VERSION "eCMP INFO-DIV vehicle review 2026-11-03; 125000 bit/s; PSA-RE 67f7581e7622410efdbb29c7eda3b86982b9b450; Apache-2.0"

NS_ :

BS_:

BU_: AAS AMPLI AVP BCM BGP BSG BSI BTA BTEL BTT CDC CMB CRT DIAG_TOOL EDP_C EMF FMUX IC ICSV IDVR IVC_D MATT MDS OVIP PDS_C RAD RBG SDCM VTH WLC

BO_ 808 ICSV_EngineEcuData: 8 ICSV
 SG_ FlowPadding5 m3 : 63|8@0+ (1,0) [0|255] "raw"  BSI,MATT,CMB
 SG_ FirstData6 m1 : 63|8@0+ (1,0) [0|255] "raw"  BSI,MATT,CMB
 SG_ UnknownData7 m4 : 63|8@0+ (1,0) [0|255] "raw"  BSI,MATT,CMB
 SG_ ConsecutiveData7 m2 : 63|8@0+ (1,0) [0|255] "raw"  BSI,MATT,CMB
 SG_ SingleData7 m0 : 63|8@0+ (1,0) [0|255] "raw"  BSI,MATT,CMB
 SG_ FlowPadding4 m3 : 55|8@0+ (1,0) [0|255] "raw"  BSI,MATT,CMB
 SG_ FirstData5 m1 : 55|8@0+ (1,0) [0|255] "raw"  BSI,MATT,CMB
 SG_ UnknownData6 m4 : 55|8@0+ (1,0) [0|255] "raw"  BSI,MATT,CMB
 SG_ ConsecutiveData6 m2 : 55|8@0+ (1,0) [0|255] "raw"  BSI,MATT,CMB
 SG_ SingleData6 m0 : 55|8@0+ (1,0) [0|255] "raw"  BSI,MATT,CMB
 SG_ FlowPadding3 m3 : 47|8@0+ (1,0) [0|255] "raw"  BSI,MATT,CMB
 SG_ FirstData4 m1 : 47|8@0+ (1,0) [0|255] "raw"  BSI,MATT,CMB
 SG_ UnknownData5 m4 : 47|8@0+ (1,0) [0|255] "raw"  BSI,MATT,CMB
 SG_ ConsecutiveData5 m2 : 47|8@0+ (1,0) [0|255] "raw"  BSI,MATT,CMB
 SG_ SingleData5 m0 : 47|8@0+ (1,0) [0|255] "raw"  BSI,MATT,CMB
 SG_ FlowPadding2 m3 : 39|8@0+ (1,0) [0|255] "raw"  BSI,MATT,CMB
 SG_ FirstData3 m1 : 39|8@0+ (1,0) [0|255] "raw"  BSI,MATT,CMB
 SG_ UnknownData4 m4 : 39|8@0+ (1,0) [0|255] "raw"  BSI,MATT,CMB
 SG_ ConsecutiveData4 m2 : 39|8@0+ (1,0) [0|255] "raw"  BSI,MATT,CMB
 SG_ SingleData4 m0 : 39|8@0+ (1,0) [0|255] "raw"  BSI,MATT,CMB
 SG_ FlowPadding1 m3 : 31|8@0+ (1,0) [0|255] "raw"  BSI,MATT,CMB
 SG_ FirstData2 m1 : 31|8@0+ (1,0) [0|255] "raw"  BSI,MATT,CMB
 SG_ UnknownData3 m4 : 31|8@0+ (1,0) [0|255] "raw"  BSI,MATT,CMB
 SG_ ConsecutiveData3 m2 : 31|8@0+ (1,0) [0|255] "raw"  BSI,MATT,CMB
 SG_ SingleData3 m0 : 31|8@0+ (1,0) [0|255] "raw"  BSI,MATT,CMB
 SG_ FirstData1 m1 : 23|8@0+ (1,0) [0|255] "raw"  BSI,MATT,CMB
 SG_ UnknownData2 m4 : 23|8@0+ (1,0) [0|255] "raw"  BSI,MATT,CMB
 SG_ ConsecutiveData2 m2 : 23|8@0+ (1,0) [0|255] "raw"  BSI,MATT,CMB
 SG_ SingleData2 m0 : 23|8@0+ (1,0) [0|255] "raw"  BSI,MATT,CMB
 SG_ SeparationTimeRaw m3 : 23|8@0+ (1,0) [0|255] "raw"  BSI,MATT,CMB
 SG_ UnknownData1 m4 : 15|8@0+ (1,0) [0|255] "raw"  BSI,MATT,CMB
 SG_ ConsecutiveData1 m2 : 15|8@0+ (1,0) [0|255] "raw"  BSI,MATT,CMB
 SG_ SingleData1 m0 : 15|8@0+ (1,0) [0|255] "raw"  BSI,MATT,CMB
 SG_ BlockSize m3 : 15|8@0+ (1,0) [0|255] "raw"  BSI,MATT,CMB
 SG_ UnknownPciLow m4 : 3|4@0+ (1,0) [0|15] "raw"  BSI,MATT,CMB
 SG_ FlowStatus m3 : 3|4@0+ (1,0) [0|15] "raw"  BSI,MATT,CMB
 SG_ ConsecutiveSequence m2 : 3|4@0+ (1,0) [0|15] "raw"  BSI,MATT,CMB
 SG_ FirstFrameLength m1 : 3|12@0+ (1,0) [0|4095] "raw"  BSI,MATT,CMB
 SG_ SingleFrameLength m0 : 3|4@0+ (1,0) [0|15] "raw"  BSI,MATT,CMB
 SG_ IsoTpFrameType M : 7|4@0+ (1,0) [0|15] ""  BSI,MATT,CMB

BO_ 809 BTEL_StopStartGearboxData: 8 BTEL
 SG_ RawByte8 : 63|8@0+ (1,0) [0|255] "raw" Vector__XXX
 SG_ RawByte7 : 55|8@0+ (1,0) [0|255] "raw" Vector__XXX
 SG_ Unused1 : 41|2@0+ (1,0) [0|3] ""  BSI,IDVR,AAS,RAD
 SG_ EnergyRecoveryButtonPressed : 42|1@0+ (1,0) [0|1] ""  BSI,IDVR,AAS,RAD
 SG_ AvasButtonPressed : 43|1@0+ (1,0) [0|1] ""  BSI,IDVR,AAS,RAD
 SG_ OutsideAirQualityBadLevel : 46|3@0+ (1,0) [0|7] ""  BSI,IDVR,AAS,RAD
 SG_ NightVisionToggleRequest : 47|1@0+ (1,0) [0|1] ""  BSI,IDVR,AAS,RAD
 SG_ AutomaticParkingSideRequest : 32|1@0+ (1,0) [0|1] ""  BSI,IDVR,AAS,RAD
 SG_ AutomaticParkingActivatio_012211 : 33|1@0+ (1,0) [0|1] ""  BSI,IDVR,AAS,RAD
 SG_ CabinAirFilterResetRequest : 34|1@0+ (1,0) [0|1] ""  BSI,IDVR,AAS,RAD
 SG_ CabinAirPurifierModeRequest : 37|3@0+ (1,0) [0|7] ""  BSI,IDVR,AAS,RAD
 SG_ OutsideAirQualityLevel : 39|2@0+ (1,0) [0|3] ""  BSI,IDVR,AAS,RAD
 SG_ AsrInhibitRequest : 24|1@0+ (1,0) [0|1] ""  BSI,IDVR,AAS,RAD
 SG_ ConsumptionHistoryZoomLevel : 26|2@0+ (1,0) [0|3] ""  BSI,IDVR,AAS,RAD
 SG_ ConsumptionHistoryResetRequest : 27|1@0+ (1,0) [0|1] ""  BSI,IDVR,AAS,RAD
 SG_ DynamicModeTouchSelection : 31|4@0+ (1,0) [0|15] ""  BSI,IDVR,AAS,RAD
 SG_ EcoachTripResetRequest : 16|1@0+ (1,0) [0|1] ""  BSI,IDVR,AAS,RAD
 SG_ MassageActivationCommand : 17|1@0+ (1,0) [0|1] ""  BSI,IDVR,AAS,RAD
 SG_ MassageIntensityCommand : 19|2@0+ (1,0) [0|3] ""  BSI,IDVR,AAS,RAD
 SG_ MassageTypeCommand : 23|4@0+ (1,0) [0|15] ""  BSI,IDVR,AAS,RAD
 SG_ FrontMassageSeatSelectionCommand : 9|2@0+ (1,0) [0|3] ""  BSI,IDVR,AAS,RAD
 SG_ FragranceSelectionRequest : 11|2@0+ (1,0) [0|3] ""  BSI,IDVR,AAS,RAD
 SG_ FragranceIntensityRequest : 13|2@0+ (1,0) [0|3] ""  BSI,IDVR,AAS,RAD
 SG_ FragranceDiffuserActivati_99a752 : 15|2@0+ (1,0) [0|3] ""  BSI,IDVR,AAS,RAD
 SG_ FragranceCartridgeMonoStatus : 1|2@0+ (1,0) [0|3] ""  BSI,IDVR,AAS,RAD
 SG_ IonizerActivationRequest : 3|2@0+ (1,0) [0|3] ""  BSI,IDVR,AAS,RAD
 SG_ LkaButtonPressed : 4|1@0+ (1,0) [0|1] ""  BSI,IDVR,AAS,RAD
 SG_ AsrPlusModeSelection : 6|2@0+ (1,0) [0|3] ""  BSI,IDVR,AAS,RAD
 SG_ FunctionSelectionRequest : 7|1@0+ (1,0) [0|1] ""  BSI,IDVR,AAS,RAD

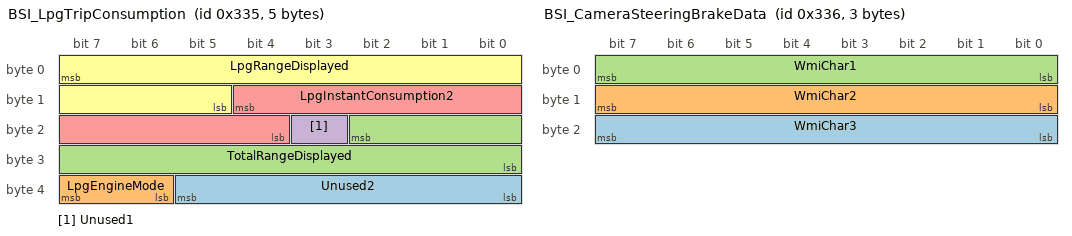
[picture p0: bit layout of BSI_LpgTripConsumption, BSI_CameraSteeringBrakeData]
BO_ 821 BSI_LpgTripConsumption: 5 BSI
 SG_ Unused2 : 37|6@0+ (1,0) [0|63] ""  BTEL,CMB,MATT
 SG_ LpgEngineMode : 39|2@0+ (1,0) [0|3] ""  BTEL,CMB,MATT
 SG_ TotalRangeDisplayed : 18|11@0+ (1,0) [0|2000] "km"  BTEL,CMB,MATT
 SG_ Unused1 : 19|1@0+ (1,0) [0|1] ""  BTEL,CMB,MATT
 SG_ LpgInstantConsumption2 : 12|9@0+ (0.1,0) [0|30] "L/100km"  BTEL,CMB,MATT
 SG_ LpgRangeDisplayed : 7|11@0+ (1,0) [0|2000] "km"  BTEL,CMB,MATT

BO_ 822 BSI_CameraSteeringBrakeData: 3 BSI
 SG_ WmiChar3 : 23|8@0+ (1,0) [0|255] "raw"  BTEL,CMB,EMF,CDC,RAD,MDS,MATT,BGP,OVIP
 SG_ WmiChar2 : 15|8@0+ (1,0) [0|255] "raw"  BTEL,CMB,EMF,CDC,RAD,MDS,MATT,BGP,OVIP
 SG_ WmiChar1 : 7|8@0+ (1,0) [0|255] "raw"  BTEL,CMB,EMF,CDC,RAD,MDS,MATT,BGP,OVIP

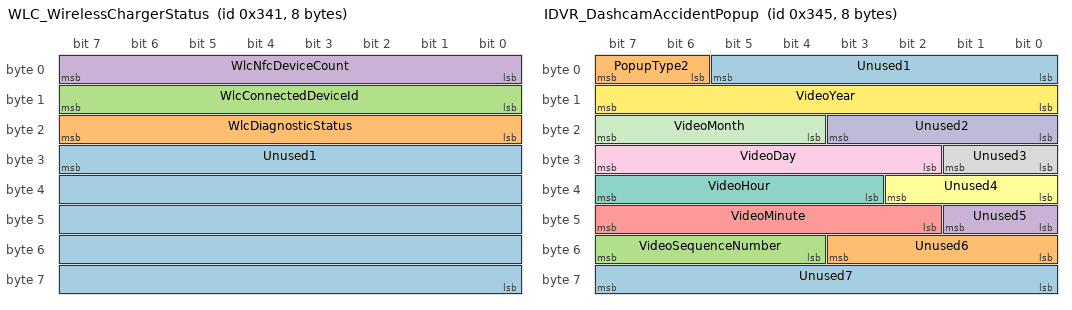
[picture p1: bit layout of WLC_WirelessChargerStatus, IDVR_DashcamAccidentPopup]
BO_ 833 WLC_WirelessChargerStatus: 8 WLC
 SG_ Unused1 : 31|40@0+ (1,0) [0|1099511627775] ""  SDCM
 SG_ WlcDiagnosticStatus : 23|8@0+ (1,0) [0|255] ""  SDCM
 SG_ WlcConnectedDeviceId : 15|8@0+ (1,0) [0|255] ""  SDCM
 SG_ WlcNfcDeviceCount : 7|8@0+ (1,0) [0|255] ""  SDCM

BO_ 835 BTEL_OdiDynamicDataListRe_1b7878: 8 BTEL
 SG_ OdiDynDataListRequestCent_4a34c1 : 7|64@0+ (1,0) [0|18446744073709551615] ""  MDS

BO_ 837 IDVR_DashcamAccidentPopup: 8 IDVR
 SG_ Unused7 : 63|8@0+ (1,0) [0|255] ""  BTEL,OVIP
 SG_ Unused6 : 51|4@0+ (1,0) [0|15] ""  BTEL,OVIP
 SG_ VideoSequenceNumber : 55|4@0+ (1,0) [0|9] ""  BTEL,OVIP
 SG_ Unused5 : 41|2@0+ (1,0) [0|3] ""  BTEL,OVIP
 SG_ VideoMinute : 47|6@0+ (1,0) [0|59] ""  BTEL,OVIP
 SG_ Unused4 : 34|3@0+ (1,0) [0|7] ""  BTEL,OVIP
 SG_ VideoHour : 39|5@0+ (1,0) [0|24] ""  BTEL,OVIP
 SG_ Unused3 : 25|2@0+ (1,0) [0|3] ""  BTEL,OVIP
 SG_ VideoDay : 31|6@0+ (1,0) [1|31] "day"  BTEL,OVIP
 SG_ Unused2 : 19|4@0+ (1,0) [0|15] ""  BTEL,OVIP
 SG_ VideoMonth : 23|4@0+ (1,0) [1|12] "month"  BTEL,OVIP
 SG_ VideoYear : 15|8@0+ (1,2000) [2000|2254] "year"  BTEL,OVIP
 SG_ Unused1 : 5|6@0+ (1,0) [0|63] ""  BTEL,OVIP
 SG_ PopupType2 : 7|2@0+ (1,0) [0|3] ""  BTEL,OVIP

BO_ 848 ICSV_FrontClimateStatus: 8 ICSV
 SG_ Unused1 : 56|1@0+ (1,0) [0|1] ""  CMB,BSI,BTEL,OVIP,CRT,RAD
 SG_ FrontRightSeatVentilationRequest : 58|2@0+ (1,0) [0|3] ""  CMB,BSI,BTEL,OVIP,CRT,RAD
 SG_ FrontLeftSeatHeatingRequest : 60|2@0+ (1,0) [0|3] ""  CMB,BSI,BTEL,OVIP,CRT,RAD
 SG_ FrontRightSeatHeatingRequest : 62|2@0+ (1,0) [0|3] ""  CMB,BSI,BTEL,OVIP,CRT,RAD
 SG_ EnergySaverModeStatus : 63|1@0+ (1,0) [0|1] ""  CMB,BSI,BTEL,OVIP,CRT,RAD
 SG_ FrontRightAirflowDistribution : 51|4@0+ (1,0) [0|15] ""  CMB,BSI,BTEL,OVIP,CRT,RAD
 SG_ FrontLeftAirflowDistribution : 55|4@0+ (1,0) [0|15] ""  CMB,BSI,BTEL,OVIP,CRT,RAD
 SG_ FrontBlowerManualSpeedDisplay : 43|4@0+ (1,0) [0|15] ""  CMB,BSI,BTEL,OVIP,CRT,RAD
 SG_ Mode : 46|3@0+ (1,0) [0|7] ""  CMB,BSI,BTEL,OVIP,CRT,RAD
 SG_ AqsStatus : 47|1@0+ (1,0) [0|1] ""  CMB,BSI,BTEL,OVIP,CRT,RAD
 SG_ FrontRightTempSetpointValue : 36|5@0+ (1,0) [0|31] ""  CMB,BSI,BTEL,OVIP,CRT,RAD
 SG_ FrontLeftSeatVentilationRequest : 38|2@0+ (1,0) [0|3] ""  CMB,BSI,BTEL,OVIP,CRT,RAD
 SG_ HeatedWindscreenActivatio_b0408e : 39|1@0+ (1,0) [0|1] ""  CMB,BSI,BTEL,OVIP,CRT,RAD
 SG_ FrontLeftTempSetpointValue : 28|5@0+ (1,0) [0|31] ""  CMB,BSI,BTEL,OVIP,CRT,RAD
 SG_ RestoreFlagStatus : 29|1@0+ (1,0) [0|1] ""  CMB,BSI,BTEL,OVIP,CRT,RAD
 SG_ MonoModeStatus : 30|1@0+ (1,0) [0|1] ""  CMB,BSI,BTEL,OVIP,CRT,RAD
 SG_ AcMaxStatus : 31|1@0+ (1,0) [0|1] ""  CMB,BSI,BTEL,OVIP,CRT,RAD
 SG_ EvaporatorSensorTemperature : 15|16@0+ (0.1,-40) [-40|85] ""  CMB,BSI,BTEL,OVIP,CRT,RAD
 SG_ AcType : 1|2@0+ (1,0) [0|3] ""  CMB,BSI,BTEL,OVIP,CRT,RAD
 SG_ AcModeRequest : 3|2@0+ (1,0) [0|3] ""  CMB,BSI,BTEL,OVIP,CRT,RAD
 SG_ VisibilityRequest : 4|1@0+ (1,0) [0|1] ""  CMB,BSI,BTEL,OVIP,CRT,RAD
 SG_ RearWindshieldHeat : 5|1@0+ (1,0) [0|1] ""  CMB,BSI,BTEL,OVIP,CRT,RAD
 SG_ RestModeStatus : 6|1@0+ (1,0) [0|1] ""  CMB,BSI,BTEL,OVIP,CRT,RAD
 SG_ FrontBlowerMotorFault : 7|1@0+ (1,0) [0|1] ""  CMB,BSI,BTEL,OVIP,CRT,RAD

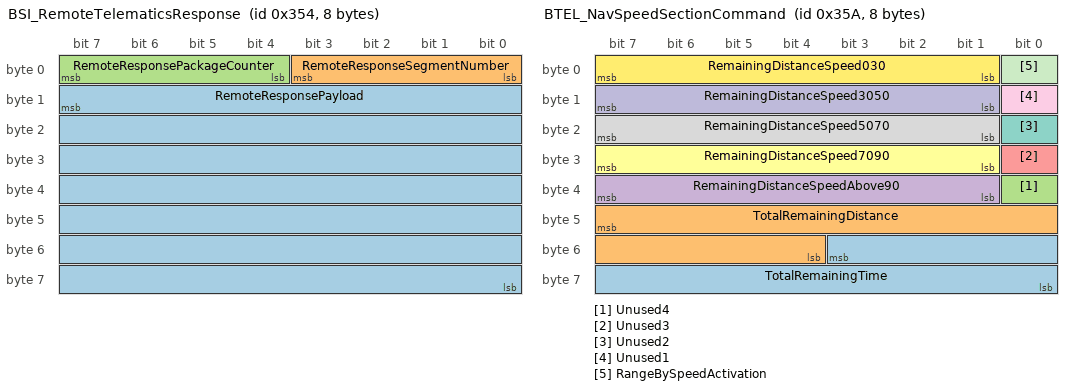
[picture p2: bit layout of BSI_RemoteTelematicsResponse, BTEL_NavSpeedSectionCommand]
BO_ 852 BSI_RemoteTelematicsResponse: 8 BSI
 SG_ RemoteResponsePayload : 15|56@0+ (1,0) [0|72057594037927935] ""  MDS
 SG_ RemoteResponseSegmentNumber : 3|4@0+ (1,0) [0|15] ""  MDS
 SG_ RemoteResponsePackageCounter : 7|4@0+ (1,0) [0|15] ""  MDS

BO_ 858 BTEL_NavSpeedSectionCommand: 8 BTEL
 SG_ TotalRemainingTime : 51|12@0+ (1,0) [0|4095] "min"  BSI
 SG_ TotalRemainingDistance : 47|12@0+ (1,0) [0|4095] "km"  BSI
 SG_ Unused4 : 32|1@0+ (1,0) [0|1] ""  BSI
 SG_ RemainingDistanceSpeedAbove90 : 39|7@0+ (1,0) [0|100] "%"  BSI
 SG_ Unused3 : 24|1@0+ (1,0) [0|1] ""  BSI
 SG_ RemainingDistanceSpeed7090 : 31|7@0+ (1,0) [0|100] "%"  BSI
 SG_ Unused2 : 16|1@0+ (1,0) [0|1] ""  BSI
 SG_ RemainingDistanceSpeed5070 : 23|7@0+ (1,0) [0|100] "%"  BSI
 SG_ Unused1 : 8|1@0+ (1,0) [0|1] ""  BSI
 SG_ RemainingDistanceSpeed3050 : 15|7@0+ (1,0) [0|100] "%"  BSI
 SG_ RangeBySpeedActivation : 0|1@0+ (1,0) [0|1] ""  BSI
 SG_ RemainingDistanceSpeed030 : 7|7@0+ (1,0) [0|100] "%"  BSI

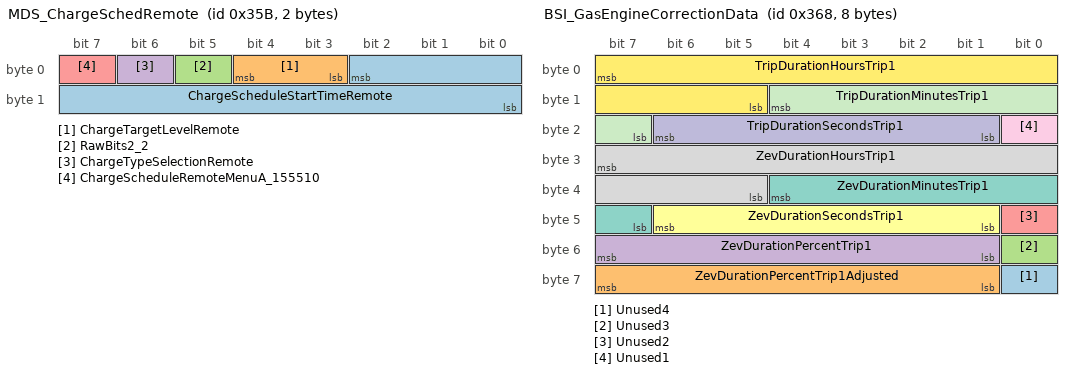
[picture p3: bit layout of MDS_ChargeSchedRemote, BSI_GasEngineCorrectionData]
BO_ 859 MDS_ChargeSchedRemote: 2 MDS
 SG_ ChargeScheduleStartTimeRemote : 2|11@0+ (1,0) [0|1440] "min"  BSI
 SG_ ChargeTargetLevelRemote : 4|2@0+ (1,0) [0|3] ""  BSI
 SG_ RawBits2_2 : 5|1@0+ (1,0) [0|1] "raw" Vector__XXX
 SG_ ChargeTypeSelectionRemote : 6|1@0+ (1,0) [0|1] ""  BSI
 SG_ ChargeScheduleRemoteMenuA_155510 : 7|1@0+ (1,0) [0|1] ""  BSI

BO_ 863 EMF_NavDatabaseStatusAckRep: 1 EMF
 SG_ SegmentationAckStream : 7|8@0+ (1,0) [0|255] ""  RAD

BO_ 864 ICSV_VehicleParameterData: 8 ICSV
 SG_ FlowPadding5 m3 : 63|8@0+ (1,0) [0|255] "raw"  BTEL,OVIP
 SG_ FirstData6 m1 : 63|8@0+ (1,0) [0|255] "raw"  BTEL,OVIP
 SG_ UnknownData7 m4 : 63|8@0+ (1,0) [0|255] "raw"  BTEL,OVIP
 SG_ ConsecutiveData7 m2 : 63|8@0+ (1,0) [0|255] "raw"  BTEL,OVIP
 SG_ SingleData7 m0 : 63|8@0+ (1,0) [0|255] "raw"  BTEL,OVIP
 SG_ FlowPadding4 m3 : 55|8@0+ (1,0) [0|255] "raw"  BTEL,OVIP
 SG_ FirstData5 m1 : 55|8@0+ (1,0) [0|255] "raw"  BTEL,OVIP
 SG_ UnknownData6 m4 : 55|8@0+ (1,0) [0|255] "raw"  BTEL,OVIP
 SG_ ConsecutiveData6 m2 : 55|8@0+ (1,0) [0|255] "raw"  BTEL,OVIP
 SG_ SingleData6 m0 : 55|8@0+ (1,0) [0|255] "raw"  BTEL,OVIP
 SG_ FlowPadding3 m3 : 47|8@0+ (1,0) [0|255] "raw"  BTEL,OVIP
 SG_ FirstData4 m1 : 47|8@0+ (1,0) [0|255] "raw"  BTEL,OVIP
 SG_ UnknownData5 m4 : 47|8@0+ (1,0) [0|255] "raw"  BTEL,OVIP
 SG_ ConsecutiveData5 m2 : 47|8@0+ (1,0) [0|255] "raw"  BTEL,OVIP
 SG_ SingleData5 m0 : 47|8@0+ (1,0) [0|255] "raw"  BTEL,OVIP
 SG_ FlowPadding2 m3 : 39|8@0+ (1,0) [0|255] "raw"  BTEL,OVIP
 SG_ FirstData3 m1 : 39|8@0+ (1,0) [0|255] "raw"  BTEL,OVIP
 SG_ UnknownData4 m4 : 39|8@0+ (1,0) [0|255] "raw"  BTEL,OVIP
 SG_ ConsecutiveData4 m2 : 39|8@0+ (1,0) [0|255] "raw"  BTEL,OVIP
 SG_ SingleData4 m0 : 39|8@0+ (1,0) [0|255] "raw"  BTEL,OVIP
 SG_ FlowPadding1 m3 : 31|8@0+ (1,0) [0|255] "raw"  BTEL,OVIP
 SG_ FirstData2 m1 : 31|8@0+ (1,0) [0|255] "raw"  BTEL,OVIP
 SG_ UnknownData3 m4 : 31|8@0+ (1,0) [0|255] "raw"  BTEL,OVIP
 SG_ ConsecutiveData3 m2 : 31|8@0+ (1,0) [0|255] "raw"  BTEL,OVIP
 SG_ SingleData3 m0 : 31|8@0+ (1,0) [0|255] "raw"  BTEL,OVIP
 SG_ FirstData1 m1 : 23|8@0+ (1,0) [0|255] "raw"  BTEL,OVIP
 SG_ UnknownData2 m4 : 23|8@0+ (1,0) [0|255] "raw"  BTEL,OVIP
 SG_ ConsecutiveData2 m2 : 23|8@0+ (1,0) [0|255] "raw"  BTEL,OVIP
 SG_ SingleData2 m0 : 23|8@0+ (1,0) [0|255] "raw"  BTEL,OVIP
 SG_ SeparationTimeRaw m3 : 23|8@0+ (1,0) [0|255] "raw"  BTEL,OVIP
 SG_ UnknownData1 m4 : 15|8@0+ (1,0) [0|255] "raw"  BTEL,OVIP
 SG_ ConsecutiveData1 m2 : 15|8@0+ (1,0) [0|255] "raw"  BTEL,OVIP
 SG_ SingleData1 m0 : 15|8@0+ (1,0) [0|255] "raw"  BTEL,OVIP
 SG_ BlockSize m3 : 15|8@0+ (1,0) [0|255] "raw"  BTEL,OVIP
 SG_ UnknownPciLow m4 : 3|4@0+ (1,0) [0|15] "raw"  BTEL,OVIP
 SG_ FlowStatus m3 : 3|4@0+ (1,0) [0|15] "raw"  BTEL,OVIP
 SG_ ConsecutiveSequence m2 : 3|4@0+ (1,0) [0|15] "raw"  BTEL,OVIP
 SG_ FirstFrameLength m1 : 3|12@0+ (1,0) [0|4095] "raw"  BTEL,OVIP
 SG_ SingleFrameLength m0 : 3|4@0+ (1,0) [0|15] "raw"  BTEL,OVIP
 SG_ IsoTpFrameType M : 7|4@0+ (1,0) [0|15] ""  BTEL,OVIP

BO_ 865 BSI_VehicleFeatureAvailability: 8 BSI
 SG_ RawByte8 : 63|8@0+ (1,0) [0|255] "raw" Vector__XXX
 SG_ Unused2 : 48|1@0+ (1,0) [0|1] ""  CMB,EMF,BTEL,MATT,OVIP,MDS,RAD
 SG_ RtabRechargeMenuDisplayAu_d73943 : 49|1@0+ (1,0) [0|1] ""  CMB,EMF,BTEL,MATT,OVIP,MDS,RAD
 SG_ ClimatePrecondMenuDisplay_2fd6ce : 50|1@0+ (1,0) [0|1] ""  CMB,EMF,BTEL,MATT,OVIP,MDS,RAD
 SG_ AmlaMenuPresence : 51|1@0+ (1,0) [0|1] ""  CMB,EMF,BTEL,MATT,OVIP,MDS,RAD
 SG_ AdsdMenuPresence : 52|1@0+ (1,0) [0|1] ""  CMB,EMF,BTEL,MATT,OVIP,MDS,RAD
 SG_ PrivacyModeMenuPresence : 53|1@0+ (1,0) [0|1] ""  CMB,EMF,BTEL,MATT,OVIP,MDS,RAD
 SG_ ArsMenuPresence : 54|1@0+ (1,0) [0|1] ""  CMB,EMF,BTEL,MATT,OVIP,MDS,RAD
 SG_ AfsMenuPresence : 55|1@0+ (1,0) [0|1] ""  CMB,EMF,BTEL,MATT,OVIP,MDS,RAD
 SG_ IrvMenuPresence : 40|1@0+ (1,0) [0|1] ""  CMB,EMF,BTEL,MATT,OVIP,MDS,RAD
 SG_ PolychromePackBlockMenuPresence : 41|1@0+ (1,0) [0|1] ""  CMB,EMF,BTEL,MATT,OVIP,MDS,RAD
 SG_ PpcAnimationPresence : 42|1@0+ (1,0) [0|1] ""  CMB,EMF,BTEL,MATT,OVIP,MDS,RAD
 SG_ Dae4wdPresence : 43|1@0+ (1,0) [0|1] ""  CMB,EMF,BTEL,MATT,OVIP,MDS,RAD
 SG_ DaePresence : 44|1@0+ (1,0) [0|1] ""  CMB,EMF,BTEL,MATT,OVIP,MDS,RAD
 SG_ CafrMenuPresence : 45|1@0+ (1,0) [0|1] ""  CMB,EMF,BTEL,MATT,OVIP,MDS,RAD
 SG_ EcsModeMenuPresence : 46|1@0+ (1,0) [0|1] ""  CMB,EMF,BTEL,MATT,OVIP,MDS,RAD
 SG_ DriverAlertAssistMenuPresence : 47|1@0+ (1,0) [0|1] ""  CMB,EMF,BTEL,MATT,OVIP,MDS,RAD
 SG_ LoadedArmsLockMenuPresence : 32|1@0+ (1,0) [0|1] ""  CMB,EMF,BTEL,MATT,OVIP,MDS,RAD
 SG_ UserProfilePresence : 33|1@0+ (1,0) [0|1] ""  CMB,EMF,BTEL,MATT,OVIP,MDS,RAD
 SG_ LoadedArmsAccessMenuPresence : 34|1@0+ (1,0) [0|1] ""  CMB,EMF,BTEL,MATT,OVIP,MDS,RAD
 SG_ IlvPresence : 35|1@0+ (1,0) [0|1] ""  CMB,EMF,BTEL,MATT,OVIP,MDS,RAD
 SG_ GrilleLightingPresence : 36|1@0+ (1,0) [0|1] ""  CMB,EMF,BTEL,MATT,OVIP,MDS,RAD
 SG_ LowCurrentChargePresence : 37|1@0+ (1,0) [0|1] ""  CMB,EMF,BTEL,MATT,OVIP,MDS,RAD
 SG_ Unused1 : 39|2@0+ (1,0) [0|3] ""  CMB,EMF,BTEL,MATT,OVIP,MDS,RAD
 SG_ TpmsPresence : 26|3@0+ (1,0) [0|7] ""  CMB,EMF,BTEL,MATT,OVIP,MDS,RAD
 SG_ IrcPresence : 27|1@0+ (1,0) [0|1] ""  CMB,EMF,BTEL,MATT,OVIP,MDS,RAD
 SG_ XvvSpeedMenuPresence : 28|1@0+ (1,0) [0|1] ""  CMB,EMF,BTEL,MATT,OVIP,MDS,RAD
 SG_ ArcSensitivityMenuPresence : 29|1@0+ (1,0) [0|1] ""  CMB,EMF,BTEL,MATT,OVIP,MDS,RAD
 SG_ CollisionRiskBrakingOptio_4c4434 : 30|1@0+ (1,0) [0|1] ""  CMB,EMF,BTEL,MATT,OVIP,MDS,RAD
 SG_ TpmsReinitializationOptio_aa6f62 : 31|1@0+ (1,0) [0|1] ""  CMB,EMF,BTEL,MATT,OVIP,MDS,RAD
 SG_ PpcPresence : 16|1@0+ (1,0) [0|1] ""  CMB,EMF,BTEL,MATT,OVIP,MDS,RAD
 SG_ EtsrMenuPresence : 17|1@0+ (1,0) [0|1] ""  CMB,EMF,BTEL,MATT,OVIP,MDS,RAD
 SG_ ReverseIndexingPresence : 18|1@0+ (1,0) [0|1] ""  CMB,EMF,BTEL,MATT,OVIP,MDS,RAD
 SG_ SoundHarmonyOptionPresence : 19|1@0+ (1,0) [0|1] ""  CMB,EMF,BTEL,MATT,OVIP,MDS,RAD
 SG_ ElectricParkingBrakeOptio_c6beca : 20|1@0+ (1,0) [0|1] ""  CMB,EMF,BTEL,MATT,OVIP,MDS,RAD
 SG_ CongigurableKeyOption : 21|1@0+ (1,0) [0|1] ""  CMB,EMF,BTEL,MATT,OVIP,MDS,RAD
 SG_ XvvLimitsMenuPresence : 22|1@0+ (1,0) [0|1] ""  CMB,EMF,BTEL,MATT,OVIP,MDS,RAD
 SG_ NblPresence : 23|1@0+ (1,0) [0|1] ""  CMB,EMF,BTEL,MATT,OVIP,MDS,RAD
 SG_ CabOpeningsSelectivityCus_fd4768 : 8|1@0+ (1,0) [0|1] ""  CMB,EMF,BTEL,MATT,OVIP,MDS,RAD
 SG_ DoorSelectivityOptionPresence : 9|1@0+ (1,0) [0|1] ""  CMB,EMF,BTEL,MATT,OVIP,MDS,RAD
 SG_ RearOpeningsSelectivityOp_53876f : 10|1@0+ (1,0) [0|1] ""  CMB,EMF,BTEL,MATT,OVIP,MDS,RAD
 SG_ RearFlapMotorizationCusto_5e7171 : 11|1@0+ (1,0) [0|1] ""  CMB,EMF,BTEL,MATT,OVIP,MDS,RAD
 SG_ DriverGreetingPresence : 12|1@0+ (1,0) [0|1] ""  CMB,EMF,BTEL,MATT,OVIP,MDS,RAD
 SG_ FollowMeHomeOptionPresence : 13|1@0+ (1,0) [0|1] ""  CMB,EMF,BTEL,MATT,OVIP,MDS,RAD
 SG_ RearWiperInReverseOptionPresence : 14|1@0+ (1,0) [0|1] ""  CMB,EMF,BTEL,MATT,OVIP,MDS,RAD
 SG_ ParkingAidInhibitionOptio_937dc5 : 15|1@0+ (1,0) [0|1] ""  CMB,EMF,BTEL,MATT,OVIP,MDS,RAD
 SG_ DaylightsOptionPresence : 0|1@0+ (1,0) [0|1] ""  CMB,EMF,BTEL,MATT,OVIP,MDS,RAD
 SG_ AutomaticHeadlightsSwitch_2a5f4f : 1|1@0+ (1,0) [0|1] ""  CMB,EMF,BTEL,MATT,OVIP,MDS,RAD
 SG_ AmbientLightingPresence : 2|1@0+ (1,0) [0|1] ""  CMB,EMF,BTEL,MATT,OVIP,MDS,RAD
 SG_ BlindSpotMonitoringPresence : 3|1@0+ (1,0) [0|1] ""  CMB,EMF,BTEL,MATT,OVIP,MDS,RAD
 SG_ AdaptiveLightingOptionPresence : 4|1@0+ (1,0) [0|1] ""  CMB,EMF,BTEL,MATT,OVIP,MDS,RAD
 SG_ UnlockingLightingCustomiz_78a725 : 5|1@0+ (1,0) [0|1] ""  CMB,EMF,BTEL,MATT,OVIP,MDS,RAD
 SG_ MotorwayLightingFunctionPresence : 6|1@0+ (1,0) [0|1] ""  CMB,EMF,BTEL,MATT,OVIP,MDS,RAD
 SG_ SettingsMenuInfoAvailability : 7|1@0+ (1,0) [0|1] ""  CMB,EMF,BTEL,MATT,OVIP,MDS,RAD

BO_ 868 BTEL_TouchClimatePanelStatus: 7 BTEL
 SG_ RawByte7 : 55|8@0+ (1,0) [0|255] "raw" Vector__XXX
 SG_ Unused1 : 43|4@0+ (1,0) [0|15] ""  ICSV,CMB,FMUX,BSI
 SG_ FrontLeftSeatVentilationButton : 44|1@0+ (1,0) [0|1] ""  ICSV,CMB,FMUX,BSI
 SG_ FrontRightSeatVentilationButton : 45|1@0+ (1,0) [0|1] ""  ICSV,CMB,FMUX,BSI
 SG_ FrontLeftSeatHeaterButton : 46|1@0+ (1,0) [0|1] ""  ICSV,CMB,FMUX,BSI
 SG_ FrontRightSeatHeaterButton : 47|1@0+ (1,0) [0|1] ""  ICSV,CMB,FMUX,BSI
 SG_ AcOffButton : 32|1@0+ (1,0) [0|1] ""  ICSV,CMB,FMUX,BSI
 SG_ ClimateSliderLevelChange : 33|1@0+ (1,0) [0|1] ""  ICSV,CMB,FMUX,BSI
 SG_ RearClimateLockButton : 34|1@0+ (1,0) [0|1] ""  ICSV,CMB,FMUX,BSI
 SG_ FrontRightDefrostButton : 35|1@0+ (1,0) [0|1] ""  ICSV,CMB,FMUX,BSI
 SG_ FrontFanLevelSlider : 39|4@0+ (1,0) [0|15] ""  ICSV,CMB,FMUX,BSI
 SG_ FrontRightVentAirflowButton : 24|1@0+ (1,0) [0|1] ""  ICSV,CMB,FMUX,BSI
 SG_ FrontRightFootAirflowButton : 25|1@0+ (1,0) [0|1] ""  ICSV,CMB,FMUX,BSI
 SG_ FrontRightTempLevelSlider : 30|5@0+ (1,0) [0|31] ""  ICSV,CMB,FMUX,BSI
 SG_ EnergySaverModeButton : 31|1@0+ (1,0) [0|1] ""  ICSV,CMB,FMUX,BSI
 SG_ FrontLeftTempSetpoint : 20|5@0+ (1,0) [0|31] ""  ICSV,CMB,FMUX,BSI
 SG_ RearClimateOnoffButton : 21|1@0+ (1,0) [0|1] ""  ICSV,CMB,FMUX,BSI
 SG_ AcMaxButton : 22|1@0+ (1,0) [0|1] ""  ICSV,CMB,FMUX,BSI
 SG_ AcAutoStrongButton : 23|1@0+ (1,0) [0|1] ""  ICSV,CMB,FMUX,BSI
 SG_ AcAutoNormalButton : 8|1@0+ (1,0) [0|1] ""  ICSV,CMB,FMUX,BSI
 SG_ AcAutoLightButton : 9|1@0+ (1,0) [0|1] ""  ICSV,CMB,FMUX,BSI
 SG_ AcAutoButton : 10|1@0+ (1,0) [0|1] ""  ICSV,CMB,FMUX,BSI
 SG_ AcButton : 11|1@0+ (1,0) [0|1] ""  ICSV,CMB,FMUX,BSI
 SG_ MonoZoneButton : 12|1@0+ (1,0) [0|1] ""  ICSV,CMB,FMUX,BSI
 SG_ AirQualitySensorButton : 13|1@0+ (1,0) [0|1] ""  ICSV,CMB,FMUX,BSI
 SG_ AirIntakeButton : 14|1@0+ (1,0) [0|1] ""  ICSV,CMB,FMUX,BSI
 SG_ FrontLeftDefrostButton : 15|1@0+ (1,0) [0|1] ""  ICSV,CMB,FMUX,BSI
 SG_ FrontLeftVentAirflowButton : 0|1@0+ (1,0) [0|1] ""  ICSV,CMB,FMUX,BSI
 SG_ FrontLeftFootAirflowButton : 1|1@0+ (1,0) [0|1] ""  ICSV,CMB,FMUX,BSI
 SG_ FrontFanMinusButton : 2|1@0+ (1,0) [0|1] ""  ICSV,CMB,FMUX,BSI
 SG_ FrontFanPlusButton : 3|1@0+ (1,0) [0|1] ""  ICSV,CMB,FMUX,BSI
 SG_ FrontRightTempMinusButton : 4|1@0+ (1,0) [0|1] ""  ICSV,CMB,FMUX,BSI
 SG_ FrontRightTempPlusButton : 5|1@0+ (1,0) [0|1] ""  ICSV,CMB,FMUX,BSI
 SG_ FrontLeftTempMinusButton : 6|1@0+ (1,0) [0|1] ""  ICSV,CMB,FMUX,BSI
 SG_ FrontLeftTempPlusButton : 7|1@0+ (1,0) [0|1] ""  ICSV,CMB,FMUX,BSI

BO_ 871 EMF_RadioStatusAckRep: 1 EMF
 SG_ SegmentationAckStream : 7|8@0+ (1,0) [0|255] ""  RAD

BO_ 872 BSI_GasEngineCorrectionData: 8 BSI
 SG_ Unused4 : 56|1@0+ (1,0) [0|1] ""  OVIP,RAD
 SG_ ZevDurationPercentTrip1Adjusted : 63|7@0+ (1,0) [0|100] "%"  OVIP,RAD
 SG_ Unused3 : 48|1@0+ (1,0) [0|1] ""  OVIP,RAD
 SG_ ZevDurationPercentTrip1 : 55|7@0+ (1,0) [0|100] "%"  OVIP,RAD
 SG_ Unused2 : 40|1@0+ (1,0) [0|1] ""  OVIP,RAD
 SG_ ZevDurationSecondsTrip1 : 46|6@0+ (1,0) [0|59] "s"  OVIP,RAD
 SG_ ZevDurationMinutesTrip1 : 36|6@0+ (1,0) [0|59] "min"  OVIP,RAD
 SG_ ZevDurationHoursTrip1 : 31|11@0+ (1,0) [0|2000] "h"  OVIP,RAD
 SG_ Unused1 : 16|1@0+ (1,0) [0|1] ""  OVIP,RAD
 SG_ TripDurationSecondsTrip1 : 22|6@0+ (1,0) [0|59] "s"  OVIP,RAD
 SG_ TripDurationMinutesTrip1 : 12|6@0+ (1,0) [0|59] "min"  OVIP,RAD
 SG_ TripDurationHoursTrip1 : 7|11@0+ (1,0) [0|2000] "h"  OVIP,RAD

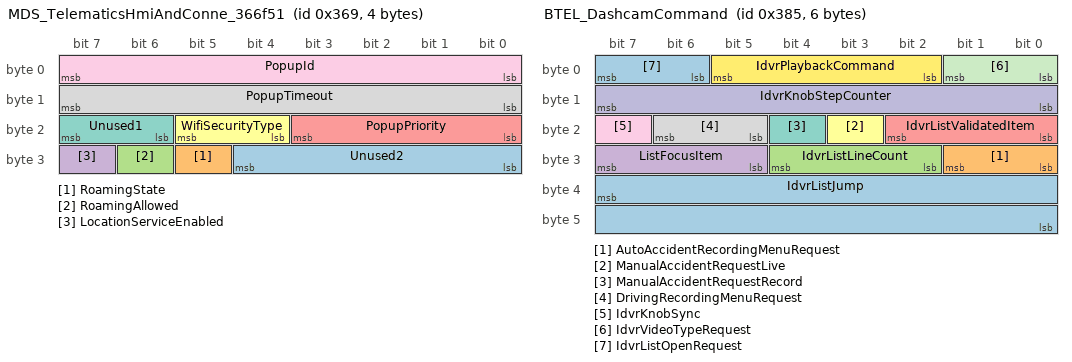
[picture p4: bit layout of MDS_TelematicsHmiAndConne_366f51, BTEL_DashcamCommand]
BO_ 873 MDS_TelematicsHmiAndConne_366f51: 4 MDS
 SG_ Unused2 : 28|5@0+ (1,0) [0|31] ""  BTEL,EMF,OVIP,BSI,RAD
 SG_ RoamingState : 29|1@0+ (1,0) [0|1] ""  BTEL,EMF,OVIP,BSI,RAD
 SG_ RoamingAllowed : 30|1@0+ (1,0) [0|1] ""  BTEL,EMF,OVIP,BSI,RAD
 SG_ LocationServiceEnabled : 31|1@0+ (1,0) [0|1] ""  BTEL,EMF,OVIP,BSI,RAD
 SG_ PopupPriority : 19|4@0+ (1,0) [0|15] ""  BTEL,EMF,OVIP,BSI,RAD
 SG_ WifiSecurityType : 21|2@0+ (1,0) [0|3] ""  BTEL,EMF,OVIP,BSI,RAD
 SG_ Unused1 : 23|2@0+ (1,0) [0|3] ""  BTEL,EMF,OVIP,BSI,RAD
 SG_ PopupTimeout : 15|8@0+ (1,0) [0|255] ""  BTEL,EMF,OVIP,BSI,RAD
 SG_ PopupId : 7|8@0+ (1,0) [0|255] ""  BTEL,EMF,OVIP,BSI,RAD

BO_ 886 BTEL_WifiInfoReplyFlowControl: 8 BTEL
 SG_ FlowPadding5 m3 : 63|8@0+ (1,0) [0|255] "raw"  MDS
 SG_ FirstData6 m1 : 63|8@0+ (1,0) [0|255] "raw"  MDS
 SG_ UnknownData7 m4 : 63|8@0+ (1,0) [0|255] "raw"  MDS
 SG_ ConsecutiveData7 m2 : 63|8@0+ (1,0) [0|255] "raw"  MDS
 SG_ SingleData7 m0 : 63|8@0+ (1,0) [0|255] "raw"  MDS
 SG_ FlowPadding4 m3 : 55|8@0+ (1,0) [0|255] "raw"  MDS
 SG_ FirstData5 m1 : 55|8@0+ (1,0) [0|255] "raw"  MDS
 SG_ UnknownData6 m4 : 55|8@0+ (1,0) [0|255] "raw"  MDS
 SG_ ConsecutiveData6 m2 : 55|8@0+ (1,0) [0|255] "raw"  MDS
 SG_ SingleData6 m0 : 55|8@0+ (1,0) [0|255] "raw"  MDS
 SG_ FlowPadding3 m3 : 47|8@0+ (1,0) [0|255] "raw"  MDS
 SG_ FirstData4 m1 : 47|8@0+ (1,0) [0|255] "raw"  MDS
 SG_ UnknownData5 m4 : 47|8@0+ (1,0) [0|255] "raw"  MDS
 SG_ ConsecutiveData5 m2 : 47|8@0+ (1,0) [0|255] "raw"  MDS
 SG_ SingleData5 m0 : 47|8@0+ (1,0) [0|255] "raw"  MDS
 SG_ FlowPadding2 m3 : 39|8@0+ (1,0) [0|255] "raw"  MDS
 SG_ FirstData3 m1 : 39|8@0+ (1,0) [0|255] "raw"  MDS
 SG_ UnknownData4 m4 : 39|8@0+ (1,0) [0|255] "raw"  MDS
 SG_ ConsecutiveData4 m2 : 39|8@0+ (1,0) [0|255] "raw"  MDS
 SG_ SingleData4 m0 : 39|8@0+ (1,0) [0|255] "raw"  MDS
 SG_ FlowPadding1 m3 : 31|8@0+ (1,0) [0|255] "raw"  MDS
 SG_ FirstData2 m1 : 31|8@0+ (1,0) [0|255] "raw"  MDS
 SG_ UnknownData3 m4 : 31|8@0+ (1,0) [0|255] "raw"  MDS
 SG_ ConsecutiveData3 m2 : 31|8@0+ (1,0) [0|255] "raw"  MDS
 SG_ SingleData3 m0 : 31|8@0+ (1,0) [0|255] "raw"  MDS
 SG_ FirstData1 m1 : 23|8@0+ (1,0) [0|255] "raw"  MDS
 SG_ UnknownData2 m4 : 23|8@0+ (1,0) [0|255] "raw"  MDS
 SG_ ConsecutiveData2 m2 : 23|8@0+ (1,0) [0|255] "raw"  MDS
 SG_ SingleData2 m0 : 23|8@0+ (1,0) [0|255] "raw"  MDS
 SG_ SeparationTimeRaw m3 : 23|8@0+ (1,0) [0|255] "raw"  MDS
 SG_ UnknownData1 m4 : 15|8@0+ (1,0) [0|255] "raw"  MDS
 SG_ ConsecutiveData1 m2 : 15|8@0+ (1,0) [0|255] "raw"  MDS
 SG_ SingleData1 m0 : 15|8@0+ (1,0) [0|255] "raw"  MDS
 SG_ BlockSize m3 : 15|8@0+ (1,0) [0|255] "raw"  MDS
 SG_ UnknownPciLow m4 : 3|4@0+ (1,0) [0|15] "raw"  MDS
 SG_ FlowStatus m3 : 3|4@0+ (1,0) [0|15] "raw"  MDS
 SG_ ConsecutiveSequence m2 : 3|4@0+ (1,0) [0|15] "raw"  MDS
 SG_ FirstFrameLength m1 : 3|12@0+ (1,0) [0|4095] "raw"  MDS
 SG_ SingleFrameLength m0 : 3|4@0+ (1,0) [0|15] "raw"  MDS
 SG_ IsoTpFrameType M : 7|4@0+ (1,0) [0|15] ""  MDS

BO_ 897 WLC_SdcmApduFlowControl: 8 WLC
 SG_ FlowPadding5 m3 : 63|8@0+ (1,0) [0|255] "raw"  SDCM
 SG_ FirstData6 m1 : 63|8@0+ (1,0) [0|255] "raw"  SDCM
 SG_ UnknownData7 m4 : 63|8@0+ (1,0) [0|255] "raw"  SDCM
 SG_ ConsecutiveData7 m2 : 63|8@0+ (1,0) [0|255] "raw"  SDCM
 SG_ SingleData7 m0 : 63|8@0+ (1,0) [0|255] "raw"  SDCM
 SG_ FlowPadding4 m3 : 55|8@0+ (1,0) [0|255] "raw"  SDCM
 SG_ FirstData5 m1 : 55|8@0+ (1,0) [0|255] "raw"  SDCM
 SG_ UnknownData6 m4 : 55|8@0+ (1,0) [0|255] "raw"  SDCM
 SG_ ConsecutiveData6 m2 : 55|8@0+ (1,0) [0|255] "raw"  SDCM
 SG_ SingleData6 m0 : 55|8@0+ (1,0) [0|255] "raw"  SDCM
 SG_ FlowPadding3 m3 : 47|8@0+ (1,0) [0|255] "raw"  SDCM
 SG_ FirstData4 m1 : 47|8@0+ (1,0) [0|255] "raw"  SDCM
 SG_ UnknownData5 m4 : 47|8@0+ (1,0) [0|255] "raw"  SDCM
 SG_ ConsecutiveData5 m2 : 47|8@0+ (1,0) [0|255] "raw"  SDCM
 SG_ SingleData5 m0 : 47|8@0+ (1,0) [0|255] "raw"  SDCM
 SG_ FlowPadding2 m3 : 39|8@0+ (1,0) [0|255] "raw"  SDCM
 SG_ FirstData3 m1 : 39|8@0+ (1,0) [0|255] "raw"  SDCM
 SG_ UnknownData4 m4 : 39|8@0+ (1,0) [0|255] "raw"  SDCM
 SG_ ConsecutiveData4 m2 : 39|8@0+ (1,0) [0|255] "raw"  SDCM
 SG_ SingleData4 m0 : 39|8@0+ (1,0) [0|255] "raw"  SDCM
 SG_ FlowPadding1 m3 : 31|8@0+ (1,0) [0|255] "raw"  SDCM
 SG_ FirstData2 m1 : 31|8@0+ (1,0) [0|255] "raw"  SDCM
 SG_ UnknownData3 m4 : 31|8@0+ (1,0) [0|255] "raw"  SDCM
 SG_ ConsecutiveData3 m2 : 31|8@0+ (1,0) [0|255] "raw"  SDCM
 SG_ SingleData3 m0 : 31|8@0+ (1,0) [0|255] "raw"  SDCM
 SG_ FirstData1 m1 : 23|8@0+ (1,0) [0|255] "raw"  SDCM
 SG_ UnknownData2 m4 : 23|8@0+ (1,0) [0|255] "raw"  SDCM
 SG_ ConsecutiveData2 m2 : 23|8@0+ (1,0) [0|255] "raw"  SDCM
 SG_ SingleData2 m0 : 23|8@0+ (1,0) [0|255] "raw"  SDCM
 SG_ SeparationTimeRaw m3 : 23|8@0+ (1,0) [0|255] "raw"  SDCM
 SG_ UnknownData1 m4 : 15|8@0+ (1,0) [0|255] "raw"  SDCM
 SG_ ConsecutiveData1 m2 : 15|8@0+ (1,0) [0|255] "raw"  SDCM
 SG_ SingleData1 m0 : 15|8@0+ (1,0) [0|255] "raw"  SDCM
 SG_ BlockSize m3 : 15|8@0+ (1,0) [0|255] "raw"  SDCM
 SG_ UnknownPciLow m4 : 3|4@0+ (1,0) [0|15] "raw"  SDCM
 SG_ FlowStatus m3 : 3|4@0+ (1,0) [0|15] "raw"  SDCM
 SG_ ConsecutiveSequence m2 : 3|4@0+ (1,0) [0|15] "raw"  SDCM
 SG_ FirstFrameLength m1 : 3|12@0+ (1,0) [0|4095] "raw"  SDCM
 SG_ SingleFrameLength m0 : 3|4@0+ (1,0) [0|15] "raw"  SDCM
 SG_ IsoTpFrameType M : 7|4@0+ (1,0) [0|15] ""  SDCM

BO_ 901 BTEL_DashcamCommand: 6 BTEL
 SG_ IdvrListJump : 39|16@0+ (1,0) [0|65534] ""  IDVR
 SG_ AutoAccidentRecordingMenuRequest : 25|2@0+ (1,0) [0|3] ""  IDVR
 SG_ IdvrListLineCount : 28|3@0+ (1,0) [1|6] ""  IDVR
 SG_ ListFocusItem : 31|3@0+ (1,0) [0|7] ""  IDVR
 SG_ IdvrListValidatedItem : 18|3@0+ (1,0) [0|7] ""  IDVR
 SG_ ManualAccidentRequestLive : 19|1@0+ (1,0) [0|1] ""  IDVR
 SG_ ManualAccidentRequestRecord : 20|1@0+ (1,0) [0|1] ""  IDVR
 SG_ DrivingRecordingMenuRequest : 22|2@0+ (1,0) [0|3] ""  IDVR
 SG_ IdvrKnobSync : 23|1@0+ (1,0) [0|1] ""  IDVR
 SG_ IdvrKnobStepCounter : 15|8@0+ (1,0) [0|255] ""  IDVR
 SG_ IdvrVideoTypeRequest : 1|2@0+ (1,0) [0|3] ""  IDVR
 SG_ IdvrPlaybackCommand : 5|4@0+ (1,0) [0|15] ""  IDVR
 SG_ IdvrListOpenRequest : 7|2@0+ (1,0) [0|3] ""  IDVR

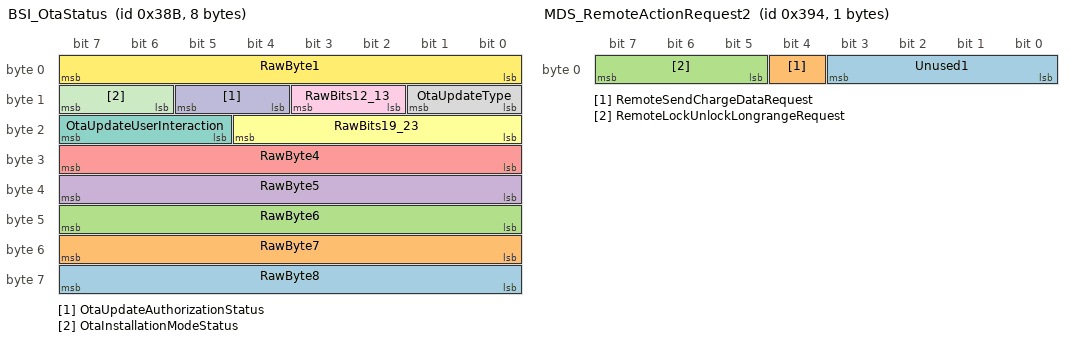
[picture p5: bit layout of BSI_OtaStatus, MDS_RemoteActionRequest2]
BO_ 907 BSI_OtaStatus: 8 BSI
 SG_ RawByte8 : 63|8@0+ (1,0) [0|255] "raw" Vector__XXX
 SG_ RawByte7 : 55|8@0+ (1,0) [0|255] "raw" Vector__XXX
 SG_ RawByte6 : 47|8@0+ (1,0) [0|255] "raw" Vector__XXX
 SG_ RawByte5 : 39|8@0+ (1,0) [0|255] "raw" Vector__XXX
 SG_ RawByte4 : 31|8@0+ (1,0) [0|255] "raw" Vector__XXX
 SG_ RawBits19_23 : 20|5@0+ (1,0) [0|31] "raw" Vector__XXX
 SG_ OtaUpdateUserInteraction : 23|3@0+ (1,0) [0|7] ""  BTEL
 SG_ OtaUpdateType : 9|2@0+ (1,0) [0|3] ""  BTEL
 SG_ RawBits12_13 : 11|2@0+ (1,0) [0|3] "raw" Vector__XXX
 SG_ OtaUpdateAuthorizationStatus : 13|2@0+ (1,0) [0|3] ""  BTEL
 SG_ OtaInstallationModeStatus : 15|2@0+ (1,0) [0|3] ""  BTEL
 SG_ RawByte1 : 7|8@0+ (1,0) [0|255] "raw" Vector__XXX

BO_ 916 MDS_RemoteActionRequest2: 1 MDS
 SG_ Unused1 : 3|4@0+ (1,0) [0|15] ""  BSI
 SG_ RemoteSendChargeDataRequest : 4|1@0+ (1,0) [0|1] ""  BSI
 SG_ RemoteLockUnlockLongrangeRequest : 7|3@0+ (1,0) [0|7] ""  BSI

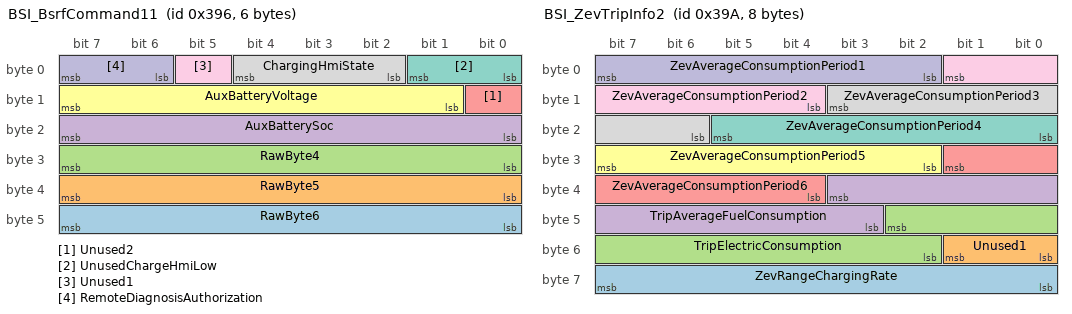
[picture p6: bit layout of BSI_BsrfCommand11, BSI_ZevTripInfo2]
BO_ 918 BSI_BsrfCommand11: 6 BSI
 SG_ RawByte6 : 47|8@0+ (1,0) [0|255] "raw" Vector__XXX
 SG_ RawByte5 : 39|8@0+ (1,0) [0|255] "raw" Vector__XXX
 SG_ RawByte4 : 31|8@0+ (1,0) [0|255] "raw" Vector__XXX
 SG_ AuxBatterySoc : 23|8@0+ (0.5,0) [0|100] "%"  MDS
 SG_ Unused2 : 8|1@0+ (1,0) [0|1] ""  MDS
 SG_ AuxBatteryVoltage : 15|7@0+ (0.1,5.5) [5.5|18.1] "V"  MDS
 SG_ UnusedChargeHmiLow : 1|2@0+ (1,0) [0|3] ""  MDS
 SG_ ChargingHmiState : 4|3@0+ (1,0) [0|7] ""  MDS
 SG_ Unused1 : 5|1@0+ (1,0) [0|1] ""  MDS
 SG_ RemoteDiagnosisAuthorization : 7|2@0+ (1,0) [0|3] ""  MDS

BO_ 922 BSI_ZevTripInfo2: 8 BSI
 SG_ ZevRangeChargingRate : 63|8@0+ (2,0) [0|500] "km"  CMB,OVIP
 SG_ Unused1 : 49|2@0+ (1,0) [0|3] ""  CMB,OVIP
 SG_ TripElectricConsumption : 42|9@0+ (0.1,0) [0|50] "kWh/100km"  CMB,OVIP
 SG_ TripAverageFuelConsumption : 35|9@0+ (0.1,0) [0|30] "L/100km"  CMB,OVIP
 SG_ ZevAverageConsumptionPeriod6 : 25|6@0+ (1,0) [0|50] "kWh/100km"  CMB,OVIP
 SG_ ZevAverageConsumptionPeriod5 : 31|6@0+ (1,0) [0|50] "kWh/100km"  CMB,OVIP
 SG_ ZevAverageConsumptionPeriod4 : 21|6@0+ (1,0) [0|50] "kWh/100km"  CMB,OVIP
 SG_ ZevAverageConsumptionPeriod3 : 11|6@0+ (1,0) [0|50] "kWh/100km"  CMB,OVIP
 SG_ ZevAverageConsumptionPeriod2 : 1|6@0+ (1,0) [0|50] "kWh/100km"  CMB,OVIP
 SG_ ZevAverageConsumptionPeriod1 : 7|6@0+ (1,0) [0|50] "kWh/100km"  CMB,OVIP

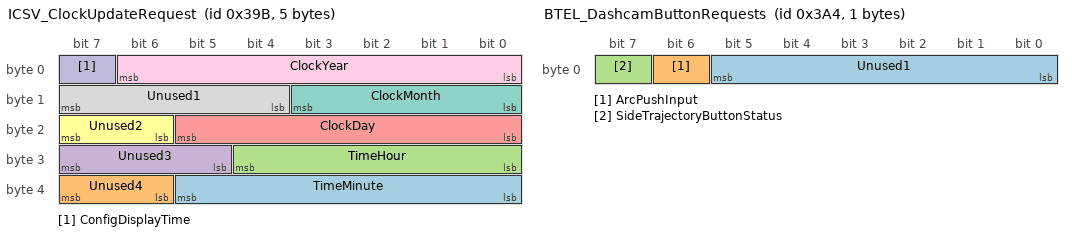
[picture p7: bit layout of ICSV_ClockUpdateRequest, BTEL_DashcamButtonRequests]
BO_ 923 ICSV_ClockUpdateRequest: 5 ICSV
 SG_ TimeMinute : 37|6@0+ (1,0) [0|59] "min"  BSI
 SG_ Unused4 : 39|2@0+ (1,0) [0|3] ""  BSI
 SG_ TimeHour : 28|5@0+ (1,0) [0|23] "h"  BSI
 SG_ Unused3 : 31|3@0+ (1,0) [0|7] ""  BSI
 SG_ ClockDay : 21|6@0+ (1,0) [1|31] "day"  BSI
 SG_ Unused2 : 23|2@0+ (1,0) [0|3] ""  BSI
 SG_ ClockMonth : 11|4@0+ (1,0) [0|15] ""  BSI
 SG_ Unused1 : 15|4@0+ (1,0) [0|15] ""  BSI
 SG_ ClockYear : 6|7@0+ (1,2000) [0|125] "year"  BSI
 SG_ ConfigDisplayTime : 7|1@0+ (1,0) [0|1] ""  BSI

BO_ 924 ICSV_AudioExportAck: 1 ICSV
 SG_ SegmentationAckStream : 7|8@0+ (1,0) [0|255] ""  BTEL,EMF,OVIP,RAD

BO_ 927 EMF_NavDatabaseStatusAckTel: 1 EMF
 SG_ SegmentationAckStream : 7|8@0+ (1,0) [0|255] ""  RAD

BO_ 928 ICSV_VehicleParameterRequest: 8 ICSV
 SG_ FlowPadding5 m3 : 63|8@0+ (1,0) [0|255] "raw"  BSI
 SG_ FirstData6 m1 : 63|8@0+ (1,0) [0|255] "raw"  BSI
 SG_ UnknownData7 m4 : 63|8@0+ (1,0) [0|255] "raw"  BSI
 SG_ ConsecutiveData7 m2 : 63|8@0+ (1,0) [0|255] "raw"  BSI
 SG_ SingleData7 m0 : 63|8@0+ (1,0) [0|255] "raw"  BSI
 SG_ FlowPadding4 m3 : 55|8@0+ (1,0) [0|255] "raw"  BSI
 SG_ FirstData5 m1 : 55|8@0+ (1,0) [0|255] "raw"  BSI
 SG_ UnknownData6 m4 : 55|8@0+ (1,0) [0|255] "raw"  BSI
 SG_ ConsecutiveData6 m2 : 55|8@0+ (1,0) [0|255] "raw"  BSI
 SG_ SingleData6 m0 : 55|8@0+ (1,0) [0|255] "raw"  BSI
 SG_ FlowPadding3 m3 : 47|8@0+ (1,0) [0|255] "raw"  BSI
 SG_ FirstData4 m1 : 47|8@0+ (1,0) [0|255] "raw"  BSI
 SG_ UnknownData5 m4 : 47|8@0+ (1,0) [0|255] "raw"  BSI
 SG_ ConsecutiveData5 m2 : 47|8@0+ (1,0) [0|255] "raw"  BSI
 SG_ SingleData5 m0 : 47|8@0+ (1,0) [0|255] "raw"  BSI
 SG_ FlowPadding2 m3 : 39|8@0+ (1,0) [0|255] "raw"  BSI
 SG_ FirstData3 m1 : 39|8@0+ (1,0) [0|255] "raw"  BSI
 SG_ UnknownData4 m4 : 39|8@0+ (1,0) [0|255] "raw"  BSI
 SG_ ConsecutiveData4 m2 : 39|8@0+ (1,0) [0|255] "raw"  BSI
 SG_ SingleData4 m0 : 39|8@0+ (1,0) [0|255] "raw"  BSI
 SG_ FlowPadding1 m3 : 31|8@0+ (1,0) [0|255] "raw"  BSI
 SG_ FirstData2 m1 : 31|8@0+ (1,0) [0|255] "raw"  BSI
 SG_ UnknownData3 m4 : 31|8@0+ (1,0) [0|255] "raw"  BSI
 SG_ ConsecutiveData3 m2 : 31|8@0+ (1,0) [0|255] "raw"  BSI
 SG_ SingleData3 m0 : 31|8@0+ (1,0) [0|255] "raw"  BSI
 SG_ FirstData1 m1 : 23|8@0+ (1,0) [0|255] "raw"  BSI
 SG_ UnknownData2 m4 : 23|8@0+ (1,0) [0|255] "raw"  BSI
 SG_ ConsecutiveData2 m2 : 23|8@0+ (1,0) [0|255] "raw"  BSI
 SG_ SingleData2 m0 : 23|8@0+ (1,0) [0|255] "raw"  BSI
 SG_ SeparationTimeRaw m3 : 23|8@0+ (1,0) [0|255] "raw"  BSI
 SG_ UnknownData1 m4 : 15|8@0+ (1,0) [0|255] "raw"  BSI
 SG_ ConsecutiveData1 m2 : 15|8@0+ (1,0) [0|255] "raw"  BSI
 SG_ SingleData1 m0 : 15|8@0+ (1,0) [0|255] "raw"  BSI
 SG_ BlockSize m3 : 15|8@0+ (1,0) [0|255] "raw"  BSI
 SG_ UnknownPciLow m4 : 3|4@0+ (1,0) [0|15] "raw"  BSI
 SG_ FlowStatus m3 : 3|4@0+ (1,0) [0|15] "raw"  BSI
 SG_ ConsecutiveSequence m2 : 3|4@0+ (1,0) [0|15] "raw"  BSI
 SG_ FirstFrameLength m1 : 3|12@0+ (1,0) [0|4095] "raw"  BSI
 SG_ SingleFrameLength m0 : 3|4@0+ (1,0) [0|15] "raw"  BSI
 SG_ IsoTpFrameType M : 7|4@0+ (1,0) [0|15] ""  BSI

BO_ 929 ICSV_NavGuidanceCompassDisplay: 7 ICSV
 SG_ SetpointPictogramNumber : 53|6@0+ (1,0) [0|63] ""  CMB,VTH
 SG_ Unused3 : 55|2@0+ (1,0) [0|3] ""  CMB,VTH
 SG_ Unused2 : 40|1@0+ (1,0) [0|1] ""  CMB,VTH
 SG_ RoundaboutMaskSegment : 41|1@0+ (1,0) [0|1] ""  CMB,VTH
 SG_ NavSegmentAngle15 : 43|2@0+ (1,0) [0|3] ""  CMB,VTH
 SG_ NavSegmentAngle14 : 45|2@0+ (1,0) [0|3] ""  CMB,VTH
 SG_ NavSegmentAngle13 : 47|2@0+ (1,0) [0|3] ""  CMB,VTH
 SG_ NavSegmentAngle12 : 33|2@0+ (1,0) [0|3] ""  CMB,VTH
 SG_ NavSegmentAngle11 : 35|2@0+ (1,0) [0|3] ""  CMB,VTH
 SG_ NavSegmentAngle10 : 37|2@0+ (1,0) [0|3] ""  CMB,VTH
 SG_ NavSegmentAngle9 : 39|2@0+ (1,0) [0|3] ""  CMB,VTH
 SG_ NavSegmentAngle8 : 25|2@0+ (1,0) [0|3] ""  CMB,VTH
 SG_ NavSegmentAngle7 : 27|2@0+ (1,0) [0|3] ""  CMB,VTH
 SG_ NavSegmentAngle6 : 29|2@0+ (1,0) [0|3] ""  CMB,VTH
 SG_ NavSegmentAngle5 : 31|2@0+ (1,0) [0|3] ""  CMB,VTH
 SG_ NavSegmentAngle4 : 17|2@0+ (1,0) [0|3] ""  CMB,VTH
 SG_ NavSegmentAngle3 : 19|2@0+ (1,0) [0|3] ""  CMB,VTH
 SG_ NavSegmentAngle2 : 21|2@0+ (1,0) [0|3] ""  CMB,VTH
 SG_ NavSegmentAngle1 : 23|2@0+ (1,0) [0|3] ""  CMB,VTH
 SG_ NavSegmentDecrement8 : 8|1@0+ (1,0) [0|1] ""  CMB,VTH
 SG_ NavSegmentDecrement7 : 9|1@0+ (1,0) [0|1] ""  CMB,VTH
 SG_ NavSegmentDecrement6 : 10|1@0+ (1,0) [0|1] ""  CMB,VTH
 SG_ NavSegmentDecrement5 : 11|1@0+ (1,0) [0|1] ""  CMB,VTH
 SG_ NavSegmentDecrement4 : 12|1@0+ (1,0) [0|1] ""  CMB,VTH
 SG_ NavSegmentDecrement3 : 13|1@0+ (1,0) [0|1] ""  CMB,VTH
 SG_ NavSegmentDecrement2 : 14|1@0+ (1,0) [0|1] ""  CMB,VTH
 SG_ NavSegmentDecrement1 : 15|1@0+ (1,0) [0|1] ""  CMB,VTH
 SG_ DistanceToSetpoint : 4|5@0+ (1,0) [0|31] ""  CMB,VTH
 SG_ SetpointEnd : 5|1@0+ (1,0) [0|1] ""  CMB,VTH
 SG_ Unused1 : 7|2@0+ (1,0) [0|3] ""  CMB,VTH

BO_ 931 BSI_HmiDriveModeInfo: 7 BSI
 SG_ RawByte7 : 55|8@0+ (1,0) [0|255] "raw" Vector__XXX
 SG_ NormalModeCapability : 40|1@0+ (1,0) [0|1] ""  BTEL,CMB,MATT,VTH,OVIP
 SG_ EcoPlusModeCapability : 41|1@0+ (1,0) [0|1] ""  BTEL,CMB,MATT,VTH,OVIP
 SG_ EcoModeCapability : 42|1@0+ (1,0) [0|1] ""  BTEL,CMB,MATT,VTH,OVIP
 SG_ ComfortModeCapability : 43|1@0+ (1,0) [0|1] ""  BTEL,CMB,MATT,VTH,OVIP
 SG_ SportModeCapability : 44|1@0+ (1,0) [0|1] ""  BTEL,CMB,MATT,VTH,OVIP
 SG_ AwdModeCapability : 45|1@0+ (1,0) [0|1] ""  BTEL,CMB,MATT,VTH,OVIP
 SG_ HybridEcoModeCapability : 46|1@0+ (1,0) [0|1] ""  BTEL,CMB,MATT,VTH,OVIP
 SG_ ZevEcoModeCapability : 47|1@0+ (1,0) [0|1] ""  BTEL,CMB,MATT,VTH,OVIP
 SG_ ZevModeCapability : 32|1@0+ (1,0) [0|1] ""  BTEL,CMB,MATT,VTH,OVIP
 SG_ HybridVehicleModeSelector_ba5418 : 36|4@0+ (1,0) [0|15] ""  BTEL,CMB,MATT,VTH,OVIP
 SG_ IlvSpeedPanelValueType : 38|2@0+ (1,0) [0|3] ""  BTEL,CMB,MATT,VTH,OVIP
 SG_ IlvConditionalOverspeedFlag : 39|1@0+ (1,0) [0|1] ""  BTEL,CMB,MATT,VTH,OVIP
 SG_ IlvConditionalSpeedToDisplay : 31|8@0+ (1,0) [0|255] ""  BTEL,CMB,MATT,VTH,OVIP
 SG_ IlvImplicitSignType : 19|4@0+ (1,0) [0|15] ""  BTEL,CMB,MATT,VTH,OVIP
 SG_ IlvConditionalSignType : 23|4@0+ (1,0) [0|15] ""  BTEL,CMB,MATT,VTH,OVIP
 SG_ IlvLeftSlotNoSpeedPanel : 15|8@0+ (1,0) [0|254] ""  BTEL,CMB,MATT,VTH,OVIP
 SG_ IlvRightSlotNoSpeedPanel : 7|8@0+ (1,0) [0|254] ""  BTEL,CMB,MATT,VTH,OVIP

BO_ 932 BTEL_DashcamButtonRequests: 1 BTEL
 SG_ Unused1 : 5|6@0+ (1,0) [0|63] ""  IDVR
 SG_ ArcPushInput : 6|1@0+ (1,0) [0|1] ""  IDVR
 SG_ SideTrajectoryButtonStatus : 7|1@0+ (1,0) [0|1] ""  IDVR

BO_TX_BU_ 808 : ICSV,EMF,BTEL,OVIP;
BO_TX_BU_ 809 : BTEL,OVIP;
BO_TX_BU_ 822 : BSI,ICSV;
BO_TX_BU_ 848 : ICSV,FMUX;
BO_TX_BU_ 858 : BTEL,OVIP;
BO_TX_BU_ 863 : EMF,ICSV;
BO_TX_BU_ 864 : ICSV,BSI;
BO_TX_BU_ 868 : BTEL,OVIP;
BO_TX_BU_ 871 : EMF,ICSV;
BO_TX_BU_ 886 : BTEL,EMF,OVIP;
BO_TX_BU_ 901 : BTEL,OVIP;
BO_TX_BU_ 923 : ICSV,BTEL,OVIP,CMB,EMF,MATT;
BO_TX_BU_ 924 : ICSV,MATT;
BO_TX_BU_ 927 : EMF,ICSV;
BO_TX_BU_ 928 : ICSV,BTEL,OVIP;
BO_TX_BU_ 929 : ICSV,BTEL,OVIP;
BO_TX_BU_ 932 : BTEL,OVIP;
CM_ BO_ 808 "DATABASE_CANDIDATE: physical interpretation unverified; capture/layout evidence reported separately. INFO-DIV CAN, 125000 bit/s; CAN ID 0x328. PSA-RE title: ENGINE_ECU_DATA. Family of frames sharing this ID: the content depends on AUDIO_SOURCE_ORIGIN_TYPE Source: https://github.com/prototux/PSA-RE/blob/67f7581e7622410efdbb29c7eda3b86982b9b450/buses/AEE2010.full/LS.INFO-DIV/328.yml. Source sender alternatives: ICSV,EMF,BTEL,OVIP; physical TX/gateway forwarding not verified. Observed 1 frames in info_start_jizda.csv; DLCs [8]. WIRE ISO-TP ONLY: normal addressing candidate, maximum Classical CAN DLC 8; actual DLC may be shorter. Data includes padding. No reassembly, text, DID or application-layer decoding. Original application layouts are preserved in source JSON; do not decode them at wire offsets. Unresolved alternative source layouts preserved in source JSON. ";
CM_ SG_ 808 FlowPadding5 "TRANSPORT_CANDIDATE: normal-addressing ISO-TP. PSA-RE bits 8.7-8.0. ";
CM_ SG_ 808 FirstData6 "TRANSPORT_CANDIDATE: normal-addressing ISO-TP. PSA-RE bits 8.7-8.0. ";
CM_ SG_ 808 UnknownData7 "TRANSPORT_CANDIDATE: normal-addressing ISO-TP. PSA-RE bits 8.7-8.0. ";
CM_ SG_ 808 ConsecutiveData7 "TRANSPORT_CANDIDATE: normal-addressing ISO-TP. PSA-RE bits 8.7-8.0. ";
CM_ SG_ 808 SingleData7 "TRANSPORT_CANDIDATE: normal-addressing ISO-TP. PSA-RE bits 8.7-8.0. ";
CM_ SG_ 808 FlowPadding4 "TRANSPORT_CANDIDATE: normal-addressing ISO-TP. PSA-RE bits 7.7-7.0. ";
CM_ SG_ 808 FirstData5 "TRANSPORT_CANDIDATE: normal-addressing ISO-TP. PSA-RE bits 7.7-7.0. ";
CM_ SG_ 808 UnknownData6 "TRANSPORT_CANDIDATE: normal-addressing ISO-TP. PSA-RE bits 7.7-7.0. ";
CM_ SG_ 808 ConsecutiveData6 "TRANSPORT_CANDIDATE: normal-addressing ISO-TP. PSA-RE bits 7.7-7.0. ";
CM_ SG_ 808 SingleData6 "TRANSPORT_CANDIDATE: normal-addressing ISO-TP. PSA-RE bits 7.7-7.0. ";
CM_ SG_ 808 FlowPadding3 "TRANSPORT_CANDIDATE: normal-addressing ISO-TP. PSA-RE bits 6.7-6.0. ";
CM_ SG_ 808 FirstData4 "TRANSPORT_CANDIDATE: normal-addressing ISO-TP. PSA-RE bits 6.7-6.0. ";
CM_ SG_ 808 UnknownData5 "TRANSPORT_CANDIDATE: normal-addressing ISO-TP. PSA-RE bits 6.7-6.0. ";
CM_ SG_ 808 ConsecutiveData5 "TRANSPORT_CANDIDATE: normal-addressing ISO-TP. PSA-RE bits 6.7-6.0. ";
CM_ SG_ 808 SingleData5 "TRANSPORT_CANDIDATE: normal-addressing ISO-TP. PSA-RE bits 6.7-6.0. ";
CM_ SG_ 808 FlowPadding2 "TRANSPORT_CANDIDATE: normal-addressing ISO-TP. PSA-RE bits 5.7-5.0. ";
CM_ SG_ 808 FirstData3 "TRANSPORT_CANDIDATE: normal-addressing ISO-TP. PSA-RE bits 5.7-5.0. ";
CM_ SG_ 808 UnknownData4 "TRANSPORT_CANDIDATE: normal-addressing ISO-TP. PSA-RE bits 5.7-5.0. ";
CM_ SG_ 808 ConsecutiveData4 "TRANSPORT_CANDIDATE: normal-addressing ISO-TP. PSA-RE bits 5.7-5.0. ";
CM_ SG_ 808 SingleData4 "TRANSPORT_CANDIDATE: normal-addressing ISO-TP. PSA-RE bits 5.7-5.0. ";
CM_ SG_ 808 FlowPadding1 "TRANSPORT_CANDIDATE: normal-addressing ISO-TP. PSA-RE bits 4.7-4.0. ";
CM_ SG_ 808 FirstData2 "TRANSPORT_CANDIDATE: normal-addressing ISO-TP. PSA-RE bits 4.7-4.0. ";
CM_ SG_ 808 UnknownData3 "TRANSPORT_CANDIDATE: normal-addressing ISO-TP. PSA-RE bits 4.7-4.0. ";
CM_ SG_ 808 ConsecutiveData3 "TRANSPORT_CANDIDATE: normal-addressing ISO-TP. PSA-RE bits 4.7-4.0. ";
CM_ SG_ 808 SingleData3 "TRANSPORT_CANDIDATE: normal-addressing ISO-TP. PSA-RE bits 4.7-4.0. ";
CM_ SG_ 808 FirstData1 "TRANSPORT_CANDIDATE: normal-addressing ISO-TP. PSA-RE bits 3.7-3.0. ";
CM_ SG_ 808 UnknownData2 "TRANSPORT_CANDIDATE: normal-addressing ISO-TP. PSA-RE bits 3.7-3.0. ";
CM_ SG_ 808 ConsecutiveData2 "TRANSPORT_CANDIDATE: normal-addressing ISO-TP. PSA-RE bits 3.7-3.0. ";
CM_ SG_ 808 SingleData2 "TRANSPORT_CANDIDATE: normal-addressing ISO-TP. PSA-RE bits 3.7-3.0. ";
CM_ SG_ 808 SeparationTimeRaw "TRANSPORT_CANDIDATE: normal-addressing ISO-TP. PSA-RE bits 3.7-3.0. Raw STmin code; 0xF1..0xF9 are not milliseconds.";
CM_ SG_ 808 UnknownData1 "TRANSPORT_CANDIDATE: normal-addressing ISO-TP. PSA-RE bits 2.7-2.0. ";
CM_ SG_ 808 ConsecutiveData1 "TRANSPORT_CANDIDATE: normal-addressing ISO-TP. PSA-RE bits 2.7-2.0. ";
CM_ SG_ 808 SingleData1 "TRANSPORT_CANDIDATE: normal-addressing ISO-TP. PSA-RE bits 2.7-2.0. ";
CM_ SG_ 808 BlockSize "TRANSPORT_CANDIDATE: normal-addressing ISO-TP. PSA-RE bits 2.7-2.0. ";
CM_ SG_ 808 UnknownPciLow "TRANSPORT_CANDIDATE: normal-addressing ISO-TP. PSA-RE bits 1.3-1.0. ";
CM_ SG_ 808 FlowStatus "TRANSPORT_CANDIDATE: normal-addressing ISO-TP. PSA-RE bits 1.3-1.0. ";
CM_ SG_ 808 ConsecutiveSequence "TRANSPORT_CANDIDATE: normal-addressing ISO-TP. PSA-RE bits 1.3-1.0. ";
CM_ SG_ 808 FirstFrameLength "TRANSPORT_CANDIDATE: normal-addressing ISO-TP. PSA-RE bits 1.3-2.0. 12-bit declared PDU length; not a reassembled value.";
CM_ SG_ 808 SingleFrameLength "TRANSPORT_CANDIDATE: normal-addressing ISO-TP. PSA-RE bits 1.3-1.0. Declared data length; not a validity check.";
CM_ SG_ 808 IsoTpFrameType "TRANSPORT_CANDIDATE: normal-addressing ISO-TP. PSA-RE bits 1.7-1.4. PCI high nibble; normal addressing candidate.";
CM_ BO_ 809 "DATABASE_CANDIDATE: physical interpretation unverified; capture/layout evidence reported separately. INFO-DIV CAN, 125000 bit/s; CAN ID 0x329. PSA-RE title: STOP_START_GEARBOX_DATA. Comfort feature requests: automated-parking activation and manoeuvre side, cabin air purifier and air-quality level, consumption-history reset, fragrance cartridge, and massage seat activation/intensity/zone/type. Source: https://github.com/prototux/PSA-RE/blob/67f7581e7622410efdbb29c7eda3b86982b9b450/buses/AEE2010.ev/LS.INFO-DIV/329.yml. Source sender alternatives: BTEL,OVIP; physical TX/gateway forwarding not verified. Observed 2958 frames in info_apka.csv,info_buzeni_obc.csv,info_charging.csv,info_standby.csv,info_start_jizda.csv,infocan.csv; DLCs [8]. SOURCE_DLC_MISMATCH: source 7, observed/exported 8. Fitting fields retained; additional bytes raw. ";
CM_ SG_ 809 RawByte8 "RAW. PSA-RE bits 8.7-8.0. Unmapped/padding bits, no physical interpretation.";
CM_ SG_ 809 RawByte7 "RAW. PSA-RE bits 7.7-7.0. Unmapped/padding bits, no physical interpretation.";
CM_ SG_ 809 Unused1 "DATABASE_CANDIDATE: physical interpretation unverified; capture/layout evidence reported separately. PSA-RE bits 6.1-6.0. ";
CM_ SG_ 809 EnergyRecoveryButtonPressed "DATABASE_CANDIDATE: physical interpretation unverified; capture/layout evidence reported separately. PSA-RE bits 6.2. Energy recovery button pressed Upstream default raw=0 (not necessarily valid data).";
CM_ SG_ 809 AvasButtonPressed "DATABASE_CANDIDATE: physical interpretation unverified; capture/layout evidence reported separately. PSA-RE bits 6.3. AVAS (acoustic vehicle alert) button pressed Upstream default raw=0 (not necessarily valid data).";
CM_ SG_ 809 OutsideAirQualityBadLevel "DATABASE_CANDIDATE: physical interpretation unverified; capture/layout evidence reported separately. PSA-RE bits 6.6-6.4. Outside air pollution level (bad range detail) Upstream default raw=0 (not necessarily valid data).";
CM_ SG_ 809 NightVisionToggleRequest "DATABASE_CANDIDATE: physical interpretation unverified; capture/layout evidence reported separately. PSA-RE bits 6.7. Night vision function enable/disable request Upstream default raw=0 (not necessarily valid data).";
CM_ SG_ 809 AutomaticParkingSideRequest "DATABASE_CANDIDATE: physical interpretation unverified; capture/layout evidence reported separately. PSA-RE bits 5.0. Requested parking side for the automatic parking maneuver Upstream default raw=0 (not necessarily valid data).";
CM_ SG_ 809 AutomaticParkingActivatio_012211 "DATABASE_CANDIDATE: physical interpretation unverified; capture/layout evidence reported separately. PSA-RE bits 5.1. Automatic parking (ACPK) maneuver activation via touch button Upstream default raw=0 (not necessarily valid data).";
CM_ SG_ 809 CabinAirFilterResetRequest "DATABASE_CANDIDATE: physical interpretation unverified; capture/layout evidence reported separately. PSA-RE bits 5.2. Request to reset the cabin air filter dirt level Upstream default raw=0 (not necessarily valid data).";
CM_ SG_ 809 CabinAirPurifierModeRequest "DATABASE_CANDIDATE: physical interpretation unverified; capture/layout evidence reported separately. PSA-RE bits 5.5-5.3. Requested cabin air purifier mode (Off/Auto/Low/Medium/High) Upstream default raw=7 (not necessarily valid data).";
CM_ SG_ 809 OutsideAirQualityLevel "DATABASE_CANDIDATE: physical interpretation unverified; capture/layout evidence reported separately. PSA-RE bits 5.7-5.6. Outside air pollution level Upstream default raw=3 (not necessarily valid data).";
CM_ SG_ 809 AsrInhibitRequest "DATABASE_CANDIDATE: physical interpretation unverified; capture/layout evidence reported separately. PSA-RE bits 4.0. ASR (traction control) connect/disconnect request Upstream default raw=0 (not necessarily valid data).";
CM_ SG_ 809 ConsumptionHistoryZoomLevel "DATABASE_CANDIDATE: physical interpretation unverified; capture/layout evidence reported separately. PSA-RE bits 4.2-4.1. Zoom level for the consumption history display Upstream default raw=0 (not necessarily valid data).";
CM_ SG_ 809 ConsumptionHistoryResetRequest "DATABASE_CANDIDATE: physical interpretation unverified; capture/layout evidence reported separately. PSA-RE bits 4.3. Hybrid fuel-consumption history reset request Upstream default raw=0 (not necessarily valid data).";
CM_ SG_ 809 DynamicModeTouchSelection "DATABASE_CANDIDATE: physical interpretation unverified; capture/layout evidence reported separately. PSA-RE bits 4.7-4.4. Dynamic driving mode selected via the touch/sensory interface Upstream default raw=0 (not necessarily valid data). Unresolved source alternatives: [{\"note\": \"Also observed at bits 4.5-4.4\", \"bits\": \"4.5-4.4\"}]";
CM_ SG_ 809 EcoachTripResetRequest "DATABASE_CANDIDATE: physical interpretation unverified; capture/layout evidence reported separately. PSA-RE bits 3.0. Driver request to reset the Eco Coaching trip data Upstream default raw=0 (not necessarily valid data).";
CM_ SG_ 809 MassageActivationCommand "DATABASE_CANDIDATE: physical interpretation unverified; capture/layout evidence reported separately. PSA-RE bits 3.1. Massage activation/deactivation command Upstream default raw=0 (not necessarily valid data).";
CM_ SG_ 809 MassageIntensityCommand "DATABASE_CANDIDATE: physical interpretation unverified; capture/layout evidence reported separately. PSA-RE bits 3.3-3.2. Massage intensity command Upstream default raw=1 (not necessarily valid data).";
CM_ SG_ 809 MassageTypeCommand "DATABASE_CANDIDATE: physical interpretation unverified; capture/layout evidence reported separately. PSA-RE bits 3.7-3.4. Massage type command Upstream default raw=0 (not necessarily valid data).";
CM_ SG_ 809 FrontMassageSeatSelectionCommand "DATABASE_CANDIDATE: physical interpretation unverified; capture/layout evidence reported separately. PSA-RE bits 2.1-2.0. Front massage seat selection command (driver/passenger) Upstream default raw=0 (not necessarily valid data).";
CM_ SG_ 809 FragranceSelectionRequest "DATABASE_CANDIDATE: physical interpretation unverified; capture/layout evidence reported separately. PSA-RE bits 2.3-2.2. Requested fragrance among the available scent tanks Upstream default raw=0 (not necessarily valid data).";
CM_ SG_ 809 FragranceIntensityRequest "DATABASE_CANDIDATE: physical interpretation unverified; capture/layout evidence reported separately. PSA-RE bits 2.5-2.4. Requested fragrance diffuser intensity level Upstream default raw=0 (not necessarily valid data).";
CM_ SG_ 809 FragranceDiffuserActivati_99a752 "DATABASE_CANDIDATE: physical interpretation unverified; capture/layout evidence reported separately. PSA-RE bits 2.7-2.6. Fragrance diffuser activation request Upstream default raw=0 (not necessarily valid data).";
CM_ SG_ 809 FragranceCartridgeMonoStatus "DATABASE_CANDIDATE: physical interpretation unverified; capture/layout evidence reported separately. PSA-RE bits 1.1-1.0. Indication of whether the fragrance cartridge holds a single scent in all slots Upstream default raw=0 (not necessarily valid data).";
CM_ SG_ 809 IonizerActivationRequest "DATABASE_CANDIDATE: physical interpretation unverified; capture/layout evidence reported separately. PSA-RE bits 1.3-1.2. Ioniser activation request verification by the climate control Upstream default raw=3 (not necessarily valid data).";
CM_ SG_ 809 LkaButtonPressed "DATABASE_CANDIDATE: physical interpretation unverified; capture/layout evidence reported separately. PSA-RE bits 1.4. Lane keeping assist (LKA) button pressed by the user Upstream default raw=0 (not necessarily valid data).";
CM_ SG_ 809 AsrPlusModeSelection "DATABASE_CANDIDATE: physical interpretation unverified; capture/layout evidence reported separately. PSA-RE bits 1.6-1.5. ASR+ traction mode selection (normal/snow/mud/sand)";
CM_ SG_ 809 FunctionSelectionRequest "DATABASE_CANDIDATE: physical interpretation unverified; capture/layout evidence reported separately. PSA-RE bits 1.7. Function selection request Upstream default raw=0 (not necessarily valid data).";
CM_ BO_ 821 "DATABASE_CANDIDATE: physical interpretation unverified; capture/layout evidence reported separately. INFO-DIV CAN, 125000 bit/s; CAN ID 0x335. PSA-RE title: LPG_TRIP_CONSUMPTION. LPG trip-computer data: instant and cumulative range/consumption while running on gas. Source: https://github.com/prototux/PSA-RE/blob/67f7581e7622410efdbb29c7eda3b86982b9b450/buses/AEE2010.full/LS.INFO-DIV/335.yml. Source sender alternatives: BSI; physical TX/gateway forwarding not verified. ";
CM_ SG_ 821 Unused2 "DATABASE_CANDIDATE: physical interpretation unverified; capture/layout evidence reported separately. PSA-RE bits 5.5-5.0. ";
CM_ SG_ 821 LpgEngineMode "DATABASE_CANDIDATE: physical interpretation unverified; capture/layout evidence reported separately. PSA-RE bits 5.7-5.6. Engine LPG operating mode Upstream default raw=0 (not necessarily valid data).";
CM_ SG_ 821 TotalRangeDisplayed "DATABASE_CANDIDATE: physical interpretation unverified; capture/layout evidence reported separately. PSA-RE bits 3.2-4.0. Total range (petrol + LPG) displayed to the driver Raw invalid=2047; numeric DBC decoders may still scale it: check raw before use. Upstream default raw=0 (not necessarily valid data).";
CM_ SG_ 821 Unused1 "DATABASE_CANDIDATE: physical interpretation unverified; capture/layout evidence reported separately. PSA-RE bits 3.3. ";
CM_ SG_ 821 LpgInstantConsumption2 "DATABASE_CANDIDATE: physical interpretation unverified; capture/layout evidence reported separately. PSA-RE bits 2.4-3.4. Instantaneous LPG consumption Raw invalid=511; numeric DBC decoders may still scale it: check raw before use. Upstream default raw=0 (not necessarily valid data).";
CM_ SG_ 821 LpgRangeDisplayed "DATABASE_CANDIDATE: physical interpretation unverified; capture/layout evidence reported separately. PSA-RE bits 1.7-2.5. LPG range displayed to the driver Raw invalid=2047; numeric DBC decoders may still scale it: check raw before use. Upstream default raw=0 (not necessarily valid data).";
CM_ BO_ 822 "DATABASE_CANDIDATE: physical interpretation unverified; capture/layout evidence reported separately. INFO-DIV CAN, 125000 bit/s; CAN ID 0x336. PSA-RE title: CAMERA_STEERING_BRAKE_DATA. VIN = Vehicle Identification Number. WMI = World Manufacturer Identifier, VIN field identifying the manufacturer worldwide. Source: https://github.com/prototux/PSA-RE/blob/67f7581e7622410efdbb29c7eda3b86982b9b450/buses/AEE2010.full/LS.INFO-DIV/336.yml. Source sender alternatives: BSI,ICSV; physical TX/gateway forwarding not verified. Observed 586 frames in info_apka.csv,info_buzeni_obc.csv,info_charging.csv,info_standby.csv,info_start_jizda.csv,infocan.csv; DLCs [3]. Unresolved alternative source layouts preserved in source JSON. ";
CM_ SG_ 822 WmiChar3 "DATABASE_CANDIDATE: physical interpretation unverified; capture/layout evidence reported separately. PSA-RE bits 3.7-3.0. Third WMI character. Source text/byte field exposed as raw integer; no string decoding. Upstream default raw=0 (not necessarily valid data).";
CM_ SG_ 822 WmiChar2 "DATABASE_CANDIDATE: physical interpretation unverified; capture/layout evidence reported separately. PSA-RE bits 2.7-2.0. Second WMI character. Source text/byte field exposed as raw integer; no string decoding. Upstream default raw=0 (not necessarily valid data).";
CM_ SG_ 822 WmiChar1 "DATABASE_CANDIDATE: physical interpretation unverified; capture/layout evidence reported separately. PSA-RE bits 1.7-1.0. First WMI character. Source text/byte field exposed as raw integer; no string decoding. Upstream default raw=0 (not necessarily valid data).";
CM_ BO_ 833 "DATABASE_CANDIDATE: physical interpretation unverified; capture/layout evidence reported separately. INFO-DIV CAN, 125000 bit/s; CAN ID 0x341. PSA-RE title: WIRELESS_CHARGER_STATUS. Wireless charger connection status: connected device, device number and fault status. Source: https://github.com/prototux/PSA-RE/blob/67f7581e7622410efdbb29c7eda3b86982b9b450/buses/AEE2010.full/LS.INFO-DIV/341.yml. Source sender alternatives: WLC; physical TX/gateway forwarding not verified. ";
CM_ SG_ 833 Unused1 "DATABASE_CANDIDATE: physical interpretation unverified; capture/layout evidence reported separately. PSA-RE bits 4.7-8.0. ";
CM_ SG_ 833 WlcDiagnosticStatus "DATABASE_CANDIDATE: physical interpretation unverified; capture/layout evidence reported separately. PSA-RE bits 3.7-3.0. Malfunction status, for diagnostics (wireless charger)";
CM_ SG_ 833 WlcConnectedDeviceId "DATABASE_CANDIDATE: physical interpretation unverified; capture/layout evidence reported separately. PSA-RE bits 2.7-2.0. Badge/device number currently connected (0 = no device connected), wireless charger";
CM_ SG_ 833 WlcNfcDeviceCount "DATABASE_CANDIDATE: physical interpretation unverified; capture/layout evidence reported separately. PSA-RE bits 1.7-1.0. Number of NFC devices detected during the inventory scan, wireless charger Upstream default raw=0 (not necessarily valid data).";
CM_ BO_ 835 "DATABASE_CANDIDATE: physical interpretation unverified; capture/layout evidence reported separately. INFO-DIV CAN, 125000 bit/s; CAN ID 0x343. PSA-RE title: ODI_DYNAMIC_DATA_LIST_REQUEST_BUFFER. Opaque data buffer of the embedded diagnostics interface (ODI) between the telematics unit and the diagnostic tool: dynamic-data list request. Source: https://github.com/prototux/PSA-RE/blob/67f7581e7622410efdbb29c7eda3b86982b9b450/buses/AEE2010.full/LS.INFO-DIV/343.yml. Source sender alternatives: BTEL; physical TX/gateway forwarding not verified. ";
CM_ SG_ 835 OdiDynDataListRequestCent_4a34c1 "DATABASE_CANDIDATE: physical interpretation unverified; capture/layout evidence reported separately. PSA-RE bits 1.7-8.0. Open Display Interface (ODI) dynamic data list request buffer for the center stack display";
CM_ BO_ 837 "DATABASE_CANDIDATE: physical interpretation unverified; capture/layout evidence reported separately. INFO-DIV CAN, 125000 bit/s; CAN ID 0x345. PSA-RE title: DASHCAM_ACCIDENT_POPUP. Dashcam accident recording pop-up: recording date/time, video number and pop-up type shown on the display. Source: https://github.com/prototux/PSA-RE/blob/67f7581e7622410efdbb29c7eda3b86982b9b450/buses/AEE2010.full/LS.INFO-DIV/345.yml. Source sender alternatives: IDVR; physical TX/gateway forwarding not verified. ";
CM_ SG_ 837 Unused7 "DATABASE_CANDIDATE: physical interpretation unverified; capture/layout evidence reported separately. PSA-RE bits 8.7-8.0. ";
CM_ SG_ 837 Unused6 "DATABASE_CANDIDATE: physical interpretation unverified; capture/layout evidence reported separately. PSA-RE bits 7.3-7.0. ";
CM_ SG_ 837 VideoSequenceNumber "DATABASE_CANDIDATE: physical interpretation unverified; capture/layout evidence reported separately. PSA-RE bits 7.7-7.4. Number of the video among those with the same date Upstream default raw=0 (not necessarily valid data).";
CM_ SG_ 837 Unused5 "DATABASE_CANDIDATE: physical interpretation unverified; capture/layout evidence reported separately. PSA-RE bits 6.1-6.0. ";
CM_ SG_ 837 VideoMinute "DATABASE_CANDIDATE: physical interpretation unverified; capture/layout evidence reported separately. PSA-RE bits 6.7-6.2. Minute of the video Raw invalid=63; numeric DBC decoders may still scale it: check raw before use. Upstream default raw=63 (not necessarily valid data).";
CM_ SG_ 837 Unused4 "DATABASE_CANDIDATE: physical interpretation unverified; capture/layout evidence reported separately. PSA-RE bits 5.2-5.0. ";
CM_ SG_ 837 VideoHour "DATABASE_CANDIDATE: physical interpretation unverified; capture/layout evidence reported separately. PSA-RE bits 5.7-5.3. Hour of the video Raw invalid=31; numeric DBC decoders may still scale it: check raw before use. Upstream default raw=31 (not necessarily valid data).";
CM_ SG_ 837 Unused3 "DATABASE_CANDIDATE: physical interpretation unverified; capture/layout evidence reported separately. PSA-RE bits 4.1-4.0. ";
CM_ SG_ 837 VideoDay "DATABASE_CANDIDATE: physical interpretation unverified; capture/layout evidence reported separately. PSA-RE bits 4.7-4.2. Day of the video Raw invalid=63; numeric DBC decoders may still scale it: check raw before use. Upstream default raw=63 (not necessarily valid data).";
CM_ SG_ 837 Unused2 "DATABASE_CANDIDATE: physical interpretation unverified; capture/layout evidence reported separately. PSA-RE bits 3.3-3.0. ";
CM_ SG_ 837 VideoMonth "DATABASE_CANDIDATE: physical interpretation unverified; capture/layout evidence reported separately. PSA-RE bits 3.7-3.4. Month of the video Raw invalid=15; numeric DBC decoders may still scale it: check raw before use. Upstream default raw=15 (not necessarily valid data).";
CM_ SG_ 837 VideoYear "DATABASE_CANDIDATE: physical interpretation unverified; capture/layout evidence reported separately. PSA-RE bits 2.7-2.0. Year of the video Raw invalid=255; numeric DBC decoders may still scale it: check raw before use. Upstream default raw=255 (not necessarily valid data).";
CM_ SG_ 837 Unused1 "DATABASE_CANDIDATE: physical interpretation unverified; capture/layout evidence reported separately. PSA-RE bits 1.5-1.0. ";
CM_ SG_ 837 PopupType2 "DATABASE_CANDIDATE: physical interpretation unverified; capture/layout evidence reported separately. PSA-RE bits 1.7-1.6. Type of display pop-up Upstream default raw=0 (not necessarily valid data).";
CM_ BO_ 848 "DATABASE_CANDIDATE: physical interpretation unverified; capture/layout evidence reported separately. INFO-DIV CAN, 125000 bit/s; CAN ID 0x350. PSA-RE title: CSS_SUSPENSION_STATUS. Front air conditioning status: heated windscreen/rear window activation, blower fault, air distribution, A/C request and front seat heating/ventilation requests. Source: https://github.com/prototux/PSA-RE/blob/67f7581e7622410efdbb29c7eda3b86982b9b450/buses/AEE2010.full/LS.INFO-DIV/350.yml. Source sender alternatives: ICSV,FMUX; physical TX/gateway forwarding not verified. Observed 1176 frames in info_apka.csv,info_buzeni_obc.csv,info_charging.csv,info_standby.csv,info_start_jizda.csv,infocan.csv; DLCs [8]. ";
CM_ SG_ 848 Unused1 "DATABASE_CANDIDATE: physical interpretation unverified; capture/layout evidence reported separately. PSA-RE bits 8.0. ";
CM_ SG_ 848 FrontRightSeatVentilationRequest "DATABASE_CANDIDATE: physical interpretation unverified; capture/layout evidence reported separately. PSA-RE bits 8.2-8.1. Front right seat ventilation level requested by the user Upstream default raw=0 (not necessarily valid data).";
CM_ SG_ 848 FrontLeftSeatHeatingRequest "DATABASE_CANDIDATE: physical interpretation unverified; capture/layout evidence reported separately. PSA-RE bits 8.4-8.3. Front left seat heating level requested by the user Upstream default raw=0 (not necessarily valid data).";
CM_ SG_ 848 FrontRightSeatHeatingRequest "DATABASE_CANDIDATE: physical interpretation unverified; capture/layout evidence reported separately. PSA-RE bits 8.6-8.5. Front right seat heating level requested by the user Upstream default raw=0 (not necessarily valid data).";
CM_ SG_ 848 EnergySaverModeStatus "DATABASE_CANDIDATE: physical interpretation unverified; capture/layout evidence reported separately. PSA-RE bits 8.7. Energy saver mode status Upstream default raw=0 (not necessarily valid data).";
CM_ SG_ 848 FrontRightAirflowDistribution "DATABASE_CANDIDATE: physical interpretation unverified; capture/layout evidence reported separately. PSA-RE bits 7.3-7.0. Front right air distribution mode Upstream default raw=4 (not necessarily valid data).";
CM_ SG_ 848 FrontLeftAirflowDistribution "DATABASE_CANDIDATE: physical interpretation unverified; capture/layout evidence reported separately. PSA-RE bits 7.7-7.4. Front left air distribution mode Upstream default raw=4 (not necessarily valid data).";
CM_ SG_ 848 FrontBlowerManualSpeedDisplay "DATABASE_CANDIDATE: physical interpretation unverified; capture/layout evidence reported separately. PSA-RE bits 6.3-6.0. Display status: front blower manual speed Upstream default raw=1 (not necessarily valid data).";
CM_ SG_ 848 Mode "DATABASE_CANDIDATE: physical interpretation unverified; capture/layout evidence reported separately. PSA-RE bits 6.6-6.4. Air inlet mode (auto comfort, auto visibility, forced open, forced closed, auto comfort without AQS) Upstream default raw=4 (not necessarily valid data).";
CM_ SG_ 848 AqsStatus "DATABASE_CANDIDATE: physical interpretation unverified; capture/layout evidence reported separately. PSA-RE bits 6.7. Air quality sensor (AQS) function status, for a dedicated display Upstream default raw=1 (not necessarily valid data).";
CM_ SG_ 848 FrontRightTempSetpointValue "DATABASE_CANDIDATE: physical interpretation unverified; capture/layout evidence reported separately. PSA-RE bits 5.4-5.0. Front right temperature setpoint value Upstream default raw=11 (not necessarily valid data).";
CM_ SG_ 848 FrontLeftSeatVentilationRequest "DATABASE_CANDIDATE: physical interpretation unverified; capture/layout evidence reported separately. PSA-RE bits 5.6-5.5. Front left seat ventilation level requested by the user Upstream default raw=0 (not necessarily valid data).";
CM_ SG_ 848 HeatedWindscreenActivatio_b0408e "DATABASE_CANDIDATE: physical interpretation unverified; capture/layout evidence reported separately. PSA-RE bits 5.7. Heated windscreen activation/deactivation request Upstream default raw=0 (not necessarily valid data).";
CM_ SG_ 848 FrontLeftTempSetpointValue "DATABASE_CANDIDATE: physical interpretation unverified; capture/layout evidence reported separately. PSA-RE bits 4.4-4.0. Front left temperature setpoint value Upstream default raw=11 (not necessarily valid data).";
CM_ SG_ 848 RestoreFlagStatus "DATABASE_CANDIDATE: physical interpretation unverified; capture/layout evidence reported separately. PSA-RE bits 4.5. Restore function flag status Upstream default raw=0 (not necessarily valid data).";
CM_ SG_ 848 MonoModeStatus "DATABASE_CANDIDATE: physical interpretation unverified; capture/layout evidence reported separately. PSA-RE bits 4.6. Single-zone (MONO) climate function status Upstream default raw=0 (not necessarily valid data).";
CM_ SG_ 848 AcMaxStatus "DATABASE_CANDIDATE: physical interpretation unverified; capture/layout evidence reported separately. PSA-RE bits 4.7. Max A/C function status Upstream default raw=0 (not necessarily valid data).";
CM_ SG_ 848 EvaporatorSensorTemperature "DATABASE_CANDIDATE: physical interpretation unverified; capture/layout evidence reported separately. PSA-RE bits 2.7-3.0. Evaporator sensor temperature Raw invalid=65535; numeric DBC decoders may still scale it: check raw before use. Upstream default raw=65535 (not necessarily valid data).";
CM_ SG_ 848 AcType "DATABASE_CANDIDATE: physical interpretation unverified; capture/layout evidence reported separately. PSA-RE bits 1.1-1.0. A/C system type (light, normal, strong) Upstream default raw=1 (not necessarily valid data).";
CM_ SG_ 848 AcModeRequest "DATABASE_CANDIDATE: physical interpretation unverified; capture/layout evidence reported separately. PSA-RE bits 1.3-1.2. A/C mode request (auto comfort, auto visibility, off, invalid) Upstream default raw=2 (not necessarily valid data).";
CM_ SG_ 848 VisibilityRequest "DATABASE_CANDIDATE: physical interpretation unverified; capture/layout evidence reported separately. PSA-RE bits 1.4. Visibility (demisting/defrosting) request Upstream default raw=0 (not necessarily valid data).";
CM_ SG_ 848 RearWindshieldHeat "DATABASE_CANDIDATE: physical interpretation unverified; capture/layout evidence reported separately. PSA-RE bits 1.5. Heated rear window activation request Upstream default raw=0 (not necessarily valid data).";
CM_ SG_ 848 RestModeStatus "DATABASE_CANDIDATE: physical interpretation unverified; capture/layout evidence reported separately. PSA-RE bits 1.6. Rest function status Upstream default raw=0 (not necessarily valid data).";
CM_ SG_ 848 FrontBlowerMotorFault "DATABASE_CANDIDATE: physical interpretation unverified; capture/layout evidence reported separately. PSA-RE bits 1.7. Front blower motor fault Upstream default raw=0 (not necessarily valid data).";
CM_ BO_ 852 "DATABASE_CANDIDATE: physical interpretation unverified; capture/layout evidence reported separately. INFO-DIV CAN, 125000 bit/s; CAN ID 0x354. PSA-RE title: REMOTE_TELEMATICS_RESPONSE. Response to a remote command, with packet counter and reference number. Source: https://github.com/prototux/PSA-RE/blob/67f7581e7622410efdbb29c7eda3b86982b9b450/buses/AEE2010.full/LS.INFO-DIV/354.yml. Source sender alternatives: BSI; physical TX/gateway forwarding not verified. ";
CM_ SG_ 852 RemoteResponsePayload "DATABASE_CANDIDATE: physical interpretation unverified; capture/layout evidence reported separately. PSA-RE bits 2.7-8.0. Payload data of the remote action responses Upstream default raw=0 (not necessarily valid data).";
CM_ SG_ 852 RemoteResponseSegmentNumber "DATABASE_CANDIDATE: physical interpretation unverified; capture/layout evidence reported separately. PSA-RE bits 1.3-1.0. Segment number for remote action responses Upstream default raw=0 (not necessarily valid data).";
CM_ SG_ 852 RemoteResponsePackageCounter "DATABASE_CANDIDATE: physical interpretation unverified; capture/layout evidence reported separately. PSA-RE bits 1.7-1.4. Counter for remote action responses Upstream default raw=0 (not necessarily valid data).";
CM_ BO_ 858 "DATABASE_CANDIDATE: physical interpretation unverified; capture/layout evidence reported separately. INFO-DIV CAN, 125000 bit/s; CAN ID 0x35A. PSA-RE title: NAV_SPEED_SECTION_COMMAND. Navigation speed-limit section data sent to the powertrain ECU: activation, remaining distance and time, and distance to up to five upcoming speed sections. Source: https://github.com/prototux/PSA-RE/blob/67f7581e7622410efdbb29c7eda3b86982b9b450/buses/AEE2010.full/LS.INFO-DIV/35A.yml. Source sender alternatives: BTEL,OVIP; physical TX/gateway forwarding not verified. Unresolved alternative source layouts preserved in source JSON. ";
CM_ SG_ 858 TotalRemainingTime "DATABASE_CANDIDATE: physical interpretation unverified; capture/layout evidence reported separately. PSA-RE bits 7.3-8.0. Total remaining time Raw invalid=4095; numeric DBC decoders may still scale it: check raw before use.";
CM_ SG_ 858 TotalRemainingDistance "DATABASE_CANDIDATE: physical interpretation unverified; capture/layout evidence reported separately. PSA-RE bits 6.7-7.4. Total remaining distance Raw invalid=4095; numeric DBC decoders may still scale it: check raw before use.";
CM_ SG_ 858 Unused4 "DATABASE_CANDIDATE: physical interpretation unverified; capture/layout evidence reported separately. PSA-RE bits 5.0. ";
CM_ SG_ 858 RemainingDistanceSpeedAbove90 "DATABASE_CANDIDATE: physical interpretation unverified; capture/layout evidence reported separately. PSA-RE bits 5.7-5.1. Percentage of remaining distance above 90 km/h Raw invalid=127; numeric DBC decoders may still scale it: check raw before use.";
CM_ SG_ 858 Unused3 "DATABASE_CANDIDATE: physical interpretation unverified; capture/layout evidence reported separately. PSA-RE bits 4.0. ";
CM_ SG_ 858 RemainingDistanceSpeed7090 "DATABASE_CANDIDATE: physical interpretation unverified; capture/layout evidence reported separately. PSA-RE bits 4.7-4.1. Percentage of remaining distance at 70-90 km/h Raw invalid=127; numeric DBC decoders may still scale it: check raw before use.";
CM_ SG_ 858 Unused2 "DATABASE_CANDIDATE: physical interpretation unverified; capture/layout evidence reported separately. PSA-RE bits 3.0. ";
CM_ SG_ 858 RemainingDistanceSpeed5070 "DATABASE_CANDIDATE: physical interpretation unverified; capture/layout evidence reported separately. PSA-RE bits 3.7-3.1. Percentage of remaining distance at 50-70 km/h Raw invalid=127; numeric DBC decoders may still scale it: check raw before use.";
CM_ SG_ 858 Unused1 "DATABASE_CANDIDATE: physical interpretation unverified; capture/layout evidence reported separately. PSA-RE bits 2.0. ";
CM_ SG_ 858 RemainingDistanceSpeed3050 "DATABASE_CANDIDATE: physical interpretation unverified; capture/layout evidence reported separately. PSA-RE bits 2.7-2.1. Percentage of remaining distance at 30-50 km/h Raw invalid=127; numeric DBC decoders may still scale it: check raw before use.";
CM_ SG_ 858 RangeBySpeedActivation "DATABASE_CANDIDATE: physical interpretation unverified; capture/layout evidence reported separately. PSA-RE bits 1.0. Range-by-speed-section function activation";
CM_ SG_ 858 RemainingDistanceSpeed030 "DATABASE_CANDIDATE: physical interpretation unverified; capture/layout evidence reported separately. PSA-RE bits 1.7-1.1. Percentage of remaining distance at 0-30 km/h Raw invalid=127; numeric DBC decoders may still scale it: check raw before use.";
CM_ BO_ 859 "DATABASE_CANDIDATE: physical interpretation unverified; capture/layout evidence reported separately. INFO-DIV CAN, 125000 bit/s; CAN ID 0x35B. PSA-RE title: CHARGE_PROGRAM_SCREEN_REMOTE. Charge programming screen requests from the remote app: energy target, start time and charge type. Source: https://github.com/prototux/PSA-RE/blob/67f7581e7622410efdbb29c7eda3b86982b9b450/buses/AEE2010.full/LS.INFO-DIV/35B.yml. Source sender alternatives: MDS; physical TX/gateway forwarding not verified. Observed 1 frames in info_apka.csv; DLCs [2]. ";
CM_ SG_ 859 ChargeScheduleStartTimeRemote "DATABASE_CANDIDATE: physical interpretation unverified; capture/layout evidence reported separately. PSA-RE bits 1.2-2.0. Memorized start time of the remote scheduled charge";
CM_ SG_ 859 ChargeTargetLevelRemote "DATABASE_CANDIDATE: physical interpretation unverified; capture/layout evidence reported separately. PSA-RE bits 1.4-1.3. Memorized remote charge target level setting";
CM_ SG_ 859 RawBits2_2 "RAW. PSA-RE bits 1.5-1.5. Unmapped/padding bits, no physical interpretation.";
CM_ SG_ 859 ChargeTypeSelectionRemote "DATABASE_CANDIDATE: physical interpretation unverified; capture/layout evidence reported separately. PSA-RE bits 1.6. Remote charge type menu display: immediate or deferred";
CM_ SG_ 859 ChargeScheduleRemoteMenuA_155510 "DATABASE_CANDIDATE: physical interpretation unverified; capture/layout evidence reported separately. PSA-RE bits 1.7. Availability status of the remote charge schedule function";
CM_ BO_ 863 "DATABASE_CANDIDATE: physical interpretation unverified; capture/layout evidence reported separately. INFO-DIV CAN, 125000 bit/s; CAN ID 0x35F. PSA-RE title: NAV_DATABASE_STATUS_ACK_REP. Acknowledgement of a multi-frame navigation database status message (REP). Source: https://github.com/prototux/PSA-RE/blob/67f7581e7622410efdbb29c7eda3b86982b9b450/buses/AEE2010.full/LS.INFO-DIV/35F.yml. Source sender alternatives: EMF,ICSV; physical TX/gateway forwarding not verified. ";
CM_ SG_ 863 SegmentationAckStream "DATABASE_CANDIDATE: physical interpretation unverified; capture/layout evidence reported separately. PSA-RE bits 1.7-1.0. Segmentation acknowledgment stream";
CM_ BO_ 864 "DATABASE_CANDIDATE: physical interpretation unverified; capture/layout evidence reported separately. INFO-DIV CAN, 125000 bit/s; CAN ID 0x360. PSA-RE title: VEHICLE_PARAMETER_DATA. Vehicle parameter data payload (content depends on the parameter requested). Source: https://github.com/prototux/PSA-RE/blob/67f7581e7622410efdbb29c7eda3b86982b9b450/buses/AEE2010.full/LS.INFO-DIV/360.yml. Source sender alternatives: ICSV,BSI; physical TX/gateway forwarding not verified. WIRE ISO-TP ONLY: normal addressing candidate, maximum Classical CAN DLC 8; actual DLC may be shorter. Data includes padding. No reassembly, text, DID or application-layer decoding. Original application layouts are preserved in source JSON; do not decode them at wire offsets. ";
CM_ SG_ 864 FlowPadding5 "TRANSPORT_CANDIDATE: normal-addressing ISO-TP. PSA-RE bits 8.7-8.0. ";
CM_ SG_ 864 FirstData6 "TRANSPORT_CANDIDATE: normal-addressing ISO-TP. PSA-RE bits 8.7-8.0. ";
CM_ SG_ 864 UnknownData7 "TRANSPORT_CANDIDATE: normal-addressing ISO-TP. PSA-RE bits 8.7-8.0. ";
CM_ SG_ 864 ConsecutiveData7 "TRANSPORT_CANDIDATE: normal-addressing ISO-TP. PSA-RE bits 8.7-8.0. ";
CM_ SG_ 864 SingleData7 "TRANSPORT_CANDIDATE: normal-addressing ISO-TP. PSA-RE bits 8.7-8.0. ";
CM_ SG_ 864 FlowPadding4 "TRANSPORT_CANDIDATE: normal-addressing ISO-TP. PSA-RE bits 7.7-7.0. ";
CM_ SG_ 864 FirstData5 "TRANSPORT_CANDIDATE: normal-addressing ISO-TP. PSA-RE bits 7.7-7.0. ";
CM_ SG_ 864 UnknownData6 "TRANSPORT_CANDIDATE: normal-addressing ISO-TP. PSA-RE bits 7.7-7.0. ";
CM_ SG_ 864 ConsecutiveData6 "TRANSPORT_CANDIDATE: normal-addressing ISO-TP. PSA-RE bits 7.7-7.0. ";
CM_ SG_ 864 SingleData6 "TRANSPORT_CANDIDATE: normal-addressing ISO-TP. PSA-RE bits 7.7-7.0. ";
CM_ SG_ 864 FlowPadding3 "TRANSPORT_CANDIDATE: normal-addressing ISO-TP. PSA-RE bits 6.7-6.0. ";
CM_ SG_ 864 FirstData4 "TRANSPORT_CANDIDATE: normal-addressing ISO-TP. PSA-RE bits 6.7-6.0. ";
CM_ SG_ 864 UnknownData5 "TRANSPORT_CANDIDATE: normal-addressing ISO-TP. PSA-RE bits 6.7-6.0. ";
CM_ SG_ 864 ConsecutiveData5 "TRANSPORT_CANDIDATE: normal-addressing ISO-TP. PSA-RE bits 6.7-6.0. ";
CM_ SG_ 864 SingleData5 "TRANSPORT_CANDIDATE: normal-addressing ISO-TP. PSA-RE bits 6.7-6.0. ";
CM_ SG_ 864 FlowPadding2 "TRANSPORT_CANDIDATE: normal-addressing ISO-TP. PSA-RE bits 5.7-5.0. ";
CM_ SG_ 864 FirstData3 "TRANSPORT_CANDIDATE: normal-addressing ISO-TP. PSA-RE bits 5.7-5.0. ";
CM_ SG_ 864 UnknownData4 "TRANSPORT_CANDIDATE: normal-addressing ISO-TP. PSA-RE bits 5.7-5.0. ";
CM_ SG_ 864 ConsecutiveData4 "TRANSPORT_CANDIDATE: normal-addressing ISO-TP. PSA-RE bits 5.7-5.0. ";
CM_ SG_ 864 SingleData4 "TRANSPORT_CANDIDATE: normal-addressing ISO-TP. PSA-RE bits 5.7-5.0. ";
CM_ SG_ 864 FlowPadding1 "TRANSPORT_CANDIDATE: normal-addressing ISO-TP. PSA-RE bits 4.7-4.0. ";
CM_ SG_ 864 FirstData2 "TRANSPORT_CANDIDATE: normal-addressing ISO-TP. PSA-RE bits 4.7-4.0. ";
CM_ SG_ 864 UnknownData3 "TRANSPORT_CANDIDATE: normal-addressing ISO-TP. PSA-RE bits 4.7-4.0. ";
CM_ SG_ 864 ConsecutiveData3 "TRANSPORT_CANDIDATE: normal-addressing ISO-TP. PSA-RE bits 4.7-4.0. ";
CM_ SG_ 864 SingleData3 "TRANSPORT_CANDIDATE: normal-addressing ISO-TP. PSA-RE bits 4.7-4.0. ";
CM_ SG_ 864 FirstData1 "TRANSPORT_CANDIDATE: normal-addressing ISO-TP. PSA-RE bits 3.7-3.0. ";
CM_ SG_ 864 UnknownData2 "TRANSPORT_CANDIDATE: normal-addressing ISO-TP. PSA-RE bits 3.7-3.0. ";
CM_ SG_ 864 ConsecutiveData2 "TRANSPORT_CANDIDATE: normal-addressing ISO-TP. PSA-RE bits 3.7-3.0. ";
CM_ SG_ 864 SingleData2 "TRANSPORT_CANDIDATE: normal-addressing ISO-TP. PSA-RE bits 3.7-3.0. ";
CM_ SG_ 864 SeparationTimeRaw "TRANSPORT_CANDIDATE: normal-addressing ISO-TP. PSA-RE bits 3.7-3.0. Raw STmin code; 0xF1..0xF9 are not milliseconds.";
CM_ SG_ 864 UnknownData1 "TRANSPORT_CANDIDATE: normal-addressing ISO-TP. PSA-RE bits 2.7-2.0. ";
CM_ SG_ 864 ConsecutiveData1 "TRANSPORT_CANDIDATE: normal-addressing ISO-TP. PSA-RE bits 2.7-2.0. ";
CM_ SG_ 864 SingleData1 "TRANSPORT_CANDIDATE: normal-addressing ISO-TP. PSA-RE bits 2.7-2.0. ";
CM_ SG_ 864 BlockSize "TRANSPORT_CANDIDATE: normal-addressing ISO-TP. PSA-RE bits 2.7-2.0. ";
CM_ SG_ 864 UnknownPciLow "TRANSPORT_CANDIDATE: normal-addressing ISO-TP. PSA-RE bits 1.3-1.0. ";
CM_ SG_ 864 FlowStatus "TRANSPORT_CANDIDATE: normal-addressing ISO-TP. PSA-RE bits 1.3-1.0. ";
CM_ SG_ 864 ConsecutiveSequence "TRANSPORT_CANDIDATE: normal-addressing ISO-TP. PSA-RE bits 1.3-1.0. ";
CM_ SG_ 864 FirstFrameLength "TRANSPORT_CANDIDATE: normal-addressing ISO-TP. PSA-RE bits 1.3-2.0. 12-bit declared PDU length; not a reassembled value.";
CM_ SG_ 864 SingleFrameLength "TRANSPORT_CANDIDATE: normal-addressing ISO-TP. PSA-RE bits 1.3-1.0. Declared data length; not a validity check.";
CM_ SG_ 864 IsoTpFrameType "TRANSPORT_CANDIDATE: normal-addressing ISO-TP. PSA-RE bits 1.7-1.4. PCI high nibble; normal addressing candidate.";
CM_ BO_ 865 "DATABASE_CANDIDATE: physical interpretation unverified; capture/layout evidence reported separately. INFO-DIV CAN, 125000 bit/s; CAN ID 0x361. PSA-RE title: VEHICLE_FEATURE_AVAILABILITY. Vehicle equipment availability sent by the BSI on change: parking sensors, auto lighting, auto wiping, daytime running lights and active profile number. Source: https://github.com/prototux/PSA-RE/blob/67f7581e7622410efdbb29c7eda3b86982b9b450/buses/AEE2010.full/LS.INFO-DIV/361.yml. Source sender alternatives: BSI; physical TX/gateway forwarding not verified. Observed 1174 frames in info_apka.csv,info_buzeni_obc.csv,info_charging.csv,info_standby.csv,info_start_jizda.csv,infocan.csv; DLCs [8]. Unresolved alternative source layouts preserved in source JSON. ";
CM_ SG_ 865 RawByte8 "RAW. PSA-RE bits 8.7-8.0. Unmapped/padding bits, no physical interpretation.";
CM_ SG_ 865 Unused2 "DATABASE_CANDIDATE: physical interpretation unverified; capture/layout evidence reported separately. PSA-RE bits 7.0. ";
CM_ SG_ 865 RtabRechargeMenuDisplayAu_d73943 "DATABASE_CANDIDATE: physical interpretation unverified; capture/layout evidence reported separately. PSA-RE bits 7.1. Vehicle authorization to display the RTAB recharge settings menu Upstream default raw=0 (not necessarily valid data).";
CM_ SG_ 865 ClimatePrecondMenuDisplay_2fd6ce "DATABASE_CANDIDATE: physical interpretation unverified; capture/layout evidence reported separately. PSA-RE bits 7.2. Vehicle authorization to display the climate preconditioning settings menu Upstream default raw=0 (not necessarily valid data).";
CM_ SG_ 865 AmlaMenuPresence "DATABASE_CANDIDATE: physical interpretation unverified; capture/layout evidence reported separately. PSA-RE bits 7.3. Vehicle authorisation to display the automatic hands-free access (AMLA) settings menu Upstream default raw=0 (not necessarily valid data).";
CM_ SG_ 865 AdsdMenuPresence "DATABASE_CANDIDATE: physical interpretation unverified; capture/layout evidence reported separately. PSA-RE bits 7.4. Vehicle authorisation to display the ADSD settings menu Upstream default raw=0 (not necessarily valid data).";
CM_ SG_ 865 PrivacyModeMenuPresence "DATABASE_CANDIDATE: physical interpretation unverified; capture/layout evidence reported separately. PSA-RE bits 7.5. Vehicle authorisation to display the Privacy mode settings menu Upstream default raw=0 (not necessarily valid data).";
CM_ SG_ 865 ArsMenuPresence "DATABASE_CANDIDATE: physical interpretation unverified; capture/layout evidence reported separately. PSA-RE bits 7.6. Vehicle authorisation to display the ARS settings menu Upstream default raw=0 (not necessarily valid data).";
CM_ SG_ 865 AfsMenuPresence "DATABASE_CANDIDATE: physical interpretation unverified; capture/layout evidence reported separately. PSA-RE bits 7.7. Vehicle authorisation to display the AFS settings menu Upstream default raw=0 (not necessarily valid data).";
CM_ SG_ 865 IrvMenuPresence "DATABASE_CANDIDATE: physical interpretation unverified; capture/layout evidence reported separately. PSA-RE bits 6.0. Vehicle authorisation to display the IRV settings menu Upstream default raw=0 (not necessarily valid data).";
CM_ SG_ 865 PolychromePackBlockMenuPresence "DATABASE_CANDIDATE: physical interpretation unverified; capture/layout evidence reported separately. PSA-RE bits 6.1. Vehicle authorisation to display the polychrome pack block settings menu Upstream default raw=0 (not necessarily valid data).";
CM_ SG_ 865 PpcAnimationPresence "DATABASE_CANDIDATE: physical interpretation unverified; capture/layout evidence reported separately. PSA-RE bits 6.2. Presence of the PPC animation option Upstream default raw=0 (not necessarily valid data).";
CM_ SG_ 865 Dae4wdPresence "DATABASE_CANDIDATE: physical interpretation unverified; capture/layout evidence reported separately. PSA-RE bits 6.3. Presence of the DAE 4WD option Upstream default raw=0 (not necessarily valid data).";
CM_ SG_ 865 DaePresence "DATABASE_CANDIDATE: physical interpretation unverified; capture/layout evidence reported separately. PSA-RE bits 6.4. Presence of the DAE option Upstream default raw=0 (not necessarily valid data).";
CM_ SG_ 865 CafrMenuPresence "DATABASE_CANDIDATE: physical interpretation unverified; capture/layout evidence reported separately. PSA-RE bits 6.5. Vehicle authorisation to display the CAFR settings menu Upstream default raw=0 (not necessarily valid data).";
CM_ SG_ 865 EcsModeMenuPresence "DATABASE_CANDIDATE: physical interpretation unverified; capture/layout evidence reported separately. PSA-RE bits 6.6. Vehicle authorisation to display the ECS mode settings menu Upstream default raw=0 (not necessarily valid data).";
CM_ SG_ 865 DriverAlertAssistMenuPresence "DATABASE_CANDIDATE: physical interpretation unverified; capture/layout evidence reported separately. PSA-RE bits 6.7. Vehicle authorisation to display the Driver Alert Assist settings menu Upstream default raw=0 (not necessarily valid data).";
CM_ SG_ 865 LoadedArmsLockMenuPresence "DATABASE_CANDIDATE: physical interpretation unverified; capture/layout evidence reported separately. PSA-RE bits 5.0. Vehicle authorisation to display the \"loaded arms access\" lock settings menu Upstream default raw=0 (not necessarily valid data).";
CM_ SG_ 865 UserProfilePresence "DATABASE_CANDIDATE: physical interpretation unverified; capture/layout evidence reported separately. PSA-RE bits 5.1. Presence of the user profile option Upstream default raw=0 (not necessarily valid data).";
CM_ SG_ 865 LoadedArmsAccessMenuPresence "DATABASE_CANDIDATE: physical interpretation unverified; capture/layout evidence reported separately. PSA-RE bits 5.2. Vehicle authorisation to display the \"loaded arms access\" settings menu Upstream default raw=0 (not necessarily valid data).";
CM_ SG_ 865 IlvPresence "DATABASE_CANDIDATE: physical interpretation unverified; capture/layout evidence reported separately. PSA-RE bits 5.3. Presence of the ILV option Upstream default raw=0 (not necessarily valid data).";
CM_ SG_ 865 GrilleLightingPresence "DATABASE_CANDIDATE: physical interpretation unverified; capture/layout evidence reported separately. PSA-RE bits 5.4. Presence of the radiator grille lighting Upstream default raw=0 (not necessarily valid data).";
CM_ SG_ 865 LowCurrentChargePresence "DATABASE_CANDIDATE: physical interpretation unverified; capture/layout evidence reported separately. PSA-RE bits 5.5. Presence of the low current charge option Upstream default raw=0 (not necessarily valid data).";
CM_ SG_ 865 Unused1 "DATABASE_CANDIDATE: physical interpretation unverified; capture/layout evidence reported separately. PSA-RE bits 5.7-5.6. ";
CM_ SG_ 865 TpmsPresence "DATABASE_CANDIDATE: physical interpretation unverified; capture/layout evidence reported separately. PSA-RE bits 4.2-4.0. Presence and type of the tyre pressure monitoring system";
CM_ SG_ 865 IrcPresence "DATABASE_CANDIDATE: physical interpretation unverified; capture/layout evidence reported separately. PSA-RE bits 4.3. Presence of the IRC option";
CM_ SG_ 865 XvvSpeedMenuPresence "DATABASE_CANDIDATE: physical interpretation unverified; capture/layout evidence reported separately. PSA-RE bits 4.4. Presence of the XVV (cruise/limiter) speed menu Upstream default raw=0 (not necessarily valid data).";
CM_ SG_ 865 ArcSensitivityMenuPresence "DATABASE_CANDIDATE: physical interpretation unverified; capture/layout evidence reported separately. PSA-RE bits 4.5. Presence of the ARC sensitivity menu Upstream default raw=0 (not necessarily valid data).";
CM_ SG_ 865 CollisionRiskBrakingOptio_4c4434 "DATABASE_CANDIDATE: physical interpretation unverified; capture/layout evidence reported separately. PSA-RE bits 4.6. Presence of the collision-risk automatic braking option Upstream default raw=0 (not necessarily valid data).";
CM_ SG_ 865 TpmsReinitializationOptio_aa6f62 "DATABASE_CANDIDATE: physical interpretation unverified; capture/layout evidence reported separately. PSA-RE bits 4.7. Presence of the tyre pressure monitoring reset menu Upstream default raw=0 (not necessarily valid data).";
CM_ SG_ 865 PpcPresence "DATABASE_CANDIDATE: physical interpretation unverified; capture/layout evidence reported separately. PSA-RE bits 3.0. Presence of the PPC option Upstream default raw=0 (not necessarily valid data).";
CM_ SG_ 865 EtsrMenuPresence "DATABASE_CANDIDATE: physical interpretation unverified; capture/layout evidence reported separately. PSA-RE bits 3.1. Vehicle authorisation to display the ETSR settings menu Upstream default raw=0 (not necessarily valid data).";
CM_ SG_ 865 ReverseIndexingPresence "DATABASE_CANDIDATE: physical interpretation unverified; capture/layout evidence reported separately. PSA-RE bits 3.2. Presence of the reverse gear indexing function Upstream default raw=0 (not necessarily valid data).";
CM_ SG_ 865 SoundHarmonyOptionPresence "DATABASE_CANDIDATE: physical interpretation unverified; capture/layout evidence reported separately. PSA-RE bits 3.3. Presence of the sound harmony option Upstream default raw=0 (not necessarily valid data).";
CM_ SG_ 865 ElectricParkingBrakeOptio_c6beca "DATABASE_CANDIDATE: physical interpretation unverified; capture/layout evidence reported separately. PSA-RE bits 3.4. Presence of the automatic electric parking brake application option";
CM_ SG_ 865 CongigurableKeyOption "DATABASE_CANDIDATE: physical interpretation unverified; capture/layout evidence reported separately. PSA-RE bits 3.5. Presence of the configurable key configuration option";
CM_ SG_ 865 XvvLimitsMenuPresence "DATABASE_CANDIDATE: physical interpretation unverified; capture/layout evidence reported separately. PSA-RE bits 3.6. Presence of the cruise/speed limiter stop adjustment menu Upstream default raw=0 (not necessarily valid data).";
CM_ SG_ 865 NblPresence "DATABASE_CANDIDATE: physical interpretation unverified; capture/layout evidence reported separately. PSA-RE bits 3.7. Presence of the NBL casing";
CM_ SG_ 865 CabOpeningsSelectivityCus_fd4768 "DATABASE_CANDIDATE: physical interpretation unverified; capture/layout evidence reported separately. PSA-RE bits 2.0. Customization of the cab openings selectivity function Upstream default raw=0 (not necessarily valid data).";
CM_ SG_ 865 DoorSelectivityOptionPresence "DATABASE_CANDIDATE: physical interpretation unverified; capture/layout evidence reported separately. PSA-RE bits 2.1. Presence of the door selectivity at key option";
CM_ SG_ 865 RearOpeningsSelectivityOp_53876f "DATABASE_CANDIDATE: physical interpretation unverified; capture/layout evidence reported separately. PSA-RE bits 2.2. Presence of the rear openings selectivity option";
CM_ SG_ 865 RearFlapMotorizationCusto_5e7171 "DATABASE_CANDIDATE: physical interpretation unverified; capture/layout evidence reported separately. PSA-RE bits 2.3. Customization of the rear flap motorization function Upstream default raw=0 (not necessarily valid data).";
CM_ SG_ 865 DriverGreetingPresence "DATABASE_CANDIDATE: physical interpretation unverified; capture/layout evidence reported separately. PSA-RE bits 2.4. Presence of the driver greeting (welcome) function";
CM_ SG_ 865 FollowMeHomeOptionPresence "DATABASE_CANDIDATE: physical interpretation unverified; capture/layout evidence reported separately. PSA-RE bits 2.5. Presence of the \"Follow me Home\" escort lighting option";
CM_ SG_ 865 RearWiperInReverseOptionPresence "DATABASE_CANDIDATE: physical interpretation unverified; capture/layout evidence reported separately. PSA-RE bits 2.6. Presence of the rear wiper in reverse gear option";
CM_ SG_ 865 ParkingAidInhibitionOptio_937dc5 "DATABASE_CANDIDATE: physical interpretation unverified; capture/layout evidence reported separately. PSA-RE bits 2.7. Total inhibition of the parking assistance system (option presence)";
CM_ SG_ 865 DaylightsOptionPresence "DATABASE_CANDIDATE: physical interpretation unverified; capture/layout evidence reported separately. PSA-RE bits 1.0. Presence of the daytime running lights option";
CM_ SG_ 865 AutomaticHeadlightsSwitch_2a5f4f "DATABASE_CANDIDATE: physical interpretation unverified; capture/layout evidence reported separately. PSA-RE bits 1.1. Presence of the automatic headlights switching on option";
CM_ SG_ 865 AmbientLightingPresence "DATABASE_CANDIDATE: physical interpretation unverified; capture/layout evidence reported separately. PSA-RE bits 1.2. Presence of ambient lighting";
CM_ SG_ 865 BlindSpotMonitoringPresence "DATABASE_CANDIDATE: physical interpretation unverified; capture/layout evidence reported separately. PSA-RE bits 1.3. Presence of blind spot monitoring";
CM_ SG_ 865 AdaptiveLightingOptionPresence "DATABASE_CANDIDATE: physical interpretation unverified; capture/layout evidence reported separately. PSA-RE bits 1.4. Presence of the adaptive lighting option";
CM_ SG_ 865 UnlockingLightingCustomiz_78a725 "DATABASE_CANDIDATE: physical interpretation unverified; capture/layout evidence reported separately. PSA-RE bits 1.5. Customization of the unlocking lighting function Upstream default raw=0 (not necessarily valid data).";
CM_ SG_ 865 MotorwayLightingFunctionPresence "DATABASE_CANDIDATE: physical interpretation unverified; capture/layout evidence reported separately. PSA-RE bits 1.6. Presence of the motorway lighting function Upstream default raw=0 (not necessarily valid data).";
CM_ SG_ 865 SettingsMenuInfoAvailability "DATABASE_CANDIDATE: physical interpretation unverified; capture/layout evidence reported separately. PSA-RE bits 1.7. Overall availability of the settings menu information Upstream default raw=0 (not necessarily valid data).";
CM_ BO_ 868 "DATABASE_CANDIDATE: physical interpretation unverified; capture/layout evidence reported separately. INFO-DIV CAN, 125000 bit/s; CAN ID 0x364. PSA-RE title: TOUCH_CLIMATE_PANEL_STATUS. Touch-sensitive climate panel button requests: slider level, blower and temperature level changes, max A/C, air-quality sensor, automatic mode intensity (light/normal/strong). Source: https://github.com/prototux/PSA-RE/blob/67f7581e7622410efdbb29c7eda3b86982b9b450/buses/AEE2010.full/LS.INFO-DIV/364.yml. Source sender alternatives: BTEL,OVIP; physical TX/gateway forwarding not verified. Observed 586 frames in info_apka.csv,info_buzeni_obc.csv,info_charging.csv,info_standby.csv,info_start_jizda.csv,infocan.csv; DLCs [7]. SOURCE_DLC_MISMATCH: source 6, observed/exported 7. Fitting fields retained; additional bytes raw. ";
CM_ SG_ 868 RawByte7 "RAW. PSA-RE bits 7.7-7.0. Unmapped/padding bits, no physical interpretation.";
CM_ SG_ 868 Unused1 "DATABASE_CANDIDATE: physical interpretation unverified; capture/layout evidence reported separately. PSA-RE bits 6.3-6.0. ";
CM_ SG_ 868 FrontLeftSeatVentilationButton "DATABASE_CANDIDATE: physical interpretation unverified; capture/layout evidence reported separately. PSA-RE bits 6.4. Button press for the front left ventilated seat Upstream default raw=0 (not necessarily valid data).";
CM_ SG_ 868 FrontRightSeatVentilationButton "DATABASE_CANDIDATE: physical interpretation unverified; capture/layout evidence reported separately. PSA-RE bits 6.5. Button press for the front right ventilated seat Upstream default raw=0 (not necessarily valid data).";
CM_ SG_ 868 FrontLeftSeatHeaterButton "DATABASE_CANDIDATE: physical interpretation unverified; capture/layout evidence reported separately. PSA-RE bits 6.6. Button press for the front left heated seat Upstream default raw=0 (not necessarily valid data).";
CM_ SG_ 868 FrontRightSeatHeaterButton "DATABASE_CANDIDATE: physical interpretation unverified; capture/layout evidence reported separately. PSA-RE bits 6.7. Button press for the front right heated seat Upstream default raw=0 (not necessarily valid data).";
CM_ SG_ 868 AcOffButton "DATABASE_CANDIDATE: physical interpretation unverified; capture/layout evidence reported separately. PSA-RE bits 5.0. AC OFF button state Upstream default raw=0 (not necessarily valid data).";
CM_ SG_ 868 ClimateSliderLevelChange "DATABASE_CANDIDATE: physical interpretation unverified; capture/layout evidence reported separately. PSA-RE bits 5.1. User press on a climate slider (temperature or fan) Upstream default raw=0 (not necessarily valid data).";
CM_ SG_ 868 RearClimateLockButton "DATABASE_CANDIDATE: physical interpretation unverified; capture/layout evidence reported separately. PSA-RE bits 5.2. User demand on the rear climate lock function Upstream default raw=0 (not necessarily valid data).";
CM_ SG_ 868 FrontRightDefrostButton "DATABASE_CANDIDATE: physical interpretation unverified; capture/layout evidence reported separately. PSA-RE bits 5.3. User demand for front right air flow directed to the windscreen Upstream default raw=0 (not necessarily valid data).";
CM_ SG_ 868 FrontFanLevelSlider "DATABASE_CANDIDATE: physical interpretation unverified; capture/layout evidence reported separately. PSA-RE bits 5.7-5.4. Touchscreen slider level for the front fan speed Upstream default raw=14 (not necessarily valid data).";
CM_ SG_ 868 FrontRightVentAirflowButton "DATABASE_CANDIDATE: physical interpretation unverified; capture/layout evidence reported separately. PSA-RE bits 4.0. User demand for front right air flow directed to the face vents Upstream default raw=0 (not necessarily valid data).";
CM_ SG_ 868 FrontRightFootAirflowButton "DATABASE_CANDIDATE: physical interpretation unverified; capture/layout evidence reported separately. PSA-RE bits 4.1. User demand for front right air flow directed to the footwell Upstream default raw=0 (not necessarily valid data).";
CM_ SG_ 868 FrontRightTempLevelSlider "DATABASE_CANDIDATE: physical interpretation unverified; capture/layout evidence reported separately. PSA-RE bits 4.6-4.2. Touchscreen slider level for the front right temperature Upstream default raw=30 (not necessarily valid data).";
CM_ SG_ 868 EnergySaverModeButton "DATABASE_CANDIDATE: physical interpretation unverified; capture/layout evidence reported separately. PSA-RE bits 4.7. Energy saver mode button state Upstream default raw=0 (not necessarily valid data).";
CM_ SG_ 868 FrontLeftTempSetpoint "DATABASE_CANDIDATE: physical interpretation unverified; capture/layout evidence reported separately. PSA-RE bits 3.4-3.0. Front left temperature setpoint Upstream default raw=30 (not necessarily valid data).";
CM_ SG_ 868 RearClimateOnoffButton "DATABASE_CANDIDATE: physical interpretation unverified; capture/layout evidence reported separately. PSA-RE bits 3.5. Status of pressing the rear climate on/off button Upstream default raw=0 (not necessarily valid data).";
CM_ SG_ 868 AcMaxButton "DATABASE_CANDIDATE: physical interpretation unverified; capture/layout evidence reported separately. PSA-RE bits 3.6. Status of pressing the AC max button Upstream default raw=0 (not necessarily valid data).";
CM_ SG_ 868 AcAutoStrongButton "DATABASE_CANDIDATE: physical interpretation unverified; capture/layout evidence reported separately. PSA-RE bits 3.7. Status of pressing the climate auto-strong button Upstream default raw=0 (not necessarily valid data).";
CM_ SG_ 868 AcAutoNormalButton "DATABASE_CANDIDATE: physical interpretation unverified; capture/layout evidence reported separately. PSA-RE bits 2.0. Status of pressing the climate auto-normal button Upstream default raw=0 (not necessarily valid data).";
CM_ SG_ 868 AcAutoLightButton "DATABASE_CANDIDATE: physical interpretation unverified; capture/layout evidence reported separately. PSA-RE bits 2.1. Status of pressing the climate auto-light button Upstream default raw=0 (not necessarily valid data).";
CM_ SG_ 868 AcAutoButton "DATABASE_CANDIDATE: physical interpretation unverified; capture/layout evidence reported separately. PSA-RE bits 2.2. Status of pressing the climate auto button Upstream default raw=0 (not necessarily valid data).";
CM_ SG_ 868 AcButton "DATABASE_CANDIDATE: physical interpretation unverified; capture/layout evidence reported separately. PSA-RE bits 2.3. Status of pressing the AC button Upstream default raw=0 (not necessarily valid data).";
CM_ SG_ 868 MonoZoneButton "DATABASE_CANDIDATE: physical interpretation unverified; capture/layout evidence reported separately. PSA-RE bits 2.4. Status of pressing the single-zone climate button Upstream default raw=0 (not necessarily valid data).";
CM_ SG_ 868 AirQualitySensorButton "DATABASE_CANDIDATE: physical interpretation unverified; capture/layout evidence reported separately. PSA-RE bits 2.5. Status of pressing the air quality sensor (AQS) button Upstream default raw=0 (not necessarily valid data).";
CM_ SG_ 868 AirIntakeButton "DATABASE_CANDIDATE: physical interpretation unverified; capture/layout evidence reported separately. PSA-RE bits 2.6. Status of pressing the air intake (recirculation) button Upstream default raw=0 (not necessarily valid data).";
CM_ SG_ 868 FrontLeftDefrostButton "DATABASE_CANDIDATE: physical interpretation unverified; capture/layout evidence reported separately. PSA-RE bits 2.7. Status of pressing the front left defrost button Upstream default raw=0 (not necessarily valid data).";
CM_ SG_ 868 FrontLeftVentAirflowButton "DATABASE_CANDIDATE: physical interpretation unverified; capture/layout evidence reported separately. PSA-RE bits 1.0. Status of pressing the front left vent air-flow button Upstream default raw=0 (not necessarily valid data).";
CM_ SG_ 868 FrontLeftFootAirflowButton "DATABASE_CANDIDATE: physical interpretation unverified; capture/layout evidence reported separately. PSA-RE bits 1.1. Status of pressing the front left foot air-flow button Upstream default raw=0 (not necessarily valid data).";
CM_ SG_ 868 FrontFanMinusButton "DATABASE_CANDIDATE: physical interpretation unverified; capture/layout evidence reported separately. PSA-RE bits 1.2. Status of pressing the front fan speed minus button Upstream default raw=0 (not necessarily valid data).";
CM_ SG_ 868 FrontFanPlusButton "DATABASE_CANDIDATE: physical interpretation unverified; capture/layout evidence reported separately. PSA-RE bits 1.3. Status of pressing the front fan speed plus button Upstream default raw=0 (not necessarily valid data).";
CM_ SG_ 868 FrontRightTempMinusButton "DATABASE_CANDIDATE: physical interpretation unverified; capture/layout evidence reported separately. PSA-RE bits 1.4. Status of pressing the front right temperature minus button Upstream default raw=0 (not necessarily valid data).";
CM_ SG_ 868 FrontRightTempPlusButton "DATABASE_CANDIDATE: physical interpretation unverified; capture/layout evidence reported separately. PSA-RE bits 1.5. Status of pressing the front right temperature plus button Upstream default raw=0 (not necessarily valid data).";
CM_ SG_ 868 FrontLeftTempMinusButton "DATABASE_CANDIDATE: physical interpretation unverified; capture/layout evidence reported separately. PSA-RE bits 1.6. Status of pressing the front left temperature minus button Upstream default raw=0 (not necessarily valid data).";
CM_ SG_ 868 FrontLeftTempPlusButton "DATABASE_CANDIDATE: physical interpretation unverified; capture/layout evidence reported separately. PSA-RE bits 1.7. Status of pressing the front left temperature plus button Upstream default raw=0 (not necessarily valid data).";
CM_ BO_ 871 "DATABASE_CANDIDATE: physical interpretation unverified; capture/layout evidence reported separately. INFO-DIV CAN, 125000 bit/s; CAN ID 0x367. PSA-RE title: RADIO_STATUS_ACK_REP. Acknowledgement of a multi-frame radio status message (REP). Source: https://github.com/prototux/PSA-RE/blob/67f7581e7622410efdbb29c7eda3b86982b9b450/buses/AEE2010.full/LS.INFO-DIV/367.yml. Source sender alternatives: EMF,ICSV; physical TX/gateway forwarding not verified. ";
CM_ SG_ 871 SegmentationAckStream "DATABASE_CANDIDATE: physical interpretation unverified; capture/layout evidence reported separately. PSA-RE bits 1.7-1.0. Segmentation acknowledgment stream";
CM_ BO_ 872 "DATABASE_CANDIDATE: physical interpretation unverified; capture/layout evidence reported separately. INFO-DIV CAN, 125000 bit/s; CAN ID 0x368. PSA-RE title: GAS_ENGINE_CORRECTION_DATA. Elapsed and stopped time, and zero-emission time percentage, for the first saved trip. Source: https://github.com/prototux/PSA-RE/blob/67f7581e7622410efdbb29c7eda3b86982b9b450/buses/AEE2010.full/LS.INFO-DIV/368.yml. Source sender alternatives: BSI; physical TX/gateway forwarding not verified. Observed 586 frames in info_apka.csv,info_buzeni_obc.csv,info_charging.csv,info_standby.csv,info_start_jizda.csv,infocan.csv; DLCs [8]. Unresolved alternative source layouts preserved in source JSON. ";
CM_ SG_ 872 Unused4 "DATABASE_CANDIDATE: physical interpretation unverified; capture/layout evidence reported separately. PSA-RE bits 8.0. ";
CM_ SG_ 872 ZevDurationPercentTrip1Adjusted "DATABASE_CANDIDATE: physical interpretation unverified; capture/layout evidence reported separately. PSA-RE bits 8.7-8.1. Adjusted percentage of time spent in ZEV mode for trip 1 Raw invalid=127; numeric DBC decoders may still scale it: check raw before use. Upstream default raw=0 (not necessarily valid data).";
CM_ SG_ 872 Unused3 "DATABASE_CANDIDATE: physical interpretation unverified; capture/layout evidence reported separately. PSA-RE bits 7.0. ";
CM_ SG_ 872 ZevDurationPercentTrip1 "DATABASE_CANDIDATE: physical interpretation unverified; capture/layout evidence reported separately. PSA-RE bits 7.7-7.1. Percentage of time spent in ZEV mode relative to total time of trip 1 Raw invalid=127; numeric DBC decoders may still scale it: check raw before use. Upstream default raw=0 (not necessarily valid data).";
CM_ SG_ 872 Unused2 "DATABASE_CANDIDATE: physical interpretation unverified; capture/layout evidence reported separately. PSA-RE bits 6.0. ";
CM_ SG_ 872 ZevDurationSecondsTrip1 "DATABASE_CANDIDATE: physical interpretation unverified; capture/layout evidence reported separately. PSA-RE bits 6.6-6.1. Seconds component of the ZEV (engine-off) duration for trip 1 Raw invalid=63; numeric DBC decoders may still scale it: check raw before use. Upstream default raw=0 (not necessarily valid data).";
CM_ SG_ 872 ZevDurationMinutesTrip1 "DATABASE_CANDIDATE: physical interpretation unverified; capture/layout evidence reported separately. PSA-RE bits 5.4-6.7. Minutes component of the ZEV (engine-off) duration for trip 1 Raw invalid=63; numeric DBC decoders may still scale it: check raw before use. Upstream default raw=0 (not necessarily valid data).";
CM_ SG_ 872 ZevDurationHoursTrip1 "DATABASE_CANDIDATE: physical interpretation unverified; capture/layout evidence reported separately. PSA-RE bits 4.7-5.5. Hours component of the ZEV (engine-off) duration for trip 1 Raw invalid=2047; numeric DBC decoders may still scale it: check raw before use. Upstream default raw=0 (not necessarily valid data).";
CM_ SG_ 872 Unused1 "DATABASE_CANDIDATE: physical interpretation unverified; capture/layout evidence reported separately. PSA-RE bits 3.0. ";
CM_ SG_ 872 TripDurationSecondsTrip1 "DATABASE_CANDIDATE: physical interpretation unverified; capture/layout evidence reported separately. PSA-RE bits 3.6-3.1. Seconds component of the trip 1 duration Raw invalid=63; numeric DBC decoders may still scale it: check raw before use. Upstream default raw=0 (not necessarily valid data).";
CM_ SG_ 872 TripDurationMinutesTrip1 "DATABASE_CANDIDATE: physical interpretation unverified; capture/layout evidence reported separately. PSA-RE bits 2.4-3.7. Minutes component of the trip 1 duration Raw invalid=63; numeric DBC decoders may still scale it: check raw before use. Upstream default raw=0 (not necessarily valid data).";
CM_ SG_ 872 TripDurationHoursTrip1 "DATABASE_CANDIDATE: physical interpretation unverified; capture/layout evidence reported separately. PSA-RE bits 1.7-2.5. Hours component of the trip 1 duration Raw invalid=2047; numeric DBC decoders may still scale it: check raw before use. Upstream default raw=0 (not necessarily valid data).";
CM_ BO_ 873 "DATABASE_CANDIDATE: physical interpretation unverified; capture/layout evidence reported separately. INFO-DIV CAN, 125000 bit/s; CAN ID 0x369. PSA-RE title: TELEMATICS_HMI_AND_CONNECTIVITY_STATUS. Telematics unit status: HMI pop-up (id, priority, timeout), Wi-Fi security type, location service setting and roaming authorization/state. Source: https://github.com/prototux/PSA-RE/blob/67f7581e7622410efdbb29c7eda3b86982b9b450/buses/AEE2010.full/LS.INFO-DIV/369.yml. Source sender alternatives: MDS; physical TX/gateway forwarding not verified. ";
CM_ SG_ 873 Unused2 "DATABASE_CANDIDATE: physical interpretation unverified; capture/layout evidence reported separately. PSA-RE bits 4.4-4.0. ";
CM_ SG_ 873 RoamingState "DATABASE_CANDIDATE: physical interpretation unverified; capture/layout evidence reported separately. PSA-RE bits 4.5. Roaming state Upstream default raw=0 (not necessarily valid data).";
CM_ SG_ 873 RoamingAllowed "DATABASE_CANDIDATE: physical interpretation unverified; capture/layout evidence reported separately. PSA-RE bits 4.6. Indicates whether roaming is allowed Upstream default raw=0 (not necessarily valid data).";
CM_ SG_ 873 LocationServiceEnabled "DATABASE_CANDIDATE: physical interpretation unverified; capture/layout evidence reported separately. PSA-RE bits 4.7. Indicates whether location sharing with the telematics service provider is enabled Upstream default raw=0 (not necessarily valid data).";
CM_ SG_ 873 PopupPriority "DATABASE_CANDIDATE: physical interpretation unverified; capture/layout evidence reported separately. PSA-RE bits 3.3-3.0. Display priority of the pop-up Upstream default raw=0 (not necessarily valid data).";
CM_ SG_ 873 WifiSecurityType "DATABASE_CANDIDATE: physical interpretation unverified; capture/layout evidence reported separately. PSA-RE bits 3.5-3.4. Wi-Fi encryption type Upstream default raw=0 (not necessarily valid data).";
CM_ SG_ 873 Unused1 "DATABASE_CANDIDATE: physical interpretation unverified; capture/layout evidence reported separately. PSA-RE bits 3.7-3.6. ";
CM_ SG_ 873 PopupTimeout "DATABASE_CANDIDATE: physical interpretation unverified; capture/layout evidence reported separately. PSA-RE bits 2.7-2.0. Pop-up display timeout Upstream default raw=0 (not necessarily valid data).";
CM_ SG_ 873 PopupId "DATABASE_CANDIDATE: physical interpretation unverified; capture/layout evidence reported separately. PSA-RE bits 1.7-1.0. Identifier of the pop-up to display Upstream default raw=0 (not necessarily valid data).";
CM_ BO_ 886 "DATABASE_CANDIDATE: physical interpretation unverified; capture/layout evidence reported separately. INFO-DIV CAN, 125000 bit/s; CAN ID 0x376. PSA-RE title: WIFI_INFO_REPLY_FLOW_CONTROL. ISO-TP flow control frame for the Wi-Fi info reply multi-frame reply (block size, flow status, separation time). Source: https://github.com/prototux/PSA-RE/blob/67f7581e7622410efdbb29c7eda3b86982b9b450/buses/AEE2010.full/LS.INFO-DIV/376.yml. Source sender alternatives: BTEL,EMF,OVIP; physical TX/gateway forwarding not verified. WIRE ISO-TP ONLY: normal addressing candidate, maximum Classical CAN DLC 8; actual DLC may be shorter. Data includes padding. No reassembly, text, DID or application-layer decoding. Original application layouts are preserved in source JSON; do not decode them at wire offsets. ";
CM_ SG_ 886 FlowPadding5 "TRANSPORT_CANDIDATE: normal-addressing ISO-TP. PSA-RE bits 8.7-8.0. ";
CM_ SG_ 886 FirstData6 "TRANSPORT_CANDIDATE: normal-addressing ISO-TP. PSA-RE bits 8.7-8.0. ";
CM_ SG_ 886 UnknownData7 "TRANSPORT_CANDIDATE: normal-addressing ISO-TP. PSA-RE bits 8.7-8.0. ";
CM_ SG_ 886 ConsecutiveData7 "TRANSPORT_CANDIDATE: normal-addressing ISO-TP. PSA-RE bits 8.7-8.0. ";
CM_ SG_ 886 SingleData7 "TRANSPORT_CANDIDATE: normal-addressing ISO-TP. PSA-RE bits 8.7-8.0. ";
CM_ SG_ 886 FlowPadding4 "TRANSPORT_CANDIDATE: normal-addressing ISO-TP. PSA-RE bits 7.7-7.0. ";
CM_ SG_ 886 FirstData5 "TRANSPORT_CANDIDATE: normal-addressing ISO-TP. PSA-RE bits 7.7-7.0. ";
CM_ SG_ 886 UnknownData6 "TRANSPORT_CANDIDATE: normal-addressing ISO-TP. PSA-RE bits 7.7-7.0. ";
CM_ SG_ 886 ConsecutiveData6 "TRANSPORT_CANDIDATE: normal-addressing ISO-TP. PSA-RE bits 7.7-7.0. ";
CM_ SG_ 886 SingleData6 "TRANSPORT_CANDIDATE: normal-addressing ISO-TP. PSA-RE bits 7.7-7.0. ";
CM_ SG_ 886 FlowPadding3 "TRANSPORT_CANDIDATE: normal-addressing ISO-TP. PSA-RE bits 6.7-6.0. ";
CM_ SG_ 886 FirstData4 "TRANSPORT_CANDIDATE: normal-addressing ISO-TP. PSA-RE bits 6.7-6.0. ";
CM_ SG_ 886 UnknownData5 "TRANSPORT_CANDIDATE: normal-addressing ISO-TP. PSA-RE bits 6.7-6.0. ";
CM_ SG_ 886 ConsecutiveData5 "TRANSPORT_CANDIDATE: normal-addressing ISO-TP. PSA-RE bits 6.7-6.0. ";
CM_ SG_ 886 SingleData5 "TRANSPORT_CANDIDATE: normal-addressing ISO-TP. PSA-RE bits 6.7-6.0. ";
CM_ SG_ 886 FlowPadding2 "TRANSPORT_CANDIDATE: normal-addressing ISO-TP. PSA-RE bits 5.7-5.0. ";
CM_ SG_ 886 FirstData3 "TRANSPORT_CANDIDATE: normal-addressing ISO-TP. PSA-RE bits 5.7-5.0. ";
CM_ SG_ 886 UnknownData4 "TRANSPORT_CANDIDATE: normal-addressing ISO-TP. PSA-RE bits 5.7-5.0. ";
CM_ SG_ 886 ConsecutiveData4 "TRANSPORT_CANDIDATE: normal-addressing ISO-TP. PSA-RE bits 5.7-5.0. ";
CM_ SG_ 886 SingleData4 "TRANSPORT_CANDIDATE: normal-addressing ISO-TP. PSA-RE bits 5.7-5.0. ";
CM_ SG_ 886 FlowPadding1 "TRANSPORT_CANDIDATE: normal-addressing ISO-TP. PSA-RE bits 4.7-4.0. ";
CM_ SG_ 886 FirstData2 "TRANSPORT_CANDIDATE: normal-addressing ISO-TP. PSA-RE bits 4.7-4.0. ";
CM_ SG_ 886 UnknownData3 "TRANSPORT_CANDIDATE: normal-addressing ISO-TP. PSA-RE bits 4.7-4.0. ";
CM_ SG_ 886 ConsecutiveData3 "TRANSPORT_CANDIDATE: normal-addressing ISO-TP. PSA-RE bits 4.7-4.0. ";
CM_ SG_ 886 SingleData3 "TRANSPORT_CANDIDATE: normal-addressing ISO-TP. PSA-RE bits 4.7-4.0. ";
CM_ SG_ 886 FirstData1 "TRANSPORT_CANDIDATE: normal-addressing ISO-TP. PSA-RE bits 3.7-3.0. ";
CM_ SG_ 886 UnknownData2 "TRANSPORT_CANDIDATE: normal-addressing ISO-TP. PSA-RE bits 3.7-3.0. ";
CM_ SG_ 886 ConsecutiveData2 "TRANSPORT_CANDIDATE: normal-addressing ISO-TP. PSA-RE bits 3.7-3.0. ";
CM_ SG_ 886 SingleData2 "TRANSPORT_CANDIDATE: normal-addressing ISO-TP. PSA-RE bits 3.7-3.0. ";
CM_ SG_ 886 SeparationTimeRaw "TRANSPORT_CANDIDATE: normal-addressing ISO-TP. PSA-RE bits 3.7-3.0. Raw STmin code; 0xF1..0xF9 are not milliseconds.";
CM_ SG_ 886 UnknownData1 "TRANSPORT_CANDIDATE: normal-addressing ISO-TP. PSA-RE bits 2.7-2.0. ";
CM_ SG_ 886 ConsecutiveData1 "TRANSPORT_CANDIDATE: normal-addressing ISO-TP. PSA-RE bits 2.7-2.0. ";
CM_ SG_ 886 SingleData1 "TRANSPORT_CANDIDATE: normal-addressing ISO-TP. PSA-RE bits 2.7-2.0. ";
CM_ SG_ 886 BlockSize "TRANSPORT_CANDIDATE: normal-addressing ISO-TP. PSA-RE bits 2.7-2.0. ";
CM_ SG_ 886 UnknownPciLow "TRANSPORT_CANDIDATE: normal-addressing ISO-TP. PSA-RE bits 1.3-1.0. ";
CM_ SG_ 886 FlowStatus "TRANSPORT_CANDIDATE: normal-addressing ISO-TP. PSA-RE bits 1.3-1.0. ";
CM_ SG_ 886 ConsecutiveSequence "TRANSPORT_CANDIDATE: normal-addressing ISO-TP. PSA-RE bits 1.3-1.0. ";
CM_ SG_ 886 FirstFrameLength "TRANSPORT_CANDIDATE: normal-addressing ISO-TP. PSA-RE bits 1.3-2.0. 12-bit declared PDU length; not a reassembled value.";
CM_ SG_ 886 SingleFrameLength "TRANSPORT_CANDIDATE: normal-addressing ISO-TP. PSA-RE bits 1.3-1.0. Declared data length; not a validity check.";
CM_ SG_ 886 IsoTpFrameType "TRANSPORT_CANDIDATE: normal-addressing ISO-TP. PSA-RE bits 1.7-1.4. PCI high nibble; normal addressing candidate.";
CM_ BO_ 897 "DATABASE_CANDIDATE: physical interpretation unverified; capture/layout evidence reported separately. INFO-DIV CAN, 125000 bit/s; CAN ID 0x381. PSA-RE title: SDCM_APDU_FLOW_CONTROL. ISO-TP flow control frame for the SDCM data transfer Source: https://github.com/prototux/PSA-RE/blob/67f7581e7622410efdbb29c7eda3b86982b9b450/buses/AEE2010.full/LS.INFO-DIV/381.yml. Source sender alternatives: WLC; physical TX/gateway forwarding not verified. WIRE ISO-TP ONLY: normal addressing candidate, maximum Classical CAN DLC 8; actual DLC may be shorter. Data includes padding. No reassembly, text, DID or application-layer decoding. Original application layouts are preserved in source JSON; do not decode them at wire offsets. ";
CM_ SG_ 897 FlowPadding5 "TRANSPORT_CANDIDATE: normal-addressing ISO-TP. PSA-RE bits 8.7-8.0. ";
CM_ SG_ 897 FirstData6 "TRANSPORT_CANDIDATE: normal-addressing ISO-TP. PSA-RE bits 8.7-8.0. ";
CM_ SG_ 897 UnknownData7 "TRANSPORT_CANDIDATE: normal-addressing ISO-TP. PSA-RE bits 8.7-8.0. ";
CM_ SG_ 897 ConsecutiveData7 "TRANSPORT_CANDIDATE: normal-addressing ISO-TP. PSA-RE bits 8.7-8.0. ";
CM_ SG_ 897 SingleData7 "TRANSPORT_CANDIDATE: normal-addressing ISO-TP. PSA-RE bits 8.7-8.0. ";
CM_ SG_ 897 FlowPadding4 "TRANSPORT_CANDIDATE: normal-addressing ISO-TP. PSA-RE bits 7.7-7.0. ";
CM_ SG_ 897 FirstData5 "TRANSPORT_CANDIDATE: normal-addressing ISO-TP. PSA-RE bits 7.7-7.0. ";
CM_ SG_ 897 UnknownData6 "TRANSPORT_CANDIDATE: normal-addressing ISO-TP. PSA-RE bits 7.7-7.0. ";
CM_ SG_ 897 ConsecutiveData6 "TRANSPORT_CANDIDATE: normal-addressing ISO-TP. PSA-RE bits 7.7-7.0. ";
CM_ SG_ 897 SingleData6 "TRANSPORT_CANDIDATE: normal-addressing ISO-TP. PSA-RE bits 7.7-7.0. ";
CM_ SG_ 897 FlowPadding3 "TRANSPORT_CANDIDATE: normal-addressing ISO-TP. PSA-RE bits 6.7-6.0. ";
CM_ SG_ 897 FirstData4 "TRANSPORT_CANDIDATE: normal-addressing ISO-TP. PSA-RE bits 6.7-6.0. ";
CM_ SG_ 897 UnknownData5 "TRANSPORT_CANDIDATE: normal-addressing ISO-TP. PSA-RE bits 6.7-6.0. ";
CM_ SG_ 897 ConsecutiveData5 "TRANSPORT_CANDIDATE: normal-addressing ISO-TP. PSA-RE bits 6.7-6.0. ";
CM_ SG_ 897 SingleData5 "TRANSPORT_CANDIDATE: normal-addressing ISO-TP. PSA-RE bits 6.7-6.0. ";
CM_ SG_ 897 FlowPadding2 "TRANSPORT_CANDIDATE: normal-addressing ISO-TP. PSA-RE bits 5.7-5.0. ";
CM_ SG_ 897 FirstData3 "TRANSPORT_CANDIDATE: normal-addressing ISO-TP. PSA-RE bits 5.7-5.0. ";
CM_ SG_ 897 UnknownData4 "TRANSPORT_CANDIDATE: normal-addressing ISO-TP. PSA-RE bits 5.7-5.0. ";
CM_ SG_ 897 ConsecutiveData4 "TRANSPORT_CANDIDATE: normal-addressing ISO-TP. PSA-RE bits 5.7-5.0. ";
CM_ SG_ 897 SingleData4 "TRANSPORT_CANDIDATE: normal-addressing ISO-TP. PSA-RE bits 5.7-5.0. ";
CM_ SG_ 897 FlowPadding1 "TRANSPORT_CANDIDATE: normal-addressing ISO-TP. PSA-RE bits 4.7-4.0. ";
CM_ SG_ 897 FirstData2 "TRANSPORT_CANDIDATE: normal-addressing ISO-TP. PSA-RE bits 4.7-4.0. ";
CM_ SG_ 897 UnknownData3 "TRANSPORT_CANDIDATE: normal-addressing ISO-TP. PSA-RE bits 4.7-4.0. ";
CM_ SG_ 897 ConsecutiveData3 "TRANSPORT_CANDIDATE: normal-addressing ISO-TP. PSA-RE bits 4.7-4.0. ";
CM_ SG_ 897 SingleData3 "TRANSPORT_CANDIDATE: normal-addressing ISO-TP. PSA-RE bits 4.7-4.0. ";
CM_ SG_ 897 FirstData1 "TRANSPORT_CANDIDATE: normal-addressing ISO-TP. PSA-RE bits 3.7-3.0. ";
CM_ SG_ 897 UnknownData2 "TRANSPORT_CANDIDATE: normal-addressing ISO-TP. PSA-RE bits 3.7-3.0. ";
CM_ SG_ 897 ConsecutiveData2 "TRANSPORT_CANDIDATE: normal-addressing ISO-TP. PSA-RE bits 3.7-3.0. ";
CM_ SG_ 897 SingleData2 "TRANSPORT_CANDIDATE: normal-addressing ISO-TP. PSA-RE bits 3.7-3.0. ";
CM_ SG_ 897 SeparationTimeRaw "TRANSPORT_CANDIDATE: normal-addressing ISO-TP. PSA-RE bits 3.7-3.0. Raw STmin code; 0xF1..0xF9 are not milliseconds.";
CM_ SG_ 897 UnknownData1 "TRANSPORT_CANDIDATE: normal-addressing ISO-TP. PSA-RE bits 2.7-2.0. ";
CM_ SG_ 897 ConsecutiveData1 "TRANSPORT_CANDIDATE: normal-addressing ISO-TP. PSA-RE bits 2.7-2.0. ";
CM_ SG_ 897 SingleData1 "TRANSPORT_CANDIDATE: normal-addressing ISO-TP. PSA-RE bits 2.7-2.0. ";
CM_ SG_ 897 BlockSize "TRANSPORT_CANDIDATE: normal-addressing ISO-TP. PSA-RE bits 2.7-2.0. ";
CM_ SG_ 897 UnknownPciLow "TRANSPORT_CANDIDATE: normal-addressing ISO-TP. PSA-RE bits 1.3-1.0. ";
CM_ SG_ 897 FlowStatus "TRANSPORT_CANDIDATE: normal-addressing ISO-TP. PSA-RE bits 1.3-1.0. ";
CM_ SG_ 897 ConsecutiveSequence "TRANSPORT_CANDIDATE: normal-addressing ISO-TP. PSA-RE bits 1.3-1.0. ";
CM_ SG_ 897 FirstFrameLength "TRANSPORT_CANDIDATE: normal-addressing ISO-TP. PSA-RE bits 1.3-2.0. 12-bit declared PDU length; not a reassembled value.";
CM_ SG_ 897 SingleFrameLength "TRANSPORT_CANDIDATE: normal-addressing ISO-TP. PSA-RE bits 1.3-1.0. Declared data length; not a validity check.";
CM_ SG_ 897 IsoTpFrameType "TRANSPORT_CANDIDATE: normal-addressing ISO-TP. PSA-RE bits 1.7-1.4. PCI high nibble; normal addressing candidate.";
CM_ BO_ 901 "DATABASE_CANDIDATE: physical interpretation unverified; capture/layout evidence reported separately. INFO-DIV CAN, 125000 bit/s; CAN ID 0x385. PSA-RE title: DASHCAM_COMMAND. Dashcam playback and recording commands from the telematics/display unit: list navigation, play, accident recording requests. Source: https://github.com/prototux/PSA-RE/blob/67f7581e7622410efdbb29c7eda3b86982b9b450/buses/AEE2010.full/LS.INFO-DIV/385.yml. Source sender alternatives: BTEL,OVIP; physical TX/gateway forwarding not verified. ";
CM_ SG_ 901 IdvrListJump "DATABASE_CANDIDATE: physical interpretation unverified; capture/layout evidence reported separately. PSA-RE bits 5.7-6.0. Jump to item number x in the list Upstream default raw=65535 (not necessarily valid data).";
CM_ SG_ 901 AutoAccidentRecordingMenuRequest "DATABASE_CANDIDATE: physical interpretation unverified; capture/layout evidence reported separately. PSA-RE bits 4.1-4.0. Menu request for automatic accident recording Upstream default raw=3 (not necessarily valid data).";
CM_ SG_ 901 IdvrListLineCount "DATABASE_CANDIDATE: physical interpretation unverified; capture/layout evidence reported separately. PSA-RE bits 4.4-4.2. Number of lines that can be displayed on the display Upstream default raw=1 (not necessarily valid data).";
CM_ SG_ 901 ListFocusItem "DATABASE_CANDIDATE: physical interpretation unverified; capture/layout evidence reported separately. PSA-RE bits 4.7-4.5. Number of the item that must take focus Upstream default raw=0 (not necessarily valid data).";
CM_ SG_ 901 IdvrListValidatedItem "DATABASE_CANDIDATE: physical interpretation unverified; capture/layout evidence reported separately. PSA-RE bits 3.2-3.0. Number of the validated item Upstream default raw=0 (not necessarily valid data).";
CM_ SG_ 901 ManualAccidentRequestLive "DATABASE_CANDIDATE: physical interpretation unverified; capture/layout evidence reported separately. PSA-RE bits 3.3. Manual accident request on the live video display Upstream default raw=0 (not necessarily valid data).";
CM_ SG_ 901 ManualAccidentRequestRecord "DATABASE_CANDIDATE: physical interpretation unverified; capture/layout evidence reported separately. PSA-RE bits 3.4. Manual accident request on the recorded video display Upstream default raw=0 (not necessarily valid data).";
CM_ SG_ 901 DrivingRecordingMenuRequest "DATABASE_CANDIDATE: physical interpretation unverified; capture/layout evidence reported separately. PSA-RE bits 3.6-3.5. Menu request for driving recording Upstream default raw=3 (not necessarily valid data).";
CM_ SG_ 901 IdvrKnobSync "DATABASE_CANDIDATE: physical interpretation unverified; capture/layout evidence reported separately. PSA-RE bits 3.7. Knob synchronisation Upstream default raw=0 (not necessarily valid data).";
CM_ SG_ 901 IdvrKnobStepCounter "DATABASE_CANDIDATE: physical interpretation unverified; capture/layout evidence reported separately. PSA-RE bits 2.7-2.0. IDVR knob step counter Upstream default raw=0 (not necessarily valid data).";
CM_ SG_ 901 IdvrVideoTypeRequest "DATABASE_CANDIDATE: physical interpretation unverified; capture/layout evidence reported separately. PSA-RE bits 1.1-1.0. Request to the IDVR to send the video type (Live or ADAS) Upstream default raw=0 (not necessarily valid data).";
CM_ SG_ 901 IdvrPlaybackCommand "DATABASE_CANDIDATE: physical interpretation unverified; capture/layout evidence reported separately. PSA-RE bits 1.5-1.2. Video command while the IDVR is playing video Upstream default raw=0 (not necessarily valid data).";
CM_ SG_ 901 IdvrListOpenRequest "DATABASE_CANDIDATE: physical interpretation unverified; capture/layout evidence reported separately. PSA-RE bits 1.7-1.6. Request to the IDVR to open the list Upstream default raw=0 (not necessarily valid data).";
CM_ BO_ 907 "DATABASE_CANDIDATE: physical interpretation unverified; capture/layout evidence reported separately. INFO-DIV CAN, 125000 bit/s; CAN ID 0x38B. PSA-RE title: BSI_OTA_STATUS. Over-the-air update state for the BSI: update type, user interaction request, installation activation and vehicle update status. Source: https://github.com/prototux/PSA-RE/blob/67f7581e7622410efdbb29c7eda3b86982b9b450/buses/AEE2010.full/LS.INFO-DIV/38B.yml. Source sender alternatives: BSI; physical TX/gateway forwarding not verified. ";
CM_ SG_ 907 RawByte8 "RAW. PSA-RE bits 8.7-8.0. Unmapped/padding bits, no physical interpretation.";
CM_ SG_ 907 RawByte7 "RAW. PSA-RE bits 7.7-7.0. Unmapped/padding bits, no physical interpretation.";
CM_ SG_ 907 RawByte6 "RAW. PSA-RE bits 6.7-6.0. Unmapped/padding bits, no physical interpretation.";
CM_ SG_ 907 RawByte5 "RAW. PSA-RE bits 5.7-5.0. Unmapped/padding bits, no physical interpretation.";
CM_ SG_ 907 RawByte4 "RAW. PSA-RE bits 4.7-4.0. Unmapped/padding bits, no physical interpretation.";
CM_ SG_ 907 RawBits19_23 "RAW. PSA-RE bits 3.4-3.0. Unmapped/padding bits, no physical interpretation.";
CM_ SG_ 907 OtaUpdateUserInteraction "DATABASE_CANDIDATE: physical interpretation unverified; capture/layout evidence reported separately. PSA-RE bits 3.7-3.5. Type of user interaction during the OTA update";
CM_ SG_ 907 OtaUpdateType "DATABASE_CANDIDATE: physical interpretation unverified; capture/layout evidence reported separately. PSA-RE bits 2.1-2.0. Type of OTA update";
CM_ SG_ 907 RawBits12_13 "RAW. PSA-RE bits 2.3-2.2. Unmapped/padding bits, no physical interpretation.";
CM_ SG_ 907 OtaUpdateAuthorizationStatus "DATABASE_CANDIDATE: physical interpretation unverified; capture/layout evidence reported separately. PSA-RE bits 2.5-2.4. Vehicle OTA update authorization status";
CM_ SG_ 907 OtaInstallationModeStatus "DATABASE_CANDIDATE: physical interpretation unverified; capture/layout evidence reported separately. PSA-RE bits 2.7-2.6. Vehicle OTA installation mode activation status";
CM_ SG_ 907 RawByte1 "RAW. PSA-RE bits 1.7-1.0. Unmapped/padding bits, no physical interpretation.";
CM_ BO_ 916 "DATABASE_CANDIDATE: physical interpretation unverified; capture/layout evidence reported separately. INFO-DIV CAN, 125000 bit/s; CAN ID 0x394. PSA-RE title: HV_BATTERY_POWER_DATA. Remote-control request (2nd generation): charging data request or lock/unlock. Source: https://github.com/prototux/PSA-RE/blob/67f7581e7622410efdbb29c7eda3b86982b9b450/buses/AEE2010.full/LS.INFO-DIV/394.yml. Source sender alternatives: MDS; physical TX/gateway forwarding not verified. Observed 1 frames in info_apka.csv; DLCs [1]. ";
CM_ SG_ 916 Unused1 "DATABASE_CANDIDATE: physical interpretation unverified; capture/layout evidence reported separately. PSA-RE bits 1.3-1.0. ";
CM_ SG_ 916 RemoteSendChargeDataRequest "DATABASE_CANDIDATE: physical interpretation unverified; capture/layout evidence reported separately. PSA-RE bits 1.4. Remote request to send charging data";
CM_ SG_ 916 RemoteLockUnlockLongrangeRequest "DATABASE_CANDIDATE: physical interpretation unverified; capture/layout evidence reported separately. PSA-RE bits 1.7-1.5. Request for full or selective long-range remote lock/unlock command";
CM_ BO_ 918 "DATABASE_CANDIDATE: physical interpretation unverified; capture/layout evidence reported separately. INFO-DIV CAN, 125000 bit/s; CAN ID 0x396. PSA-RE title: BSRF_COMMAND_11. Remote diagnostics authorisation and auxiliary battery state of charge / voltage, sent by the BSI. Source: https://github.com/prototux/PSA-RE/blob/67f7581e7622410efdbb29c7eda3b86982b9b450/buses/AEE2010.full/LS.INFO-DIV/396.yml. Source sender alternatives: BSI; physical TX/gateway forwarding not verified. Observed 586 frames in info_apka.csv,info_buzeni_obc.csv,info_charging.csv,info_standby.csv,info_start_jizda.csv,infocan.csv; DLCs [6]. Unresolved alternative source layouts preserved in source JSON. ";
CM_ SG_ 918 RawByte6 "RAW. PSA-RE bits 6.7-6.0. Unmapped/padding bits, no physical interpretation.";
CM_ SG_ 918 RawByte5 "RAW. PSA-RE bits 5.7-5.0. Unmapped/padding bits, no physical interpretation.";
CM_ SG_ 918 RawByte4 "RAW. PSA-RE bits 4.7-4.0. Unmapped/padding bits, no physical interpretation.";
CM_ SG_ 918 AuxBatterySoc "DATABASE_CANDIDATE: physical interpretation unverified; capture/layout evidence reported separately. PSA-RE bits 3.7-3.0. Auxiliary (12V) battery state of charge Raw invalid=255; numeric DBC decoders may still scale it: check raw before use. Upstream default raw=0 (not necessarily valid data).";
CM_ SG_ 918 Unused2 "DATABASE_CANDIDATE: physical interpretation unverified; capture/layout evidence reported separately. PSA-RE bits 2.0. ";
CM_ SG_ 918 AuxBatteryVoltage "DATABASE_CANDIDATE: physical interpretation unverified; capture/layout evidence reported separately. PSA-RE bits 2.7-2.1. Auxiliary (12V) battery voltage Upstream default raw=127 (not necessarily valid data). Unresolved source alternatives: [{\"note\": \"Also observed with another scaling (factor 0.15)\", \"factor\": 0.15}, {\"note\": \"Also observed with another scaling (factor 5.5)\", \"factor\": 5.5}]";
CM_ SG_ 918 UnusedChargeHmiLow "DATABASE_CANDIDATE: physical interpretation unverified; capture/layout evidence reported separately. PSA-RE bits 1.1-1.0.  VEHICLE_CAPTURE_OBSERVED: info_charging.csv: first byte00 ->04 at1.940s, then0C at483.603s after160 deferred mode at480.965s; owner confirms continuous AC charging around2.5kW before delay. info_start_odlozeni.csv repeats00 ->04 ->0C. Driving capture uses01/03, yielding HMI0; preconditioning/standby captures yield0. AEE2010.full/HS.HS3/396.yml defines exactly1.4-1.2 as CHARGING_HMI_STATE. Other HS3 fields/DLC are not imported. Scope: Vehicle-specific reported-HMI candidate supported for observed0/1/3, not a physical-current measurement. States2/4 follow the corroborating HS3 source enum and are unobserved;5..7 remain unknown. Older low-SOC charging-named captures report0, so stale/default BSI data can disagree with physical charging until refresh. Preserve the original INFO definition and unused bits.";
CM_ SG_ 918 ChargingHmiState "DATABASE_CANDIDATE: physical interpretation unverified; capture/layout evidence reported separately. PSA-RE bits 1.4-1.2. BSI reported charging HMI state. Source-reserved INFO span corroborated by two start/delay captures and driving contrast, consistent with HS3/396 CHARGING_HMI_STATE; not proof of current physical power flow or independent cable sensing. VEHICLE_CAPTURE_OBSERVED: info_charging.csv: first byte00 ->04 at1.940s, then0C at483.603s after160 deferred mode at480.965s; owner confirms continuous AC charging around2.5kW before delay. info_start_odlozeni.csv repeats00 ->04 ->0C. Driving capture uses01/03, yielding HMI0; preconditioning/standby captures yield0. AEE2010.full/HS.HS3/396.yml defines exactly1.4-1.2 as CHARGING_HMI_STATE. Other HS3 fields/DLC are not imported. Scope: Vehicle-specific reported-HMI candidate supported for observed0/1/3, not a physical-current measurement. States2/4 follow the corroborating HS3 source enum and are unobserved;5..7 remain unknown. Older low-SOC charging-named captures report0, so stale/default BSI data can disagree with physical charging until refresh. Preserve the original INFO definition and unused bits.";
CM_ SG_ 918 Unused1 "DATABASE_CANDIDATE: physical interpretation unverified; capture/layout evidence reported separately. PSA-RE bits 1.5.  VEHICLE_CAPTURE_OBSERVED: info_charging.csv: first byte00 ->04 at1.940s, then0C at483.603s after160 deferred mode at480.965s; owner confirms continuous AC charging around2.5kW before delay. info_start_odlozeni.csv repeats00 ->04 ->0C. Driving capture uses01/03, yielding HMI0; preconditioning/standby captures yield0. AEE2010.full/HS.HS3/396.yml defines exactly1.4-1.2 as CHARGING_HMI_STATE. Other HS3 fields/DLC are not imported. Scope: Vehicle-specific reported-HMI candidate supported for observed0/1/3, not a physical-current measurement. States2/4 follow the corroborating HS3 source enum and are unobserved;5..7 remain unknown. Older low-SOC charging-named captures report0, so stale/default BSI data can disagree with physical charging until refresh. Preserve the original INFO definition and unused bits.";
CM_ SG_ 918 RemoteDiagnosisAuthorization "DATABASE_CANDIDATE: physical interpretation unverified; capture/layout evidence reported separately. PSA-RE bits 1.7-1.6. Remote diagnosis (TLDIAG) authorization Upstream default raw=0 (not necessarily valid data).";
CM_ BO_ 922 "DATABASE_CANDIDATE: physical interpretation unverified; capture/layout evidence reported separately. INFO-DIV CAN, 125000 bit/s; CAN ID 0x39A. PSA-RE title: ZEV_TRIP_INFO_2. Average electric-mode consumption history (six periods) and estimated charge rate. Source: https://github.com/prototux/PSA-RE/blob/67f7581e7622410efdbb29c7eda3b86982b9b450/buses/AEE2010.full/LS.INFO-DIV/39A.yml. Source sender alternatives: BSI; physical TX/gateway forwarding not verified. Observed 589 frames in info_apka.csv,info_buzeni_obc.csv,info_charging.csv,info_standby.csv,info_start_jizda.csv,infocan.csv; DLCs [8]. Unresolved alternative source layouts preserved in source JSON. ";
CM_ SG_ 922 ZevRangeChargingRate "DATABASE_CANDIDATE: physical interpretation unverified; capture/layout evidence reported separately. PSA-RE bits 8.7-8.0. Electric charging rate, expressed as ZEV range gained Upstream default raw=255 (not necessarily valid data).";
CM_ SG_ 922 Unused1 "DATABASE_CANDIDATE: physical interpretation unverified; capture/layout evidence reported separately. PSA-RE bits 7.1-7.0. ";
CM_ SG_ 922 TripElectricConsumption "DATABASE_CANDIDATE: physical interpretation unverified; capture/layout evidence reported separately. PSA-RE bits 6.2-7.2. Trip electric power consumption Raw invalid=511; numeric DBC decoders may still scale it: check raw before use. Upstream default raw=511 (not necessarily valid data).";
CM_ SG_ 922 TripAverageFuelConsumption "DATABASE_CANDIDATE: physical interpretation unverified; capture/layout evidence reported separately. PSA-RE bits 5.3-6.3. Trip average fuel consumption Raw invalid=511; numeric DBC decoders may still scale it: check raw before use. Upstream default raw=511 (not necessarily valid data).";
CM_ SG_ 922 ZevAverageConsumptionPeriod6 "DATABASE_CANDIDATE: physical interpretation unverified; capture/layout evidence reported separately. PSA-RE bits 4.1-5.4. Average electric power consumption for time period 6 Raw invalid=63; numeric DBC decoders may still scale it: check raw before use. Upstream default raw=63 (not necessarily valid data).";
CM_ SG_ 922 ZevAverageConsumptionPeriod5 "DATABASE_CANDIDATE: physical interpretation unverified; capture/layout evidence reported separately. PSA-RE bits 4.7-4.2. Average electric power consumption for time period 5 Raw invalid=63; numeric DBC decoders may still scale it: check raw before use. Upstream default raw=63 (not necessarily valid data).";
CM_ SG_ 922 ZevAverageConsumptionPeriod4 "DATABASE_CANDIDATE: physical interpretation unverified; capture/layout evidence reported separately. PSA-RE bits 3.5-3.0. Average electric power consumption for time period 4 Raw invalid=63; numeric DBC decoders may still scale it: check raw before use. Upstream default raw=63 (not necessarily valid data).";
CM_ SG_ 922 ZevAverageConsumptionPeriod3 "DATABASE_CANDIDATE: physical interpretation unverified; capture/layout evidence reported separately. PSA-RE bits 2.3-3.6. Average electric power consumption for time period 3 Raw invalid=63; numeric DBC decoders may still scale it: check raw before use. Upstream default raw=63 (not necessarily valid data).";
CM_ SG_ 922 ZevAverageConsumptionPeriod2 "DATABASE_CANDIDATE: physical interpretation unverified; capture/layout evidence reported separately. PSA-RE bits 1.1-2.4. Average electric power consumption for time period 2 Raw invalid=63; numeric DBC decoders may still scale it: check raw before use. Upstream default raw=63 (not necessarily valid data).";
CM_ SG_ 922 ZevAverageConsumptionPeriod1 "DATABASE_CANDIDATE: physical interpretation unverified; capture/layout evidence reported separately. PSA-RE bits 1.7-1.2. Average electric power consumption for time period 1 Raw invalid=63; numeric DBC decoders may still scale it: check raw before use. Upstream default raw=63 (not necessarily valid data).";
CM_ BO_ 923 "DATABASE_CANDIDATE: physical interpretation unverified; capture/layout evidence reported separately. INFO-DIV CAN, 125000 bit/s; CAN ID 0x39B. PSA-RE title: CLOCK_UPDATE_REQUEST. Clock update request: year, month, day, hour, minute and time-format mode. Source: https://github.com/prototux/PSA-RE/blob/67f7581e7622410efdbb29c7eda3b86982b9b450/buses/AEE2010.full/LS.INFO-DIV/39B.yml. Source sender alternatives: ICSV,BTEL,OVIP,CMB,EMF,MATT; physical TX/gateway forwarding not verified. ";
CM_ SG_ 923 TimeMinute "DATABASE_CANDIDATE: physical interpretation unverified; capture/layout evidence reported separately. PSA-RE bits 5.5-5.0. Clock minute Raw invalid=63; numeric DBC decoders may still scale it: check raw before use. Upstream default raw=62 (not necessarily valid data).";
CM_ SG_ 923 Unused4 "DATABASE_CANDIDATE: physical interpretation unverified; capture/layout evidence reported separately. PSA-RE bits 5.7-5.6. ";
CM_ SG_ 923 TimeHour "DATABASE_CANDIDATE: physical interpretation unverified; capture/layout evidence reported separately. PSA-RE bits 4.4-4.0. Clock hour Raw invalid=31; numeric DBC decoders may still scale it: check raw before use. Upstream default raw=30 (not necessarily valid data).";
CM_ SG_ 923 Unused3 "DATABASE_CANDIDATE: physical interpretation unverified; capture/layout evidence reported separately. PSA-RE bits 4.7-4.5. ";
CM_ SG_ 923 ClockDay "DATABASE_CANDIDATE: physical interpretation unverified; capture/layout evidence reported separately. PSA-RE bits 3.5-3.0. Clock day value Raw invalid=63; numeric DBC decoders may still scale it: check raw before use. Upstream default raw=62 (not necessarily valid data).";
CM_ SG_ 923 Unused2 "DATABASE_CANDIDATE: physical interpretation unverified; capture/layout evidence reported separately. PSA-RE bits 3.7-3.6. ";
CM_ SG_ 923 ClockMonth "DATABASE_CANDIDATE: physical interpretation unverified; capture/layout evidence reported separately. PSA-RE bits 2.3-2.0. Clock month value Upstream default raw=14 (not necessarily valid data).";
CM_ SG_ 923 Unused1 "DATABASE_CANDIDATE: physical interpretation unverified; capture/layout evidence reported separately. PSA-RE bits 2.7-2.4. ";
CM_ SG_ 923 ClockYear "DATABASE_CANDIDATE: physical interpretation unverified; capture/layout evidence reported separately. PSA-RE bits 1.6-1.0. Clock year value Raw invalid=127; numeric DBC decoders may still scale it: check raw before use. Upstream default raw=126 (not necessarily valid data).";
CM_ SG_ 923 ConfigDisplayTime "DATABASE_CANDIDATE: physical interpretation unverified; capture/layout evidence reported separately. PSA-RE bits 1.7. Time display format configured by the customer (12h/24h) Upstream default raw=1 (not necessarily valid data).";
CM_ BO_ 924 "DATABASE_CANDIDATE: physical interpretation unverified; capture/layout evidence reported separately. INFO-DIV CAN, 125000 bit/s; CAN ID 0x39C. PSA-RE title: AUDIO_EXPORT_ACK. Acknowledgement of a multi-frame audio export status message. Source: https://github.com/prototux/PSA-RE/blob/67f7581e7622410efdbb29c7eda3b86982b9b450/buses/AEE2010.full/LS.INFO-DIV/39C.yml. Source sender alternatives: ICSV,MATT; physical TX/gateway forwarding not verified. ";
CM_ SG_ 924 SegmentationAckStream "DATABASE_CANDIDATE: physical interpretation unverified; capture/layout evidence reported separately. PSA-RE bits 1.7-1.0. Segmentation acknowledgment stream";
CM_ BO_ 927 "DATABASE_CANDIDATE: physical interpretation unverified; capture/layout evidence reported separately. INFO-DIV CAN, 125000 bit/s; CAN ID 0x39F. PSA-RE title: NAV_DATABASE_STATUS_ACK_TEL. Acknowledgement of a multi-frame navigation database status message (TEL). Source: https://github.com/prototux/PSA-RE/blob/67f7581e7622410efdbb29c7eda3b86982b9b450/buses/AEE2010.full/LS.INFO-DIV/39F.yml. Source sender alternatives: EMF,ICSV; physical TX/gateway forwarding not verified. ";
CM_ SG_ 927 SegmentationAckStream "DATABASE_CANDIDATE: physical interpretation unverified; capture/layout evidence reported separately. PSA-RE bits 1.7-1.0. Segmentation acknowledgment stream";
CM_ BO_ 928 "DATABASE_CANDIDATE: physical interpretation unverified; capture/layout evidence reported separately. INFO-DIV CAN, 125000 bit/s; CAN ID 0x3A0. PSA-RE title: VEHICLE_PARAMETER_REQUEST. Vehicle parameter request from the infotainment nodes. Source: https://github.com/prototux/PSA-RE/blob/67f7581e7622410efdbb29c7eda3b86982b9b450/buses/AEE2010.full/LS.INFO-DIV/3A0.yml. Source sender alternatives: ICSV,BTEL,OVIP; physical TX/gateway forwarding not verified. WIRE ISO-TP ONLY: normal addressing candidate, maximum Classical CAN DLC 8; actual DLC may be shorter. Data includes padding. No reassembly, text, DID or application-layer decoding. Original application layouts are preserved in source JSON; do not decode them at wire offsets. ";
CM_ SG_ 928 FlowPadding5 "TRANSPORT_CANDIDATE: normal-addressing ISO-TP. PSA-RE bits 8.7-8.0. ";
CM_ SG_ 928 FirstData6 "TRANSPORT_CANDIDATE: normal-addressing ISO-TP. PSA-RE bits 8.7-8.0. ";
CM_ SG_ 928 UnknownData7 "TRANSPORT_CANDIDATE: normal-addressing ISO-TP. PSA-RE bits 8.7-8.0. ";
CM_ SG_ 928 ConsecutiveData7 "TRANSPORT_CANDIDATE: normal-addressing ISO-TP. PSA-RE bits 8.7-8.0. ";
CM_ SG_ 928 SingleData7 "TRANSPORT_CANDIDATE: normal-addressing ISO-TP. PSA-RE bits 8.7-8.0. ";
CM_ SG_ 928 FlowPadding4 "TRANSPORT_CANDIDATE: normal-addressing ISO-TP. PSA-RE bits 7.7-7.0. ";
CM_ SG_ 928 FirstData5 "TRANSPORT_CANDIDATE: normal-addressing ISO-TP. PSA-RE bits 7.7-7.0. ";
CM_ SG_ 928 UnknownData6 "TRANSPORT_CANDIDATE: normal-addressing ISO-TP. PSA-RE bits 7.7-7.0. ";
CM_ SG_ 928 ConsecutiveData6 "TRANSPORT_CANDIDATE: normal-addressing ISO-TP. PSA-RE bits 7.7-7.0. ";
CM_ SG_ 928 SingleData6 "TRANSPORT_CANDIDATE: normal-addressing ISO-TP. PSA-RE bits 7.7-7.0. ";
CM_ SG_ 928 FlowPadding3 "TRANSPORT_CANDIDATE: normal-addressing ISO-TP. PSA-RE bits 6.7-6.0. ";
CM_ SG_ 928 FirstData4 "TRANSPORT_CANDIDATE: normal-addressing ISO-TP. PSA-RE bits 6.7-6.0. ";
CM_ SG_ 928 UnknownData5 "TRANSPORT_CANDIDATE: normal-addressing ISO-TP. PSA-RE bits 6.7-6.0. ";
CM_ SG_ 928 ConsecutiveData5 "TRANSPORT_CANDIDATE: normal-addressing ISO-TP. PSA-RE bits 6.7-6.0. ";
CM_ SG_ 928 SingleData5 "TRANSPORT_CANDIDATE: normal-addressing ISO-TP. PSA-RE bits 6.7-6.0. ";
CM_ SG_ 928 FlowPadding2 "TRANSPORT_CANDIDATE: normal-addressing ISO-TP. PSA-RE bits 5.7-5.0. ";
CM_ SG_ 928 FirstData3 "TRANSPORT_CANDIDATE: normal-addressing ISO-TP. PSA-RE bits 5.7-5.0. ";
CM_ SG_ 928 UnknownData4 "TRANSPORT_CANDIDATE: normal-addressing ISO-TP. PSA-RE bits 5.7-5.0. ";
CM_ SG_ 928 ConsecutiveData4 "TRANSPORT_CANDIDATE: normal-addressing ISO-TP. PSA-RE bits 5.7-5.0. ";
CM_ SG_ 928 SingleData4 "TRANSPORT_CANDIDATE: normal-addressing ISO-TP. PSA-RE bits 5.7-5.0. ";
CM_ SG_ 928 FlowPadding1 "TRANSPORT_CANDIDATE: normal-addressing ISO-TP. PSA-RE bits 4.7-4.0. ";
CM_ SG_ 928 FirstData2 "TRANSPORT_CANDIDATE: normal-addressing ISO-TP. PSA-RE bits 4.7-4.0. ";
CM_ SG_ 928 UnknownData3 "TRANSPORT_CANDIDATE: normal-addressing ISO-TP. PSA-RE bits 4.7-4.0. ";
CM_ SG_ 928 ConsecutiveData3 "TRANSPORT_CANDIDATE: normal-addressing ISO-TP. PSA-RE bits 4.7-4.0. ";
CM_ SG_ 928 SingleData3 "TRANSPORT_CANDIDATE: normal-addressing ISO-TP. PSA-RE bits 4.7-4.0. ";
CM_ SG_ 928 FirstData1 "TRANSPORT_CANDIDATE: normal-addressing ISO-TP. PSA-RE bits 3.7-3.0. ";
CM_ SG_ 928 UnknownData2 "TRANSPORT_CANDIDATE: normal-addressing ISO-TP. PSA-RE bits 3.7-3.0. ";
CM_ SG_ 928 ConsecutiveData2 "TRANSPORT_CANDIDATE: normal-addressing ISO-TP. PSA-RE bits 3.7-3.0. ";
CM_ SG_ 928 SingleData2 "TRANSPORT_CANDIDATE: normal-addressing ISO-TP. PSA-RE bits 3.7-3.0. ";
CM_ SG_ 928 SeparationTimeRaw "TRANSPORT_CANDIDATE: normal-addressing ISO-TP. PSA-RE bits 3.7-3.0. Raw STmin code; 0xF1..0xF9 are not milliseconds.";
CM_ SG_ 928 UnknownData1 "TRANSPORT_CANDIDATE: normal-addressing ISO-TP. PSA-RE bits 2.7-2.0. ";
CM_ SG_ 928 ConsecutiveData1 "TRANSPORT_CANDIDATE: normal-addressing ISO-TP. PSA-RE bits 2.7-2.0. ";
CM_ SG_ 928 SingleData1 "TRANSPORT_CANDIDATE: normal-addressing ISO-TP. PSA-RE bits 2.7-2.0. ";
CM_ SG_ 928 BlockSize "TRANSPORT_CANDIDATE: normal-addressing ISO-TP. PSA-RE bits 2.7-2.0. ";
CM_ SG_ 928 UnknownPciLow "TRANSPORT_CANDIDATE: normal-addressing ISO-TP. PSA-RE bits 1.3-1.0. ";
CM_ SG_ 928 FlowStatus "TRANSPORT_CANDIDATE: normal-addressing ISO-TP. PSA-RE bits 1.3-1.0. ";
CM_ SG_ 928 ConsecutiveSequence "TRANSPORT_CANDIDATE: normal-addressing ISO-TP. PSA-RE bits 1.3-1.0. ";
CM_ SG_ 928 FirstFrameLength "TRANSPORT_CANDIDATE: normal-addressing ISO-TP. PSA-RE bits 1.3-2.0. 12-bit declared PDU length; not a reassembled value.";
CM_ SG_ 928 SingleFrameLength "TRANSPORT_CANDIDATE: normal-addressing ISO-TP. PSA-RE bits 1.3-1.0. Declared data length; not a validity check.";
CM_ SG_ 928 IsoTpFrameType "TRANSPORT_CANDIDATE: normal-addressing ISO-TP. PSA-RE bits 1.7-1.4. PCI high nibble; normal addressing candidate.";
CM_ BO_ 929 "DATABASE_CANDIDATE: physical interpretation unverified; capture/layout evidence reported separately. INFO-DIV CAN, 125000 bit/s; CAN ID 0x3A1. PSA-RE title: NAV_GUIDANCE_COMPASS_DISPLAY. Turn-by-turn compass rose display data for the navigation guidance arrow: distance, pictogram and angle segments. Source: https://github.com/prototux/PSA-RE/blob/67f7581e7622410efdbb29c7eda3b86982b9b450/buses/AEE2010.full/LS.INFO-DIV/3A1.yml. Source sender alternatives: ICSV,BTEL,OVIP; physical TX/gateway forwarding not verified. ";
CM_ SG_ 929 SetpointPictogramNumber "DATABASE_CANDIDATE: physical interpretation unverified; capture/layout evidence reported separately. PSA-RE bits 7.5-7.0. Number of the setpoint pictogram to display Upstream default raw=0 (not necessarily valid data).";
CM_ SG_ 929 Unused3 "DATABASE_CANDIDATE: physical interpretation unverified; capture/layout evidence reported separately. PSA-RE bits 7.7-7.6. ";
CM_ SG_ 929 Unused2 "DATABASE_CANDIDATE: physical interpretation unverified; capture/layout evidence reported separately. PSA-RE bits 6.0. ";
CM_ SG_ 929 RoundaboutMaskSegment "DATABASE_CANDIDATE: physical interpretation unverified; capture/layout evidence reported separately. PSA-RE bits 6.1. Roundabout mask segment Upstream default raw=0 (not necessarily valid data).";
CM_ SG_ 929 NavSegmentAngle15 "DATABASE_CANDIDATE: physical interpretation unverified; capture/layout evidence reported separately. PSA-RE bits 6.3-6.2. Navigation segment 15 Upstream default raw=0 (not necessarily valid data).";
CM_ SG_ 929 NavSegmentAngle14 "DATABASE_CANDIDATE: physical interpretation unverified; capture/layout evidence reported separately. PSA-RE bits 6.5-6.4. Navigation segment 14 Upstream default raw=0 (not necessarily valid data).";
CM_ SG_ 929 NavSegmentAngle13 "DATABASE_CANDIDATE: physical interpretation unverified; capture/layout evidence reported separately. PSA-RE bits 6.7-6.6. Navigation segment 13 Upstream default raw=0 (not necessarily valid data).";
CM_ SG_ 929 NavSegmentAngle12 "DATABASE_CANDIDATE: physical interpretation unverified; capture/layout evidence reported separately. PSA-RE bits 5.1-5.0. Navigation segment 12 Upstream default raw=0 (not necessarily valid data).";
CM_ SG_ 929 NavSegmentAngle11 "DATABASE_CANDIDATE: physical interpretation unverified; capture/layout evidence reported separately. PSA-RE bits 5.3-5.2. Navigation segment 11 Upstream default raw=0 (not necessarily valid data).";
CM_ SG_ 929 NavSegmentAngle10 "DATABASE_CANDIDATE: physical interpretation unverified; capture/layout evidence reported separately. PSA-RE bits 5.5-5.4. Navigation segment 10 Upstream default raw=0 (not necessarily valid data).";
CM_ SG_ 929 NavSegmentAngle9 "DATABASE_CANDIDATE: physical interpretation unverified; capture/layout evidence reported separately. PSA-RE bits 5.7-5.6. Navigation segment 9 Upstream default raw=0 (not necessarily valid data).";
CM_ SG_ 929 NavSegmentAngle8 "DATABASE_CANDIDATE: physical interpretation unverified; capture/layout evidence reported separately. PSA-RE bits 4.1-4.0. Navigation segment 8 Upstream default raw=0 (not necessarily valid data).";
CM_ SG_ 929 NavSegmentAngle7 "DATABASE_CANDIDATE: physical interpretation unverified; capture/layout evidence reported separately. PSA-RE bits 4.3-4.2. Navigation segment 7 Upstream default raw=0 (not necessarily valid data).";
CM_ SG_ 929 NavSegmentAngle6 "DATABASE_CANDIDATE: physical interpretation unverified; capture/layout evidence reported separately. PSA-RE bits 4.5-4.4. Navigation segment 6 Upstream default raw=0 (not necessarily valid data).";
CM_ SG_ 929 NavSegmentAngle5 "DATABASE_CANDIDATE: physical interpretation unverified; capture/layout evidence reported separately. PSA-RE bits 4.7-4.6. Navigation segment 5 Upstream default raw=0 (not necessarily valid data).";
CM_ SG_ 929 NavSegmentAngle4 "DATABASE_CANDIDATE: physical interpretation unverified; capture/layout evidence reported separately. PSA-RE bits 3.1-3.0. Navigation segment 4 Upstream default raw=0 (not necessarily valid data).";
CM_ SG_ 929 NavSegmentAngle3 "DATABASE_CANDIDATE: physical interpretation unverified; capture/layout evidence reported separately. PSA-RE bits 3.3-3.2. Navigation segment 3 Upstream default raw=0 (not necessarily valid data).";
CM_ SG_ 929 NavSegmentAngle2 "DATABASE_CANDIDATE: physical interpretation unverified; capture/layout evidence reported separately. PSA-RE bits 3.5-3.4. Navigation segment 2 Upstream default raw=0 (not necessarily valid data).";
CM_ SG_ 929 NavSegmentAngle1 "DATABASE_CANDIDATE: physical interpretation unverified; capture/layout evidence reported separately. PSA-RE bits 3.7-3.6. Navigation segment 1 Upstream default raw=0 (not necessarily valid data).";
CM_ SG_ 929 NavSegmentDecrement8 "DATABASE_CANDIDATE: physical interpretation unverified; capture/layout evidence reported separately. PSA-RE bits 2.0. Navigation segment decrement step 8 Upstream default raw=0 (not necessarily valid data).";
CM_ SG_ 929 NavSegmentDecrement7 "DATABASE_CANDIDATE: physical interpretation unverified; capture/layout evidence reported separately. PSA-RE bits 2.1. Navigation segment decrement step 7 Upstream default raw=0 (not necessarily valid data).";
CM_ SG_ 929 NavSegmentDecrement6 "DATABASE_CANDIDATE: physical interpretation unverified; capture/layout evidence reported separately. PSA-RE bits 2.2. Navigation segment decrement step 6 Upstream default raw=0 (not necessarily valid data).";
CM_ SG_ 929 NavSegmentDecrement5 "DATABASE_CANDIDATE: physical interpretation unverified; capture/layout evidence reported separately. PSA-RE bits 2.3. Navigation segment decrement step 5 Upstream default raw=0 (not necessarily valid data).";
CM_ SG_ 929 NavSegmentDecrement4 "DATABASE_CANDIDATE: physical interpretation unverified; capture/layout evidence reported separately. PSA-RE bits 2.4. Navigation segment decrement step 4 Upstream default raw=0 (not necessarily valid data).";
CM_ SG_ 929 NavSegmentDecrement3 "DATABASE_CANDIDATE: physical interpretation unverified; capture/layout evidence reported separately. PSA-RE bits 2.5. Navigation segment decrement step 3 Upstream default raw=0 (not necessarily valid data).";
CM_ SG_ 929 NavSegmentDecrement2 "DATABASE_CANDIDATE: physical interpretation unverified; capture/layout evidence reported separately. PSA-RE bits 2.6. Navigation segment decrement step 2 Upstream default raw=0 (not necessarily valid data).";
CM_ SG_ 929 NavSegmentDecrement1 "DATABASE_CANDIDATE: physical interpretation unverified; capture/layout evidence reported separately. PSA-RE bits 2.7. Navigation segment decrement step 1 Upstream default raw=0 (not necessarily valid data).";
CM_ SG_ 929 DistanceToSetpoint "DATABASE_CANDIDATE: physical interpretation unverified; capture/layout evidence reported separately. PSA-RE bits 1.4-1.0. Distance to the setpoint Upstream default raw=26 (not necessarily valid data).";
CM_ SG_ 929 SetpointEnd "DATABASE_CANDIDATE: physical interpretation unverified; capture/layout evidence reported separately. PSA-RE bits 1.5. End of setpoint Upstream default raw=0 (not necessarily valid data).";
CM_ SG_ 929 Unused1 "DATABASE_CANDIDATE: physical interpretation unverified; capture/layout evidence reported separately. PSA-RE bits 1.7-1.6. ";
CM_ BO_ 931 "DATABASE_CANDIDATE: physical interpretation unverified; capture/layout evidence reported separately. INFO-DIV CAN, 125000 bit/s; CAN ID 0x3A3. PSA-RE title: HMI_DRIVE_MODE_INFO. Human-machine interface data: availability of the selectable driving modes (AWD, comfort, eco, sport, hybrid, ZEV). Source: https://github.com/prototux/PSA-RE/blob/67f7581e7622410efdbb29c7eda3b86982b9b450/buses/AEE2010.full/LS.INFO-DIV/3A3.yml. Source sender alternatives: BSI; physical TX/gateway forwarding not verified. Observed 587 frames in info_apka.csv,info_buzeni_obc.csv,info_charging.csv,info_standby.csv,info_start_jizda.csv,infocan.csv; DLCs [7]. ";
CM_ SG_ 931 RawByte7 "RAW. PSA-RE bits 7.7-7.0. Unmapped/padding bits, no physical interpretation.";
CM_ SG_ 931 NormalModeCapability "DATABASE_CANDIDATE: physical interpretation unverified; capture/layout evidence reported separately. PSA-RE bits 6.0. Vehicle capability to run Normal mode Upstream default raw=0 (not necessarily valid data).";
CM_ SG_ 931 EcoPlusModeCapability "DATABASE_CANDIDATE: physical interpretation unverified; capture/layout evidence reported separately. PSA-RE bits 6.1. Vehicle capability to run Eco+ mode Upstream default raw=0 (not necessarily valid data).";
CM_ SG_ 931 EcoModeCapability "DATABASE_CANDIDATE: physical interpretation unverified; capture/layout evidence reported separately. PSA-RE bits 6.2. Vehicle capability to run Eco mode Upstream default raw=0 (not necessarily valid data).";
CM_ SG_ 931 ComfortModeCapability "DATABASE_CANDIDATE: physical interpretation unverified; capture/layout evidence reported separately. PSA-RE bits 6.3. Vehicle capability to run Comfort mode Upstream default raw=0 (not necessarily valid data).";
CM_ SG_ 931 SportModeCapability "DATABASE_CANDIDATE: physical interpretation unverified; capture/layout evidence reported separately. PSA-RE bits 6.4. Vehicle capability to run Sport mode Upstream default raw=0 (not necessarily valid data).";
CM_ SG_ 931 AwdModeCapability "DATABASE_CANDIDATE: physical interpretation unverified; capture/layout evidence reported separately. PSA-RE bits 6.5. Vehicle capability to run AWD mode Upstream default raw=0 (not necessarily valid data).";
CM_ SG_ 931 HybridEcoModeCapability "DATABASE_CANDIDATE: physical interpretation unverified; capture/layout evidence reported separately. PSA-RE bits 6.6. Vehicle capability to run Hybrid Eco mode Upstream default raw=0 (not necessarily valid data).";
CM_ SG_ 931 ZevEcoModeCapability "DATABASE_CANDIDATE: physical interpretation unverified; capture/layout evidence reported separately. PSA-RE bits 6.7. Vehicle capability to run ZEV Eco mode Upstream default raw=0 (not necessarily valid data).";
CM_ SG_ 931 ZevModeCapability "DATABASE_CANDIDATE: physical interpretation unverified; capture/layout evidence reported separately. PSA-RE bits 5.0. Vehicle capability to run ZEV mode Upstream default raw=0 (not necessarily valid data).";
CM_ SG_ 931 HybridVehicleModeSelector_ba5418 "DATABASE_CANDIDATE: physical interpretation unverified; capture/layout evidence reported separately. PSA-RE bits 5.4-5.1. Hybrid vehicle mode selector configuration Upstream default raw=0 (not necessarily valid data).";
CM_ SG_ 931 IlvSpeedPanelValueType "DATABASE_CANDIDATE: physical interpretation unverified; capture/layout evidence reported separately. PSA-RE bits 5.6-5.5. Type of value shown on the speed-limit sign (ILV) Upstream default raw=0 (not necessarily valid data).";
CM_ SG_ 931 IlvConditionalOverspeedFlag "DATABASE_CANDIDATE: physical interpretation unverified; capture/layout evidence reported separately. PSA-RE bits 5.7. Overspeed flag relative to the ILV conditional speed Upstream default raw=0 (not necessarily valid data).";
CM_ SG_ 931 IlvConditionalSpeedToDisplay "DATABASE_CANDIDATE: physical interpretation unverified; capture/layout evidence reported separately. PSA-RE bits 4.7-4.0. Arbitrated conditional speed to propose to the driver Raw invalid=255; numeric DBC decoders may still scale it: check raw before use. Upstream default raw=255 (not necessarily valid data).";
CM_ SG_ 931 IlvImplicitSignType "DATABASE_CANDIDATE: physical interpretation unverified; capture/layout evidence reported separately. PSA-RE bits 3.3-3.0. Type of implicit speed-limit sign (ILV) Upstream default raw=15 (not necessarily valid data).";
CM_ SG_ 931 IlvConditionalSignType "DATABASE_CANDIDATE: physical interpretation unverified; capture/layout evidence reported separately. PSA-RE bits 3.7-3.4. Type of conditional speed-limit sign (ILV) Upstream default raw=15 (not necessarily valid data).";
CM_ SG_ 931 IlvLeftSlotNoSpeedPanel "DATABASE_CANDIDATE: physical interpretation unverified; capture/layout evidence reported separately. PSA-RE bits 2.7-2.0. Indicates a non-speed sign in the left-hand display slot Raw invalid=255; numeric DBC decoders may still scale it: check raw before use.";
CM_ SG_ 931 IlvRightSlotNoSpeedPanel "DATABASE_CANDIDATE: physical interpretation unverified; capture/layout evidence reported separately. PSA-RE bits 1.7-1.0. Indicates a non-speed sign in the right-hand display slot Raw invalid=255; numeric DBC decoders may still scale it: check raw before use.";
CM_ BO_ 932 "DATABASE_CANDIDATE: physical interpretation unverified; capture/layout evidence reported separately. INFO-DIV CAN, 125000 bit/s; CAN ID 0x3A4. PSA-RE title: DASHCAM_BUTTON_REQUESTS. Dashcam recording button press events, relayed by the telematics unit. Source: https://github.com/prototux/PSA-RE/blob/67f7581e7622410efdbb29c7eda3b86982b9b450/buses/AEE2010.full/LS.INFO-DIV/3A4.yml. Source sender alternatives: BTEL,OVIP; physical TX/gateway forwarding not verified. ";
CM_ SG_ 932 Unused1 "DATABASE_CANDIDATE: physical interpretation unverified; capture/layout evidence reported separately. PSA-RE bits 1.5-1.0. ";
CM_ SG_ 932 ArcPushInput "DATABASE_CANDIDATE: physical interpretation unverified; capture/layout evidence reported separately. PSA-RE bits 1.6. Front collision warning button input Upstream default raw=0 (not necessarily valid data).";
CM_ SG_ 932 SideTrajectoryButtonStatus "DATABASE_CANDIDATE: physical interpretation unverified; capture/layout evidence reported separately. PSA-RE bits 1.7. Lane departure warning push-button input Upstream default raw=0 (not necessarily valid data).";
VAL_ 808 FlowStatus 0 "ContinueToSend" 1 "Wait" 2 "Overflow" ;
VAL_ 808 IsoTpFrameType 0 "SingleFrame" 1 "FirstFrame" 2 "ConsecutiveFrame" 3 "FlowControl" ;
VAL_ 809 EnergyRecoveryButtonPressed 0 "Switch off" 1 "Pressed" ;
VAL_ 809 AvasButtonPressed 0 "Switch off" 1 "Pressed" ;
VAL_ 809 OutsideAirQualityBadLevel 0 "Unavailable" 1 "Bad (sensitive people)" 2 "Bad / unhealthy" 3 "Very unhealthy" 4 "Hazardous" ;
VAL_ 809 NightVisionToggleRequest 0 "False" 1 "True" ;
VAL_ 809 AutomaticParkingSideRequest 0 "Left" 1 "Right" ;
VAL_ 809 AutomaticParkingActivatio_012211 0 "No demand" 1 "Demand" ;
VAL_ 809 CabinAirFilterResetRequest 0 "Value 1" 1 "Value 2" ;
VAL_ 809 CabinAirPurifierModeRequest 0 "Off" 1 "Automatic" 2 "Low" 3 "Medium" 4 "High" 7 "Unavailable" ;
VAL_ 809 OutsideAirQualityLevel 0 "Good" 1 "Moderate" 2 "Unhealthy" 3 "Unavailable" ;
VAL_ 809 AsrInhibitRequest 0 "Connection" 1 "Disconnection" ;
VAL_ 809 ConsumptionHistoryZoomLevel 0 "5 min" 1 "10 min" 2 "30 min" 3 "60 min" ;
VAL_ 809 ConsumptionHistoryResetRequest 0 "Not pressed" 1 "Pressed" ;
VAL_ 809 DynamicModeTouchSelection 0 "Normal" 1 "Sport" 2 "Comfort" 3 "Eco" 4 "ZEV" 5 "EAWD" 6 "Hybrid" 7 "ZEV Eco mode" 8 "Hybrid Eco" 9 "Eco plus" ;
VAL_ 809 EcoachTripResetRequest 0 "No request" 1 "Requested" ;
VAL_ 809 MassageActivationCommand 0 "No request" 1 "Massage request" ;
VAL_ 809 MassageIntensityCommand 0 "Weak intensity" 1 "Normal intensity" 2 "High intensity" 3 "FREE" ;
VAL_ 809 MassageTypeCommand 0 "No command" 1 "Type 1" 2 "Type 2" 3 "Type 3" 4 "Type 4" 5 "Type 5" 6 "Type 6" 7 "Type 7" 8 "Type 8" 15 "Invalid" ;
VAL_ 809 FrontMassageSeatSelectionCommand 0 "No adjustment" 1 "Driver adjustment" 2 "Passenger seat adjustment" 3 "FREE" ;
VAL_ 809 FragranceSelectionRequest 0 "Unavailable" 1 "Perfume tank 1" 2 "Perfume tank 2" 3 "Perfume tank 3" ;
VAL_ 809 FragranceIntensityRequest 0 "Unavailable" 1 "1" 2 "2" 3 "3" ;
VAL_ 809 FragranceDiffuserActivati_99a752 0 "Unavailable" 1 "Fragrance off request" 2 "Fragrance on request" 3 "Invalid" ;
VAL_ 809 FragranceCartridgeMonoStatus 0 "Unavailable" 1 "Single fragrance" 2 "Poly fragrance" 3 "Invalid" ;
VAL_ 809 IonizerActivationRequest 0 "ion_off" 1 "Ion clean" 2 "Ion comfort" 3 "Unavailable" ;
VAL_ 809 LkaButtonPressed 0 "Not activated" 1 "Activated" ;
VAL_ 809 AsrPlusModeSelection 0 "Normal" 1 "Snow" 2 "Mud" 3 "Sand" ;
VAL_ 809 FunctionSelectionRequest 0 "No request" 1 "Requested" ;
VAL_ 821 LpgEngineMode 0 "Petrol mode" 1 "LPG mode" 2 "Switchover in progress" 3 "Invalid" ;
VAL_ 821 TotalRangeDisplayed 2047 "Not_available" ;
VAL_ 821 LpgInstantConsumption2 511 "Not_available" ;
VAL_ 821 LpgRangeDisplayed 2047 "Not_available" ;
VAL_ 837 VideoMinute 63 "Not_available" ;
VAL_ 837 VideoHour 31 "Not_available" ;
VAL_ 837 VideoDay 63 "Not_available" ;
VAL_ 837 VideoMonth 15 "Not_available" ;
VAL_ 837 VideoYear 255 "Not_available" ;
VAL_ 837 PopupType2 0 "None" 1 "Automatic" 2 "Manual" ;
VAL_ 848 FrontRightSeatVentilationRequest 0 "No request" 1 "Level 1" 2 "Level 2" 3 "Level 3" ;
VAL_ 848 FrontLeftSeatHeatingRequest 0 "No request" 1 "Level 1" 2 "Level 2" 3 "Level 3" ;
VAL_ 848 FrontRightSeatHeatingRequest 0 "No request" 1 "Level 1" 2 "Level 2" 3 "Level 3" ;
VAL_ 848 EnergySaverModeStatus 0 "Inactive" 1 "Active" ;
VAL_ 848 FrontRightAirflowDistribution 0 "Auto comfort" 1 "Auto visibility" 2 "Feet" 3 "Ventilation" 4 "Defrosting" 5 "Foot vents" 6 "Foot vent defrosting" 7 "Ventilation defrosting" 8 "Foot/windscreen air distribution" 9 "Other than defrosting" ;
VAL_ 848 FrontLeftAirflowDistribution 0 "Auto comfort" 1 "Auto visibility" 2 "Feet" 3 "Ventilation" 4 "Defrosting" 5 "Foot vents" 6 "Foot vent defrosting" 7 "Ventilation defrosting" 8 "Foot/windscreen air distribution" 9 "Other than defrosting" ;
VAL_ 848 FrontBlowerManualSpeedDisplay 0 "Automatic" 1 "Speed 0" 2 "Speed 1" 3 "Speed 2" 4 "Speed 3" 5 "Speed 4" 6 "Speed5" 7 "Speed 6" 8 "Speed 7" 9 "Speed 8" ;
VAL_ 848 Mode 0 "Auto comfort" 1 "Auto visibility" 3 "Forced closed" 4 "Auto comfort without AQS (air quality sensor)" ;
VAL_ 848 AqsStatus 0 "Inactive" 1 "Active" ;
VAL_ 848 FrontRightTempSetpointValue 0 "Local" 1 "X-7 °C or Y-14 °F" 2 "X-6 °C or Y-12 °F" 3 "X-5 °C or Y-10 °F" 4 "X-4 °C or Y-8 °F" 5 "X-3 °C or Y-6 °F" 6 "X-2.5 °C or Y-5 °F" 7 "X-2 °C or Y-4 °F" 8 "X-1.5 °C or Y-3 °F" 9 "X-1 °C or Y-2 °F" 10 "X-0.5 °C or Y-1 °F" 11 "Centred value X°C or Y°F" 12 "X+0.5 °C or Y+1 °F" 13 "X+1 °C or Y+2 °F" 14 "X+1.5 °C or Y+3 °F" 15 "X+2°C or Y+4°F" 16 "X+2.5°C or Y+5°F" 17 "X+3 °C or Y+6°F" 18 "X+4 °C or Y+8 °F" 19 "X+5 °C or Y+10°F" 20 "X+6 °C or Y+12 °F" 21 "X+7 °C or Y+14 °F" 22 "HI" ;
VAL_ 848 FrontLeftSeatVentilationRequest 0 "No request" 1 "Level 1" 2 "Level 2" 3 "Level 3" ;
VAL_ 848 HeatedWindscreenActivatio_b0408e 0 "No request" 1 "Requested" ;
VAL_ 848 FrontLeftTempSetpointValue 0 "Local" 1 "X-7 °C or Y-14 °F" 2 "X-6 °C or Y-12 °F" 3 "X-5 °C or Y-10 °F" 4 "X-4 °C or Y-8 °F" 5 "X-3 °C or Y-6 °F" 6 "X-2.5 °C or Y-5 °F" 7 "X-2 °C or Y-4 °F" 8 "X-1.5 °C or Y-3 °F" 9 "X-1 °C or Y-2 °F" 10 "X-0.5 °C or Y-1 °F" 11 "Centred value X°C or Y°F" 12 "X+0.5 °C or Y+1 °F" 13 "X+1 °C or Y+2 °F" 14 "X+1.5 °C or Y+3 °F" 15 "X+2°C or Y+4°F" 16 "X+2.5°C or Y+5°F" 17 "X+3 °C or Y+6°F" 18 "X+4 °C or Y+8 °F" 19 "X+5 °C or Y+10°F" 20 "X+6 °C or Y+12 °F" 21 "X+7 °C or Y+14 °F" 22 "HI" ;
VAL_ 848 RestoreFlagStatus 0 "Inactive" 1 "Active" ;
VAL_ 848 MonoModeStatus 0 "Inactive" 1 "Active" ;
VAL_ 848 AcMaxStatus 0 "Inactive" 1 "Active" ;
VAL_ 848 EvaporatorSensorTemperature 65535 "Not_available" ;
VAL_ 848 AcType 0 "Light" 1 "Normal" 2 "Strong" ;
VAL_ 848 AcModeRequest 0 "Auto comfort" 1 "Auto visibility" 2 "Off" 3 "Invalid" ;
VAL_ 848 VisibilityRequest 0 "No request" 1 "Requested" ;
VAL_ 848 RearWindshieldHeat 0 "Not requested" 1 "Requested" ;
VAL_ 848 RestModeStatus 0 "Function not active" 1 "Function active" ;
VAL_ 848 FrontBlowerMotorFault 0 "Fault absent" 1 "Fault present" ;
VAL_ 858 TotalRemainingTime 4095 "Not_available" ;
VAL_ 858 TotalRemainingDistance 4095 "Not_available" ;
VAL_ 858 RemainingDistanceSpeedAbove90 127 "Not_available" ;
VAL_ 858 RemainingDistanceSpeed7090 127 "Not_available" ;
VAL_ 858 RemainingDistanceSpeed5070 127 "Not_available" ;
VAL_ 858 RemainingDistanceSpeed3050 127 "Not_available" ;
VAL_ 858 RangeBySpeedActivation 0 "Invalid" 1 "Trigger" ;
VAL_ 858 RemainingDistanceSpeed030 127 "Not_available" ;
VAL_ 859 ChargeTargetLevelRemote 2 "FULL" ;
VAL_ 859 ChargeTypeSelectionRemote 0 "Immediate" 1 "Delayed" ;
VAL_ 859 ChargeScheduleRemoteMenuA_155510 0 "Unavailable" 1 "Available" ;
VAL_ 864 FlowStatus 0 "ContinueToSend" 1 "Wait" 2 "Overflow" ;
VAL_ 864 IsoTpFrameType 0 "SingleFrame" 1 "FirstFrame" 2 "ConsecutiveFrame" 3 "FlowControl" ;
VAL_ 865 RtabRechargeMenuDisplayAu_d73943 0 "No request" 1 "Requested" ;
VAL_ 865 ClimatePrecondMenuDisplay_2fd6ce 0 "No request" 1 "Requested" ;
VAL_ 865 AmlaMenuPresence 0 "No request" 1 "Requested" ;
VAL_ 865 AdsdMenuPresence 0 "No request" 1 "Requested" ;
VAL_ 865 PrivacyModeMenuPresence 0 "No request" 1 "Requested" ;
VAL_ 865 ArsMenuPresence 0 "No request" 1 "Requested" ;
VAL_ 865 AfsMenuPresence 0 "No request" 1 "Requested" ;
VAL_ 865 IrvMenuPresence 0 "No request" 1 "Requested" ;
VAL_ 865 PolychromePackBlockMenuPresence 0 "No request" 1 "Requested" ;
VAL_ 865 PpcAnimationPresence 0 "No request" 1 "Requested" ;
VAL_ 865 Dae4wdPresence 0 "No request" 1 "Requested" ;
VAL_ 865 DaePresence 0 "No request" 1 "Requested" ;
VAL_ 865 CafrMenuPresence 0 "Option absent" 1 "Option present" ;
VAL_ 865 EcsModeMenuPresence 0 "Option absent" 1 "Option present" ;
VAL_ 865 DriverAlertAssistMenuPresence 0 "No request" 1 "Requested" ;
VAL_ 865 LoadedArmsLockMenuPresence 0 "No request" 1 "Requested" ;
VAL_ 865 UserProfilePresence 0 "Option absent" 1 "Option present" ;
VAL_ 865 LoadedArmsAccessMenuPresence 0 "No request" 1 "Requested" ;
VAL_ 865 IlvPresence 0 "Option absent" 1 "Option present" ;
VAL_ 865 GrilleLightingPresence 0 "Option absent" 1 "Option present" ;
VAL_ 865 LowCurrentChargePresence 0 "Option absent" 1 "Option present" ;
VAL_ 865 TpmsPresence 0 "No TPM system" 1 "Direct TPMS, first generation" 2 "Direct TPMS, 2nd generation" 3 "Indirect tyre-pressure monitoring system" ;
VAL_ 865 IrcPresence 0 "IRC absent" 1 "IRC present" ;
VAL_ 865 XvvSpeedMenuPresence 0 "Option absent" 1 "Option present" ;
VAL_ 865 ArcSensitivityMenuPresence 0 "Option absent" 1 "Option present" ;
VAL_ 865 CollisionRiskBrakingOptio_4c4434 0 "Option absent" 1 "Option present" ;
VAL_ 865 TpmsReinitializationOptio_aa6f62 0 "Option absent" 1 "Option present" ;
VAL_ 865 PpcPresence 0 "No request" 1 "Requested" ;
VAL_ 865 EtsrMenuPresence 0 "No request" 1 "Requested" ;
VAL_ 865 ReverseIndexingPresence 0 "Option absent" 1 "Option present" ;
VAL_ 865 SoundHarmonyOptionPresence 0 "No request" 1 "Requested" ;
VAL_ 865 ElectricParkingBrakeOptio_c6beca 0 "Option absent" 1 "Option present" ;
VAL_ 865 CongigurableKeyOption 0 "Option absent" 1 "Option present" ;
VAL_ 865 XvvLimitsMenuPresence 0 "No request" 1 "Requested" ;
VAL_ 865 NblPresence 0 "TNB unit absent" 1 "TNB unit present" ;
VAL_ 865 CabOpeningsSelectivityCus_fd4768 0 "No request" 1 "Requested" ;
VAL_ 865 DoorSelectivityOptionPresence 0 "Option absent" 1 "Option present" ;
VAL_ 865 RearOpeningsSelectivityOp_53876f 0 "No request" 1 "Requested" ;
VAL_ 865 RearFlapMotorizationCusto_5e7171 0 "No request" 1 "Requested" ;
VAL_ 865 DriverGreetingPresence 0 "Option absent" 1 "Option present" ;
VAL_ 865 FollowMeHomeOptionPresence 0 "Option absent" 1 "Option present" ;
VAL_ 865 RearWiperInReverseOptionPresence 0 "Option absent" 1 "Option present" ;
VAL_ 865 ParkingAidInhibitionOptio_937dc5 0 "Option absent" 1 "Option present" ;
VAL_ 865 DaylightsOptionPresence 0 "Option absent" 1 "Option present" ;
VAL_ 865 AutomaticHeadlightsSwitch_2a5f4f 0 "Option absent" 1 "Option present" ;
VAL_ 865 AmbientLightingPresence 0 "Option absent" 1 "Option present" ;
VAL_ 865 BlindSpotMonitoringPresence 0 "Option absent" 1 "Option present" ;
VAL_ 865 AdaptiveLightingOptionPresence 0 "Option absent" 1 "Option present" ;
VAL_ 865 UnlockingLightingCustomiz_78a725 0 "No request" 1 "Requested" ;
VAL_ 865 MotorwayLightingFunctionPresence 0 "Option absent" 1 "Option present" ;
VAL_ 865 SettingsMenuInfoAvailability 0 "Unavailable" 1 "Available" ;
VAL_ 868 FrontLeftSeatVentilationButton 0 "Not pushed" 1 "Pushed" ;
VAL_ 868 FrontRightSeatVentilationButton 0 "Not pushed" 1 "Pushed" ;
VAL_ 868 FrontLeftSeatHeaterButton 0 "Not pushed" 1 "Pushed" ;
VAL_ 868 FrontRightSeatHeaterButton 0 "Not pushed" 1 "Pushed" ;
VAL_ 868 AcOffButton 0 "Released" 1 "Pressed" ;
VAL_ 868 ClimateSliderLevelChange 0 "Value 1" 1 "Value 2" ;
VAL_ 868 RearClimateLockButton 0 "Released" 1 "Pressed" ;
VAL_ 868 FrontRightDefrostButton 0 "Released" 1 "Pressed" ;
VAL_ 868 FrontFanLevelSlider 0 "Speed 0" 1 "Speed 1" 2 "Speed 2" 3 "Speed 3" 4 "Speed 4" 5 "Speed 5" 6 "Speed 6" 7 "Speed 7" 8 "Speed 8" 14 "Unavailable" ;
VAL_ 868 FrontRightVentAirflowButton 0 "Released" 1 "Pressed" ;
VAL_ 868 FrontRightFootAirflowButton 0 "Released" 1 "Pressed" ;
VAL_ 868 FrontRightTempLevelSlider 0 "Local" 1 "Level 1" 2 "Level 2" 3 "Level 3" 4 "Level 4" 5 "Level 5" 6 "Level 6" 7 "Level 7" 8 "Level 8" 9 "Level 9" 10 "Level 10" 11 "Level 11" 12 "Level 12" 13 "Level 13" 14 "Level 14" 15 "Level 15" 16 "Level 16" 17 "Level 17" 18 "Level 18" 19 "Level 19" 22 "HI" 30 "Unavailable" ;
VAL_ 868 EnergySaverModeButton 0 "Released" 1 "Pressed" ;
VAL_ 868 FrontLeftTempSetpoint 0 "Local" 1 "Level 1" 2 "Level 2" 3 "Level 3" 4 "Level 4" 5 "Level 5" 6 "Level 6" 7 "Level 7" 8 "Level 8" 9 "Level 9" 10 "Level 10" 11 "Level 11" 12 "Level 12" 13 "Level 13" 14 "Level 14" 15 "Level 15" 16 "Level 16" 17 "Level 17" 18 "Level 18" 19 "Level 19" 22 "HI" 30 "Unavailable" ;
VAL_ 868 RearClimateOnoffButton 0 "Released" 1 "Pressed" ;
VAL_ 868 AcMaxButton 0 "Released" 1 "Pressed" ;
VAL_ 868 AcAutoStrongButton 0 "Released" 1 "Pressed" ;
VAL_ 868 AcAutoNormalButton 0 "Released" 1 "Pressed" ;
VAL_ 868 AcAutoLightButton 0 "Released" 1 "Pressed" ;
VAL_ 868 AcAutoButton 0 "Released" 1 "Pressed" ;
VAL_ 868 AcButton 0 "Released" 1 "Pressed" ;
VAL_ 868 MonoZoneButton 0 "Released" 1 "Pressed" ;
VAL_ 868 AirQualitySensorButton 0 "Released" 1 "Pressed" ;
VAL_ 868 AirIntakeButton 0 "Released" 1 "Pressed" ;
VAL_ 868 FrontLeftDefrostButton 0 "Released" 1 "Pressed" ;
VAL_ 868 FrontLeftVentAirflowButton 0 "Released" 1 "Pressed" ;
VAL_ 868 FrontLeftFootAirflowButton 0 "Released" 1 "Pressed" ;
VAL_ 868 FrontFanMinusButton 0 "Released" 1 "Pressed" ;
VAL_ 868 FrontFanPlusButton 0 "Released" 1 "Pressed" ;
VAL_ 868 FrontRightTempMinusButton 0 "Released" 1 "Pressed" ;
VAL_ 868 FrontRightTempPlusButton 0 "Released" 1 "Pressed" ;
VAL_ 868 FrontLeftTempMinusButton 0 "Released" 1 "Pressed" ;
VAL_ 868 FrontLeftTempPlusButton 0 "Released" 1 "Pressed" ;
VAL_ 872 ZevDurationPercentTrip1Adjusted 127 "Not_available" ;
VAL_ 872 ZevDurationPercentTrip1 127 "Not_available" ;
VAL_ 872 ZevDurationSecondsTrip1 63 "Not_available" ;
VAL_ 872 ZevDurationMinutesTrip1 63 "Not_available" ;
VAL_ 872 ZevDurationHoursTrip1 2047 "Not_available" ;
VAL_ 872 TripDurationSecondsTrip1 63 "Not_available" ;
VAL_ 872 TripDurationMinutesTrip1 63 "Not_available" ;
VAL_ 872 TripDurationHoursTrip1 2047 "Not_available" ;
VAL_ 873 RoamingState 0 "Not active" 1 "Active" ;
VAL_ 873 RoamingAllowed 0 "Not Allowed" 1 "Allowed" ;
VAL_ 873 LocationServiceEnabled 0 "Not active" 1 "Active" ;
VAL_ 873 PopupPriority 0 "Z3.0" 1 "Z3.1" 2 "Z3.2" 3 "Z3.3" 4 "Z3.4" 5 "Z3.5" 6 "Z3.6" 7 "Z3.7" 8 "Z3.8" 9 "Z3.9" 10 "Z3.10" ;
VAL_ 873 WifiSecurityType 0 "Not secured" 1 "WEP" 2 "WPA-PSK" 3 "WPA2-PSK" ;
VAL_ 873 PopupTimeout 0 "Init" 1 "T1: 3 s" 2 "T2: 7 s" 3 "T3: 15 s" 4 "T4: 30 sec" 5 "T5: 60 sec" 6 "Tauto : no temp" ;
VAL_ 873 PopupId 0 "No display" 1 "Incoming advisor call" 2 "Initiated advisor call" 3 "Emergency call initiated" 4 "Connected Advisor call" 5 "Connected emergency call" 6 "Sending vehicle location" 7 "OnStar main menu" 8 "Roaming active" 9 "Roaming ended" ;
VAL_ 886 FlowStatus 0 "ContinueToSend" 1 "Wait" 2 "Overflow" ;
VAL_ 886 IsoTpFrameType 0 "SingleFrame" 1 "FirstFrame" 2 "ConsecutiveFrame" 3 "FlowControl" ;
VAL_ 897 FlowStatus 0 "ContinueToSend" 1 "Wait" 2 "Overflow" ;
VAL_ 897 IsoTpFrameType 0 "SingleFrame" 1 "FirstFrame" 2 "ConsecutiveFrame" 3 "FlowControl" ;
VAL_ 901 AutoAccidentRecordingMenuRequest 0 "Not active" 1 "Active" 3 "No action" ;
VAL_ 901 ListFocusItem 0 "No focus requested" 1 "Focus on the 1st item" 2 "focus on the 2nd item" 3 "Focus on the 3rd item" 4 "Focus on the 4th item" 5 "Focus on the 5th item" 6 "Focus on the 6th item" ;
VAL_ 901 IdvrListValidatedItem 0 "No validation" 1 "Validation of 1st item displayed" 2 "Validation of 2nd item displayed" 3 "Validation of 3rd item displayed" 4 "Validation of 4th item displayed" 5 "Validation of the 5th displayed item" 6 "Validation of 6th item displayed" ;
VAL_ 901 ManualAccidentRequestLive 0 "No request" 1 "Accident record requested" ;
VAL_ 901 ManualAccidentRequestRecord 0 "No request" 1 "Accident record requested" ;
VAL_ 901 DrivingRecordingMenuRequest 0 "Not active" 1 "Active" 3 "No action" ;
VAL_ 901 IdvrKnobSync 0 "Synchronization requested" 1 "No synchronization requested" ;
VAL_ 901 IdvrVideoTypeRequest 0 "No action" 1 "Live video" 2 "ADAS camera" ;
VAL_ 901 IdvrPlaybackCommand 0 "No action" 1 "Play" 2 "Paused" 3 "Stopped" 4 "Previous track" 5 "Reward" 6 "Next track" 7 "Forward" ;
VAL_ 901 IdvrListOpenRequest 0 "No list requested" 1 "Request to open the daily list" 2 "Ask to open accident record" ;
VAL_ 907 OtaUpdateUserInteraction 0 "No user interaction" 1 "MeclInteraction" 2 "Unlocked FSE interaction" 3 "Lounge interaction" 4 "Charge interaction" 5 "Vehicle washing interaction" 6 "Error interaction" ;
VAL_ 907 OtaUpdateType 0 "Customer (normal)" 1 "Aftersales command" 2 "Depot/factory" ;
VAL_ 907 OtaUpdateAuthorizationStatus 0 "Installation not allowed" 1 "Only non-immobilising installation allowed" 2 "Any installation allowed" ;
VAL_ 907 OtaInstallationModeStatus 0 "Installation mode not active" 1 "Installation mode in progress" 2 "Installation mode active" ;
VAL_ 916 RemoteSendChargeDataRequest 0 "Not requested" 1 "Requested" ;
VAL_ 916 RemoteLockUnlockLongrangeRequest 0 "No request" 1 "Lock all request" 2 "Lock-all request confirmed" 3 "Unlock all request" 4 "Unlock driver door" 5 "Unlock trunk" 7 "Value not used (111)" ;
VAL_ 918 AuxBatterySoc 255 "Not_available" ;
VAL_ 918 ChargingHmiState 0 "Disconnected (reported; driving capture)" 1 "Charging (continuous-charge capture)" 2 "Fault (HS3 source only; not observed)" 3 "Stopped (delayed-mode captures)" 4 "Finished (HS3 source only; not observed)" 5 "Unknown 5" 6 "Unknown 6" 7 "Unknown 7" ;
VAL_ 918 RemoteDiagnosisAuthorization 0 "Not available" 1 "Available" 3 "Failure detected" ;
VAL_ 922 TripElectricConsumption 511 "Not_available" ;
VAL_ 922 TripAverageFuelConsumption 511 "Not_available" ;
VAL_ 922 ZevAverageConsumptionPeriod6 63 "Not_available" ;
VAL_ 922 ZevAverageConsumptionPeriod5 63 "Not_available" ;
VAL_ 922 ZevAverageConsumptionPeriod4 63 "Not_available" ;
VAL_ 922 ZevAverageConsumptionPeriod3 63 "Not_available" ;
VAL_ 922 ZevAverageConsumptionPeriod2 63 "Not_available" ;
VAL_ 922 ZevAverageConsumptionPeriod1 63 "Not_available" ;
VAL_ 923 TimeMinute 63 "Not_available" ;
VAL_ 923 TimeHour 31 "Not_available" ;
VAL_ 923 ClockDay 63 "Not_available" ;
VAL_ 923 ClockMonth 0 "Value not used (0000)" 1 "January" 2 "February" 3 "March" 4 "April" 5 "May" 6 "June" 7 "July" 8 "August" 9 "September" 10 "October" 11 "November" 12 "December" 13 "Unused value (1101)" 14 "Unavailable" 15 "Invalid" ;
VAL_ 923 ClockYear 127 "Not_available" ;
VAL_ 923 ConfigDisplayTime 0 "Time displayed in 12-hour mode" 1 "Time displayed in 24-hour mode" ;
VAL_ 928 FlowStatus 0 "ContinueToSend" 1 "Wait" 2 "Overflow" ;
VAL_ 928 IsoTpFrameType 0 "SingleFrame" 1 "FirstFrame" 2 "ConsecutiveFrame" 3 "FlowControl" ;
VAL_ 929 SetpointPictogramNumber 0 "Data invalid" 1 "Left fork" 2 "Right fork" 3 "Left U-turn" 4 "Right U-turn" 5 "U-turn at roundabout" 6 "Turn left" 7 "Turn right" 8 "Heading south" 9 "Heading south-south-east" 10 "Heading south-east" 11 "Heading south-south-east" 12 "Heading East" 13 "Head North East East" 14 "Heading North-East" 15 "Heading North-North-East" 16 "Heading North" 17 "Heading north-northwest" 18 "Heading north-west" 19 "Heading west-north-west" 20 "Heading west" 21 "Heading south-west-west" 22 "Heading South West" 23 "Heading South-South-West" 24 "Checkered flag" 25 "Stage checkered flag" 26 "Checkered flag stage 1" 27 "Finish flag, stage 2" 28 "Finish flag, step 3" 29 "Checkered flag, stage 4" 30 "Checkered flag, stage 5" 31 "Checkered flag, stage 6" 32 "Checkered flag, stage 7" 33 "Checkered flag stage 8" 34 "Checkered flag, stage 9" 35 "Checkered flag stage 10" 36 "Checkered flag, stage 11" 37 "Stage 12 finish flag" ;
VAL_ 929 RoundaboutMaskSegment 0 "Segment off" 1 "Segment on" ;
VAL_ 929 NavSegmentAngle15 0 "Segment off" 1 "Basic segment" 2 "Arrow segment" 3 "One way" ;
VAL_ 929 NavSegmentAngle14 0 "Segment off" 1 "Basic segment" 2 "Arrow segment" 3 "One way" ;
VAL_ 929 NavSegmentAngle13 0 "Segment off" 1 "Basic segment" 2 "Arrow segment" 3 "One way" ;
VAL_ 929 NavSegmentAngle12 0 "Segment off" 1 "Basic segment" 2 "Arrow segment" 3 "One way" ;
VAL_ 929 NavSegmentAngle11 0 "Segment off" 1 "Basic segment" 2 "Arrow segment" 3 "One way" ;
VAL_ 929 NavSegmentAngle10 0 "Segment off" 1 "Basic segment" 2 "Arrow segment" 3 "One way" ;
VAL_ 929 NavSegmentAngle9 0 "Segment off" 1 "Basic segment" 2 "Arrow segment" 3 "One way" ;
VAL_ 929 NavSegmentAngle8 0 "Segment off" 1 "Basic segment" 2 "Arrow segment" 3 "One way" ;
VAL_ 929 NavSegmentAngle7 0 "Segment off" 1 "Basic segment" 2 "Arrow segment" 3 "One way" ;
VAL_ 929 NavSegmentAngle6 0 "Segment off" 1 "Basic segment" 2 "Arrow segment" 3 "One way" ;
VAL_ 929 NavSegmentAngle5 0 "Segment off" 1 "Basic segment" 2 "Arrow segment" 3 "One way" ;
VAL_ 929 NavSegmentAngle4 0 "Segment off" 1 "Basic segment" 2 "Arrow segment" 3 "One way" ;
VAL_ 929 NavSegmentAngle3 0 "Segment off" 1 "Basic segment" 2 "Arrow segment" 3 "One way" ;
VAL_ 929 NavSegmentAngle2 0 "Segment off" 1 "Basic segment" 2 "Arrow segment" 3 "One way" ;
VAL_ 929 NavSegmentAngle1 0 "Segment off" 1 "Basic segment" 2 "Arrow segment" 3 "One way" ;
VAL_ 929 NavSegmentDecrement8 0 "Segment off" 1 "Segment on" ;
VAL_ 929 NavSegmentDecrement7 0 "Segment off" 1 "Segment on" ;
VAL_ 929 NavSegmentDecrement6 0 "Segment off" 1 "Segment on" ;
VAL_ 929 NavSegmentDecrement5 0 "Segment off" 1 "Segment on" ;
VAL_ 929 NavSegmentDecrement4 0 "Segment off" 1 "Segment on" ;
VAL_ 929 NavSegmentDecrement3 0 "Segment off" 1 "Segment on" ;
VAL_ 929 NavSegmentDecrement2 0 "Segment off" 1 "Segment on" ;
VAL_ 929 NavSegmentDecrement1 0 "Segment off" 1 "Segment on" ;
VAL_ 929 DistanceToSetpoint 0 "0 m or 0 Yd" 1 "10 m or 10 yd" 2 "20 m or 20 yd" 3 "30 m or 30 yd" 4 "40 m or 40 yd" 5 "50 m or 50 yd" 6 "60 m or 60 yd" 7 "70 m or 70 yd" 8 "80 m or 80 yd" 9 "90 m or 90 yd" 10 "100 m or 100 yd" 11 "150 m or 150 yd" 12 "200 m or 200 yd" 13 "250 m or 250 yd" 14 "300 m or 300 yd" 15 "350 m or 350 yd" 16 "400 m or 400 yd" 17 "600 m or 600 yd" 18 "800 m or 800 yd" 19 "1 km or 1 mile" 20 "1.2 km or 1.2 mile" 21 "1.4 km or 1.4 mile" 22 "1.6 km or 1.6 mile" 23 "1.8 km or 1.8 mile" 24 "2.0 km or 2.0 mile" 25 "2.2 km or 2.2 miles" 26 "2.4 km or 2.4 miles" 27 "Invalid" 28 "Invalid" 29 "Invalid" 30 "Invalid" 31 "Invalid" ;
VAL_ 929 SetpointEnd 0 "End of setpoint" 1 "Setpoint in progress" ;
VAL_ 931 NormalModeCapability 0 "False" 1 "True" ;
VAL_ 931 EcoPlusModeCapability 0 "False" 1 "True" ;
VAL_ 931 EcoModeCapability 0 "False" 1 "True" ;
VAL_ 931 ComfortModeCapability 0 "False" 1 "True" ;
VAL_ 931 SportModeCapability 0 "False" 1 "True" ;
VAL_ 931 AwdModeCapability 0 "False" 1 "True" ;
VAL_ 931 HybridEcoModeCapability 0 "False" 1 "True" ;
VAL_ 931 ZevEcoModeCapability 0 "False" 1 "True" ;
VAL_ 931 ZevModeCapability 0 "False" 1 "True" ;
VAL_ 931 HybridVehicleModeSelector_ba5418 0 "Selector absent" 1 "PHEV full modes" 2 "PHEV full except comfort" 3 "PHEV full except AWD" 4 "PHEV full except comfort AWD" 5 "Eco / Normal / Sport" 6 "Normal, Eco, Eco+" ;
VAL_ 931 IlvSpeedPanelValueType 0 "None" 1 "LEGAL" 2 "Conditional" ;
VAL_ 931 IlvConditionalOverspeedFlag 0 "No overspeed" 1 "Overspeed" ;
VAL_ 931 IlvConditionalSpeedToDisplay 255 "Not_available" ;
VAL_ 931 IlvImplicitSignType 0 "Motorway" 1 "Built-up area" 2 "High-speed road" 3 "Home zone" 15 "Invalid" ;
VAL_ 931 IlvConditionalSignType 0 "Snow" 1 "Hours" 15 "Invalid" ;
VAL_ 931 IlvLeftSlotNoSpeedPanel 255 "Not_available" ;
VAL_ 931 IlvRightSlotNoSpeedPanel 255 "Not_available" ;
VAL_ 932 ArcPushInput 0 "Inactive" 1 "Active" ;
VAL_ 932 SideTrajectoryButtonStatus 0 "Not activated" 1 "Activated" ;
SG_MUL_VAL_ 808 SingleFrameLength IsoTpFrameType 0-0;
SG_MUL_VAL_ 808 FirstFrameLength IsoTpFrameType 1-1;
SG_MUL_VAL_ 808 ConsecutiveSequence IsoTpFrameType 2-2;
SG_MUL_VAL_ 808 FlowStatus IsoTpFrameType 3-3;
SG_MUL_VAL_ 808 UnknownPciLow IsoTpFrameType 4-15;
SG_MUL_VAL_ 808 BlockSize IsoTpFrameType 3-3;
SG_MUL_VAL_ 808 SingleData1 IsoTpFrameType 0-0;
SG_MUL_VAL_ 808 ConsecutiveData1 IsoTpFrameType 2-2;
SG_MUL_VAL_ 808 UnknownData1 IsoTpFrameType 4-15;
SG_MUL_VAL_ 808 SeparationTimeRaw IsoTpFrameType 3-3;
SG_MUL_VAL_ 808 SingleData2 IsoTpFrameType 0-0;
SG_MUL_VAL_ 808 ConsecutiveData2 IsoTpFrameType 2-2;
SG_MUL_VAL_ 808 UnknownData2 IsoTpFrameType 4-15;
SG_MUL_VAL_ 808 FirstData1 IsoTpFrameType 1-1;
SG_MUL_VAL_ 808 SingleData3 IsoTpFrameType 0-0;
SG_MUL_VAL_ 808 ConsecutiveData3 IsoTpFrameType 2-2;
SG_MUL_VAL_ 808 UnknownData3 IsoTpFrameType 4-15;
SG_MUL_VAL_ 808 FirstData2 IsoTpFrameType 1-1;
SG_MUL_VAL_ 808 FlowPadding1 IsoTpFrameType 3-3;
SG_MUL_VAL_ 808 SingleData4 IsoTpFrameType 0-0;
SG_MUL_VAL_ 808 ConsecutiveData4 IsoTpFrameType 2-2;
SG_MUL_VAL_ 808 UnknownData4 IsoTpFrameType 4-15;
SG_MUL_VAL_ 808 FirstData3 IsoTpFrameType 1-1;
SG_MUL_VAL_ 808 FlowPadding2 IsoTpFrameType 3-3;
SG_MUL_VAL_ 808 SingleData5 IsoTpFrameType 0-0;
SG_MUL_VAL_ 808 ConsecutiveData5 IsoTpFrameType 2-2;
SG_MUL_VAL_ 808 UnknownData5 IsoTpFrameType 4-15;
SG_MUL_VAL_ 808 FirstData4 IsoTpFrameType 1-1;
SG_MUL_VAL_ 808 FlowPadding3 IsoTpFrameType 3-3;
SG_MUL_VAL_ 808 SingleData6 IsoTpFrameType 0-0;
SG_MUL_VAL_ 808 ConsecutiveData6 IsoTpFrameType 2-2;
SG_MUL_VAL_ 808 UnknownData6 IsoTpFrameType 4-15;
SG_MUL_VAL_ 808 FirstData5 IsoTpFrameType 1-1;
SG_MUL_VAL_ 808 FlowPadding4 IsoTpFrameType 3-3;
SG_MUL_VAL_ 808 SingleData7 IsoTpFrameType 0-0;
SG_MUL_VAL_ 808 ConsecutiveData7 IsoTpFrameType 2-2;
SG_MUL_VAL_ 808 UnknownData7 IsoTpFrameType 4-15;
SG_MUL_VAL_ 808 FirstData6 IsoTpFrameType 1-1;
SG_MUL_VAL_ 808 FlowPadding5 IsoTpFrameType 3-3;
SG_MUL_VAL_ 864 SingleFrameLength IsoTpFrameType 0-0;
SG_MUL_VAL_ 864 FirstFrameLength IsoTpFrameType 1-1;
SG_MUL_VAL_ 864 ConsecutiveSequence IsoTpFrameType 2-2;
SG_MUL_VAL_ 864 FlowStatus IsoTpFrameType 3-3;
SG_MUL_VAL_ 864 UnknownPciLow IsoTpFrameType 4-15;
SG_MUL_VAL_ 864 BlockSize IsoTpFrameType 3-3;
SG_MUL_VAL_ 864 SingleData1 IsoTpFrameType 0-0;
SG_MUL_VAL_ 864 ConsecutiveData1 IsoTpFrameType 2-2;
SG_MUL_VAL_ 864 UnknownData1 IsoTpFrameType 4-15;
SG_MUL_VAL_ 864 SeparationTimeRaw IsoTpFrameType 3-3;
SG_MUL_VAL_ 864 SingleData2 IsoTpFrameType 0-0;
SG_MUL_VAL_ 864 ConsecutiveData2 IsoTpFrameType 2-2;
SG_MUL_VAL_ 864 UnknownData2 IsoTpFrameType 4-15;
SG_MUL_VAL_ 864 FirstData1 IsoTpFrameType 1-1;
SG_MUL_VAL_ 864 SingleData3 IsoTpFrameType 0-0;
SG_MUL_VAL_ 864 ConsecutiveData3 IsoTpFrameType 2-2;
SG_MUL_VAL_ 864 UnknownData3 IsoTpFrameType 4-15;
SG_MUL_VAL_ 864 FirstData2 IsoTpFrameType 1-1;
SG_MUL_VAL_ 864 FlowPadding1 IsoTpFrameType 3-3;
SG_MUL_VAL_ 864 SingleData4 IsoTpFrameType 0-0;
SG_MUL_VAL_ 864 ConsecutiveData4 IsoTpFrameType 2-2;
SG_MUL_VAL_ 864 UnknownData4 IsoTpFrameType 4-15;
SG_MUL_VAL_ 864 FirstData3 IsoTpFrameType 1-1;
SG_MUL_VAL_ 864 FlowPadding2 IsoTpFrameType 3-3;
SG_MUL_VAL_ 864 SingleData5 IsoTpFrameType 0-0;
SG_MUL_VAL_ 864 ConsecutiveData5 IsoTpFrameType 2-2;
SG_MUL_VAL_ 864 UnknownData5 IsoTpFrameType 4-15;
SG_MUL_VAL_ 864 FirstData4 IsoTpFrameType 1-1;
SG_MUL_VAL_ 864 FlowPadding3 IsoTpFrameType 3-3;
SG_MUL_VAL_ 864 SingleData6 IsoTpFrameType 0-0;
SG_MUL_VAL_ 864 ConsecutiveData6 IsoTpFrameType 2-2;
SG_MUL_VAL_ 864 UnknownData6 IsoTpFrameType 4-15;
SG_MUL_VAL_ 864 FirstData5 IsoTpFrameType 1-1;
SG_MUL_VAL_ 864 FlowPadding4 IsoTpFrameType 3-3;
SG_MUL_VAL_ 864 SingleData7 IsoTpFrameType 0-0;
SG_MUL_VAL_ 864 ConsecutiveData7 IsoTpFrameType 2-2;
SG_MUL_VAL_ 864 UnknownData7 IsoTpFrameType 4-15;
SG_MUL_VAL_ 864 FirstData6 IsoTpFrameType 1-1;
SG_MUL_VAL_ 864 FlowPadding5 IsoTpFrameType 3-3;
SG_MUL_VAL_ 886 SingleFrameLength IsoTpFrameType 0-0;
SG_MUL_VAL_ 886 FirstFrameLength IsoTpFrameType 1-1;
SG_MUL_VAL_ 886 ConsecutiveSequence IsoTpFrameType 2-2;
SG_MUL_VAL_ 886 FlowStatus IsoTpFrameType 3-3;
SG_MUL_VAL_ 886 UnknownPciLow IsoTpFrameType 4-15;
SG_MUL_VAL_ 886 BlockSize IsoTpFrameType 3-3;
SG_MUL_VAL_ 886 SingleData1 IsoTpFrameType 0-0;
SG_MUL_VAL_ 886 ConsecutiveData1 IsoTpFrameType 2-2;
SG_MUL_VAL_ 886 UnknownData1 IsoTpFrameType 4-15;
SG_MUL_VAL_ 886 SeparationTimeRaw IsoTpFrameType 3-3;
SG_MUL_VAL_ 886 SingleData2 IsoTpFrameType 0-0;
SG_MUL_VAL_ 886 ConsecutiveData2 IsoTpFrameType 2-2;
SG_MUL_VAL_ 886 UnknownData2 IsoTpFrameType 4-15;
SG_MUL_VAL_ 886 FirstData1 IsoTpFrameType 1-1;
SG_MUL_VAL_ 886 SingleData3 IsoTpFrameType 0-0;
SG_MUL_VAL_ 886 ConsecutiveData3 IsoTpFrameType 2-2;
SG_MUL_VAL_ 886 UnknownData3 IsoTpFrameType 4-15;
SG_MUL_VAL_ 886 FirstData2 IsoTpFrameType 1-1;
SG_MUL_VAL_ 886 FlowPadding1 IsoTpFrameType 3-3;
SG_MUL_VAL_ 886 SingleData4 IsoTpFrameType 0-0;
SG_MUL_VAL_ 886 ConsecutiveData4 IsoTpFrameType 2-2;
SG_MUL_VAL_ 886 UnknownData4 IsoTpFrameType 4-15;
SG_MUL_VAL_ 886 FirstData3 IsoTpFrameType 1-1;
SG_MUL_VAL_ 886 FlowPadding2 IsoTpFrameType 3-3;
SG_MUL_VAL_ 886 SingleData5 IsoTpFrameType 0-0;
SG_MUL_VAL_ 886 ConsecutiveData5 IsoTpFrameType 2-2;
SG_MUL_VAL_ 886 UnknownData5 IsoTpFrameType 4-15;
SG_MUL_VAL_ 886 FirstData4 IsoTpFrameType 1-1;
SG_MUL_VAL_ 886 FlowPadding3 IsoTpFrameType 3-3;
SG_MUL_VAL_ 886 SingleData6 IsoTpFrameType 0-0;
SG_MUL_VAL_ 886 ConsecutiveData6 IsoTpFrameType 2-2;
SG_MUL_VAL_ 886 UnknownData6 IsoTpFrameType 4-15;
SG_MUL_VAL_ 886 FirstData5 IsoTpFrameType 1-1;
SG_MUL_VAL_ 886 FlowPadding4 IsoTpFrameType 3-3;
SG_MUL_VAL_ 886 SingleData7 IsoTpFrameType 0-0;
SG_MUL_VAL_ 886 ConsecutiveData7 IsoTpFrameType 2-2;
SG_MUL_VAL_ 886 UnknownData7 IsoTpFrameType 4-15;
SG_MUL_VAL_ 886 FirstData6 IsoTpFrameType 1-1;
SG_MUL_VAL_ 886 FlowPadding5 IsoTpFrameType 3-3;
SG_MUL_VAL_ 897 SingleFrameLength IsoTpFrameType 0-0;
SG_MUL_VAL_ 897 FirstFrameLength IsoTpFrameType 1-1;
SG_MUL_VAL_ 897 ConsecutiveSequence IsoTpFrameType 2-2;
SG_MUL_VAL_ 897 FlowStatus IsoTpFrameType 3-3;
SG_MUL_VAL_ 897 UnknownPciLow IsoTpFrameType 4-15;
SG_MUL_VAL_ 897 BlockSize IsoTpFrameType 3-3;
SG_MUL_VAL_ 897 SingleData1 IsoTpFrameType 0-0;
SG_MUL_VAL_ 897 ConsecutiveData1 IsoTpFrameType 2-2;
SG_MUL_VAL_ 897 UnknownData1 IsoTpFrameType 4-15;
SG_MUL_VAL_ 897 SeparationTimeRaw IsoTpFrameType 3-3;
SG_MUL_VAL_ 897 SingleData2 IsoTpFrameType 0-0;
SG_MUL_VAL_ 897 ConsecutiveData2 IsoTpFrameType 2-2;
SG_MUL_VAL_ 897 UnknownData2 IsoTpFrameType 4-15;
SG_MUL_VAL_ 897 FirstData1 IsoTpFrameType 1-1;
SG_MUL_VAL_ 897 SingleData3 IsoTpFrameType 0-0;
SG_MUL_VAL_ 897 ConsecutiveData3 IsoTpFrameType 2-2;
SG_MUL_VAL_ 897 UnknownData3 IsoTpFrameType 4-15;
SG_MUL_VAL_ 897 FirstData2 IsoTpFrameType 1-1;
SG_MUL_VAL_ 897 FlowPadding1 IsoTpFrameType 3-3;
SG_MUL_VAL_ 897 SingleData4 IsoTpFrameType 0-0;
SG_MUL_VAL_ 897 ConsecutiveData4 IsoTpFrameType 2-2;
SG_MUL_VAL_ 897 UnknownData4 IsoTpFrameType 4-15;
SG_MUL_VAL_ 897 FirstData3 IsoTpFrameType 1-1;
SG_MUL_VAL_ 897 FlowPadding2 IsoTpFrameType 3-3;
SG_MUL_VAL_ 897 SingleData5 IsoTpFrameType 0-0;
SG_MUL_VAL_ 897 ConsecutiveData5 IsoTpFrameType 2-2;
SG_MUL_VAL_ 897 UnknownData5 IsoTpFrameType 4-15;
SG_MUL_VAL_ 897 FirstData4 IsoTpFrameType 1-1;
SG_MUL_VAL_ 897 FlowPadding3 IsoTpFrameType 3-3;
SG_MUL_VAL_ 897 SingleData6 IsoTpFrameType 0-0;
SG_MUL_VAL_ 897 ConsecutiveData6 IsoTpFrameType 2-2;
SG_MUL_VAL_ 897 UnknownData6 IsoTpFrameType 4-15;
SG_MUL_VAL_ 897 FirstData5 IsoTpFrameType 1-1;
SG_MUL_VAL_ 897 FlowPadding4 IsoTpFrameType 3-3;
SG_MUL_VAL_ 897 SingleData7 IsoTpFrameType 0-0;
SG_MUL_VAL_ 897 ConsecutiveData7 IsoTpFrameType 2-2;
SG_MUL_VAL_ 897 UnknownData7 IsoTpFrameType 4-15;
SG_MUL_VAL_ 897 FirstData6 IsoTpFrameType 1-1;
SG_MUL_VAL_ 897 FlowPadding5 IsoTpFrameType 3-3;
SG_MUL_VAL_ 928 SingleFrameLength IsoTpFrameType 0-0;
SG_MUL_VAL_ 928 FirstFrameLength IsoTpFrameType 1-1;
SG_MUL_VAL_ 928 ConsecutiveSequence IsoTpFrameType 2-2;
SG_MUL_VAL_ 928 FlowStatus IsoTpFrameType 3-3;
SG_MUL_VAL_ 928 UnknownPciLow IsoTpFrameType 4-15;
SG_MUL_VAL_ 928 BlockSize IsoTpFrameType 3-3;
SG_MUL_VAL_ 928 SingleData1 IsoTpFrameType 0-0;
SG_MUL_VAL_ 928 ConsecutiveData1 IsoTpFrameType 2-2;
SG_MUL_VAL_ 928 UnknownData1 IsoTpFrameType 4-15;
SG_MUL_VAL_ 928 SeparationTimeRaw IsoTpFrameType 3-3;
SG_MUL_VAL_ 928 SingleData2 IsoTpFrameType 0-0;
SG_MUL_VAL_ 928 ConsecutiveData2 IsoTpFrameType 2-2;
SG_MUL_VAL_ 928 UnknownData2 IsoTpFrameType 4-15;
SG_MUL_VAL_ 928 FirstData1 IsoTpFrameType 1-1;
SG_MUL_VAL_ 928 SingleData3 IsoTpFrameType 0-0;
SG_MUL_VAL_ 928 ConsecutiveData3 IsoTpFrameType 2-2;
SG_MUL_VAL_ 928 UnknownData3 IsoTpFrameType 4-15;
SG_MUL_VAL_ 928 FirstData2 IsoTpFrameType 1-1;
SG_MUL_VAL_ 928 FlowPadding1 IsoTpFrameType 3-3;
SG_MUL_VAL_ 928 SingleData4 IsoTpFrameType 0-0;
SG_MUL_VAL_ 928 ConsecutiveData4 IsoTpFrameType 2-2;
SG_MUL_VAL_ 928 UnknownData4 IsoTpFrameType 4-15;
SG_MUL_VAL_ 928 FirstData3 IsoTpFrameType 1-1;
SG_MUL_VAL_ 928 FlowPadding2 IsoTpFrameType 3-3;
SG_MUL_VAL_ 928 SingleData5 IsoTpFrameType 0-0;
SG_MUL_VAL_ 928 ConsecutiveData5 IsoTpFrameType 2-2;
SG_MUL_VAL_ 928 UnknownData5 IsoTpFrameType 4-15;
SG_MUL_VAL_ 928 FirstData4 IsoTpFrameType 1-1;
SG_MUL_VAL_ 928 FlowPadding3 IsoTpFrameType 3-3;
SG_MUL_VAL_ 928 SingleData6 IsoTpFrameType 0-0;
SG_MUL_VAL_ 928 ConsecutiveData6 IsoTpFrameType 2-2;
SG_MUL_VAL_ 928 UnknownData6 IsoTpFrameType 4-15;
SG_MUL_VAL_ 928 FirstData5 IsoTpFrameType 1-1;
SG_MUL_VAL_ 928 FlowPadding4 IsoTpFrameType 3-3;
SG_MUL_VAL_ 928 SingleData7 IsoTpFrameType 0-0;
SG_MUL_VAL_ 928 ConsecutiveData7 IsoTpFrameType 2-2;
SG_MUL_VAL_ 928 UnknownData7 IsoTpFrameType 4-15;
SG_MUL_VAL_ 928 FirstData6 IsoTpFrameType 1-1;
SG_MUL_VAL_ 928 FlowPadding5 IsoTpFrameType 3-3;
